VERSION ""

NS_ :

BS_:

BU_: VCU FCM

BO_ 1065 PKC_NM_0x429: 8 VCU
 SG_ PKC_SrcNodeID : 7|8@0+ (1,0) [0|127] ""  FCM
 SG_ PKC_CtrlBitVector_Bit0_RMR : 8|1@0+ (1,0) [0|1] ""  FCM
 SG_ PKC_CtrlBitVector_Bit1_Res : 9|1@0+ (1,0) [0|1] ""  FCM
 SG_ PKC_CtrlBitVector_Bit2_Res : 10|1@0+ (1,0) [0|1] ""  FCM
 SG_ PKC_CtrlBitVector_Bit3_NMCoord : 11|1@0+ (1,0) [0|1] ""  FCM
 SG_ PKC_CtrlBitVector_Bit4_ActWake : 12|1@0+ (1,0) [0|1] ""  FCM
 SG_ PKC_CtrlBitVector_Bit5_Res : 13|1@0+ (1,0) [0|1] ""  FCM
 SG_ PKC_CtrlBitVector_Bit6_PNI : 14|1@0+ (1,0) [0|1] ""  FCM
 SG_ PKC_CtrlBitVector_Bit7_Res : 15|1@0+ (1,0) [0|1] ""  FCM
 SG_ PKC_UsrData0 : 23|8@0+ (1,0) [0|255] ""  FCM
 SG_ PKC_UsrData1_Bit0_IGN_WAKEUP : 24|1@0+ (1,0) [0|1] ""  FCM
 SG_ PKC_UsrData1_Bit1_RESET_WAKEUP : 25|1@0+ (1,0) [0|1] ""  FCM
 SG_ PKC_UsrData1_Bit2_NETWORK_WAKEUP : 26|1@0+ (1,0) [0|1] ""  FCM
 SG_ PKC_UsrData1_Bit3_ECUSPEC_WAKEUP : 27|1@0+ (1,0) [0|1] ""  FCM
 SG_ PKC_UsrData1_Bit4_NETWORK_AWAKE : 28|1@0+ (1,0) [0|1] ""  FCM
 SG_ PKC_UsrData1_Bit5_IGNITION_AWAKE : 29|1@0+ (1,0) [0|1] ""  FCM
 SG_ PKC_UsrData1_Bit6_DIAGN_AWAKE : 30|1@0+ (1,0) [0|1] ""  FCM
 SG_ PKC_UsrData1_Bit7_ECUSPEC_AWAKE : 31|1@0+ (1,0) [0|1] ""  FCM
 SG_ PKC_UsrData2 : 39|8@0+ (1,0) [0|255] ""  FCM
 SG_ PKC_UsrData3 : 47|8@0+ (1,0) [0|255] ""  FCM
 SG_ PKC_UsrData4_PN_Info1 : 55|8@0+ (1,0) [0|255] ""  FCM
 SG_ PKC_UsrData5_PN_Info2 : 63|8@0+ (1,0) [0|255] ""  FCM

BO_ 1069 ADAS_NM_0x42D: 8 VCU
 SG_ ADAS_SrcNodeID : 7|8@0+ (1,0) [0|127] ""  FCM
 SG_ ADAS_CtrlBitVector_Bit0_RMR : 8|1@0+ (1,0) [0|1] ""  FCM
 SG_ ADAS_CtrlBitVector_Bit1_Res : 9|1@0+ (1,0) [0|1] ""  FCM
 SG_ ADAS_CtrlBitVector_Bit2_Res : 10|1@0+ (1,0) [0|1] ""  FCM
 SG_ ADAS_CtrlBitVector_Bit3_NMCoord : 11|1@0+ (1,0) [0|1] ""  FCM
 SG_ ADAS_CtrlBitVector_Bit4_ActWake : 12|1@0+ (1,0) [0|1] ""  FCM
 SG_ ADAS_CtrlBitVector_Bit5_Res : 13|1@0+ (1,0) [0|1] ""  FCM
 SG_ ADAS_CtrlBitVector_Bit6_PNI : 14|1@0+ (1,0) [0|1] ""  FCM
 SG_ ADAS_CtrlBitVector_Bit7_Res : 15|1@0+ (1,0) [0|1] ""  FCM
 SG_ ADAS_UsrData0 : 23|8@0+ (1,0) [0|255] ""  FCM
 SG_ ADAS_UsrData1_Bit0_IGN_WAKEUP : 24|1@0+ (1,0) [0|1] ""  FCM
 SG_ ADAS_UsrData1_Bit1_RESET_WAKEUP : 25|1@0+ (1,0) [0|1] ""  FCM
 SG_ ADAS_UsrData1_Bit2_NET_WKUP : 26|1@0+ (1,0) [0|1] ""  FCM
 SG_ ADAS_UsrData1_Bit3_ECUSPEC_WKUP : 27|1@0+ (1,0) [0|1] ""  FCM
 SG_ ADAS_UsrData1_Bit4_NETWORK_AWAKE : 28|1@0+ (1,0) [0|1] ""  FCM
 SG_ ADAS_UsrData1_Bit5_IGN_AWAKE : 29|1@0+ (1,0) [0|1] ""  FCM
 SG_ ADAS_UsrData1_Bit6_DIAGN_AWAKE : 30|1@0+ (1,0) [0|1] ""  FCM
 SG_ ADAS_UsrData1_Bit7_ECUSPEC_AWAKE : 31|1@0+ (1,0) [0|1] ""  FCM
 SG_ ADAS_UsrData2 : 39|8@0+ (1,0) [0|255] ""  FCM
 SG_ ADAS_UsrData3 : 47|8@0+ (1,0) [0|255] ""  FCM
 SG_ ADAS_UsrData4_PN_Info1 : 55|8@0+ (1,0) [0|255] ""  FCM
 SG_ ADAS_UsrData5_PN_Info2 : 63|8@0+ (1,0) [0|255] ""  FCM

BO_ 1070 FCM_NM_0x42E: 8 FCM
 SG_ FCM_SrcNodeID : 7|8@0+ (1,0) [0|127] ""  VCU
 SG_ FCM_CtrlBitVector_Bit0_RMR : 8|1@0+ (1,0) [0|1] ""  VCU
 SG_ FCM_CtrlBitVector_Bit1_Res : 9|1@0+ (1,0) [0|1] ""  VCU
 SG_ FCM_CtrlBitVector_Bit2_Res : 10|1@0+ (1,0) [0|1] ""  VCU
 SG_ FCM_CtrlBitVector_Bit3_NMCoord : 11|1@0+ (1,0) [0|1] ""  VCU
 SG_ FCM_CtrlBitVector_Bit4_ActWake : 12|1@0+ (1,0) [0|1] ""  VCU
 SG_ FCM_CtrlBitVector_Bit5_Res : 13|1@0+ (1,0) [0|1] ""  VCU
 SG_ FCM_CtrlBitVector_Bit6_PNI : 14|1@0+ (1,0) [0|1] ""  VCU
 SG_ FCM_CtrlBitVector_Bit7_Res : 15|1@0+ (1,0) [0|1] ""  VCU
 SG_ FCM_UsrData0 : 23|8@0+ (1,0) [0|255] ""  VCU
 SG_ FCM_UsrData1_Bit0_IGN_WAKEUP : 24|1@0+ (1,0) [0|1] ""  VCU
 SG_ FCM_UsrData1_Bit1_RESET_WAKEUP : 25|1@0+ (1,0) [0|1] ""  VCU
 SG_ FCM_UsrData1_Bit2_NETWORK_WAKEUP : 26|1@0+ (1,0) [0|1] ""  VCU
 SG_ FCM_UsrData1_Bit3_ECUSPEC_WAKEUP : 27|1@0+ (1,0) [0|1] ""  VCU
 SG_ FCM_UsrData1_Bit4_NETWORK_AWAKE : 28|1@0+ (1,0) [0|1] ""  VCU
 SG_ FCM_UsrData1_Bit5_IGNITION_AWAKE : 29|1@0+ (1,0) [0|1] ""  VCU
 SG_ FCM_UsrData1_Bit6_DIAGN_AWAKE : 30|1@0+ (1,0) [0|1] ""  VCU
 SG_ FCM_UsrData1_Bit7_ECUSPEC_AWAKE : 31|1@0+ (1,0) [0|1] ""  VCU
 SG_ FCM_UsrData2 : 39|8@0+ (1,0) [0|255] ""  VCU
 SG_ FCM_UsrData3 : 47|8@0+ (1,0) [0|255] ""  VCU
 SG_ FCM_UsrData4_PN_Info1 : 55|8@0+ (1,0) [0|255] ""  VCU
 SG_ FCM_UsrData5_PN_Info2 : 63|8@0+ (1,0) [0|255] ""  VCU

BO_ 1086 GW_NM_0x43E: 8 VCU
 SG_ GW_SrcNodeID : 7|8@0+ (1,0) [0|127] ""  FCM
 SG_ GW_CtrlBitVector_Bit0_RMR : 8|1@0+ (1,0) [0|1] ""  FCM
 SG_ GW_CtrlBitVector_Bit1_Res : 9|1@0+ (1,0) [0|1] ""  FCM
 SG_ GW_CtrlBitVector_Bit2_Res : 10|1@0+ (1,0) [0|1] ""  FCM
 SG_ GW_CtrlBitVector_Bit3_NMCoord : 11|1@0+ (1,0) [0|1] ""  FCM
 SG_ GW_CtrlBitVector_Bit4_ActWake : 12|1@0+ (1,0) [0|1] ""  FCM
 SG_ GW_CtrlBitVector_Bit5_Res : 13|1@0+ (1,0) [0|1] ""  FCM
 SG_ GW_CtrlBitVector_Bit6_PNI : 14|1@0+ (1,0) [0|1] ""  FCM
 SG_ GW_CtrlBitVector_Bit7_Res : 15|1@0+ (1,0) [0|1] ""  FCM
 SG_ GW_UsrData0 : 23|8@0+ (1,0) [0|255] ""  FCM
 SG_ GW_UsrData1_Bit0_IGN_WAKEUP : 24|1@0+ (1,0) [0|1] ""  FCM
 SG_ GW_UsrData1_Bit1_RESET_WAKEUP : 25|1@0+ (1,0) [0|1] ""  FCM
 SG_ GW_UsrData1_Bit2_NETWORK_WAKEUP : 26|1@0+ (1,0) [0|1] ""  FCM
 SG_ GW_UsrData1_Bit3_ECUSPEC_WAKEUP : 27|1@0+ (1,0) [0|1] ""  FCM
 SG_ GW_UsrData1_Bit4_NETWORK_AWAKE : 28|1@0+ (1,0) [0|1] ""  FCM
 SG_ GW_UsrData1_Bit5_IGNITION_AWAKE : 29|1@0+ (1,0) [0|1] ""  FCM
 SG_ GW_UsrData1_Bit6_DIAGN_AWAKE : 30|1@0+ (1,0) [0|1] ""  FCM
 SG_ GW_UsrData1_Bit7_ECUSPEC_AWAKE : 31|1@0+ (1,0) [0|1] ""  FCM
 SG_ GW_UsrData2 : 39|8@0+ (1,0) [0|255] ""  FCM
 SG_ GW_UsrData3 : 47|8@0+ (1,0) [0|255] ""  FCM
 SG_ GW_UsrData4_PN_Info1 : 55|8@0+ (1,0) [0|255] ""  FCM
 SG_ GW_UsrData5_PN_Info2 : 63|8@0+ (1,0) [0|255] ""  FCM

BO_ 1159 FCM_0x487: 8 FCM
 SG_ FCM_ComLostFlt_ESP : 0|1@0+ (1,0) [0|1] ""  VCU
 SG_ FCM_ComLostFlt_iBooster : 1|1@0+ (1,0) [0|1] ""  VCU
 SG_ FCM_ComLostFlt_EPS : 2|1@0+ (1,0) [0|1] ""  VCU
 SG_ FCM_ComLostFlt_YRS : 3|1@0+ (1,0) [0|1] ""  VCU
 SG_ FCM_ComLostFlt_BCM : 4|1@0+ (1,0) [0|1] ""  VCU
 SG_ FCM_ComLostFlt_ECC : 5|1@0+ (1,0) [0|1] ""  VCU
 SG_ FCM_ComLostFlt_TBOX : 6|1@0+ (1,0) [0|1] ""  VCU
 SG_ FCM_ComLostFlt_CIM : 7|1@0+ (1,0) [0|1] ""  VCU
 SG_ FCM_ComLostFlt_ICC : 8|1@0+ (1,0) [0|1] ""  VCU
 SG_ FCM_ComLostFlt_MRR : 9|1@0+ (1,0) [0|1] ""  VCU
 SG_ FCM_ComLostFlt_PEPS : 10|1@0+ (1,0) [0|1] ""  VCU
 SG_ FCM_ComLostFlt_ADAS : 11|1@0+ (1,0) [0|1] ""  VCU
 SG_ FCM_ComE2EFlt : 12|1@0+ (1,0) [0|1] ""  VCU
 SG_ FCM_ChkInvldSig_ESP : 13|1@0+ (1,0) [0|1] ""  VCU
 SG_ FCM_ChkInvldSig_iBooster : 14|1@0+ (1,0) [0|1] ""  VCU
 SG_ FCM_ChkInvldSig_EPS : 15|1@0+ (1,0) [0|1] ""  VCU
 SG_ FCM_ChkInvldSig_YRS : 16|1@0+ (1,0) [0|1] ""  VCU
 SG_ FCM_ChkInvldSig_CIM : 17|1@0+ (1,0) [0|1] ""  VCU
 SG_ FCM_ChkInvldSig_ECC : 18|1@0+ (1,0) [0|1] ""  VCU
 SG_ FCM_ChkInvldSig_PEPS : 19|1@0+ (1,0) [0|1] ""  VCU
 SG_ FCM_ChkInvldSig_ICC : 20|1@0+ (1,0) [0|1] ""  VCU
 SG_ FCM_ChkPrivateCANBusOff : 21|1@0+ (1,0) [0|1] ""  VCU
 SG_ FCM_ChkPublicCANBusOff : 22|1@0+ (1,0) [0|1] ""  VCU
 SG_ FCM_BattVoltBelowThd : 23|1@0+ (1,0) [0|1] ""  VCU
 SG_ FCM_BattVoltOverThd : 24|1@0+ (1,0) [0|1] ""  VCU
 SG_ FCM_CamBli : 25|1@0+ (1,0) [0|1] ""  VCU
 SG_ FCM_ECUTmpHiTProtn : 26|1@0+ (1,0) [0|1] ""  VCU
 SG_ FCM_IntCircOutpVoltBelowThd : 27|1@0+ (1,0) [0|1] ""  VCU
 SG_ FCM_IntCircOutpVoltOverThd : 28|1@0+ (1,0) [0|1] ""  VCU
 SG_ FCM_IntCircPrmntFlt : 29|1@0+ (1,0) [0|1] ""  VCU
 SG_ FCM_MatchParaErr : 30|1@0+ (1,0) [0|1] ""  VCU
 SG_ FCM_VehCfgInfoErr : 31|1@0+ (1,0) [0|1] ""  VCU
 SG_ FCM_IntCircFlt : 32|1@0+ (1,0) [0|1] ""  VCU
 SG_ FCM_DLCFlt_ESP : 33|1@0+ (1,0) [0|1] ""  VCU
 SG_ FCM_DLCFlt_iBooster : 34|1@0+ (1,0) [0|1] ""  VCU
 SG_ FCM_DLCFlt_EPS : 35|1@0+ (1,0) [0|1] ""  VCU
 SG_ FCM_DLCFlt_YRS : 36|1@0+ (1,0) [0|1] ""  VCU
 SG_ FCM_DLCFlt_BCM : 37|1@0+ (1,0) [0|1] ""  VCU
 SG_ FCM_DLCFlt_ECC : 38|1@0+ (1,0) [0|1] ""  VCU
 SG_ FCM_DLCFlt_TBOX : 39|1@0+ (1,0) [0|1] ""  VCU
 SG_ FCM_DLCFlt_CIM : 40|1@0+ (1,0) [0|1] ""  VCU
 SG_ FCM_DLCFlt_ICC : 41|1@0+ (1,0) [0|1] ""  VCU
 SG_ FCM_DLCFlt_MRR : 42|1@0+ (1,0) [0|1] ""  VCU
 SG_ FCM_DLCFlt_PEPS : 43|1@0+ (1,0) [0|1] ""  VCU
 SG_ FCM_DLCFlt_ADAS : 44|1@0+ (1,0) [0|1] ""  VCU
 SG_ FCM_OnlineCalOutOfRng : 45|1@0+ (1,0) [0|1] ""  VCU
 SG_ FCM_IniCalOutOfRng : 46|1@0+ (1,0) [0|1] ""  VCU
 SG_ FCM_IniCalTimeout : 47|1@0+ (1,0) [0|1] ""  VCU
 SG_ FCM_NotCal : 48|1@0+ (1,0) [0|1] ""  VCU
 SG_ FCM_OTARdy_Fb : 55|2@0+ (1,0) [0|3] ""  VCU

BO_ 1268 TBOX_0x4F4: 16 VCU
 SG_ TBOX_4F4_4F8_CheckSum : 7|8@0+ (1,0) [0|255] "" Vector__XXX
 SG_ TBOX_4F4_4F8_AliveCounter : 11|4@0+ (1,0) [0|14] "" Vector__XXX
 SG_ TBOX_Sw_upd : 13|2@0+ (1,0) [0|3] "" Vector__XXX
 SG_ TBOX_Flsflg : 18|3@0+ (1,0) [0|7] ""  FCM
 SG_ TBOX_RemFlsh : 21|3@0+ (1,0) [0|7] ""  FCM
 SG_ TBOX_FobdGWPartBUSUDSCom : 23|2@0+ (1,0) [0|3] "" Vector__XXX
 SG_ TBOX_RemChrgInsulFctReq : 25|2@0+ (1,0) [0|3] "" Vector__XXX
 SG_ TBOX_EHUSetTrvlMod : 27|2@0+ (1,0) [0|3] "" Vector__XXX
 SG_ TBOX_ResvACChrgOpenSts : 29|2@0+ (1,0) [0|3] "" Vector__XXX
 SG_ TBOX_RemKL15PwrOnReq : 31|2@0+ (1,0) [0|3] "" Vector__XXX
 SG_ TBOX_SetChrgEndSOC : 38|7@0+ (1,0) [0|100] "%" Vector__XXX
 SG_ TBOX_PreCondTriggerReq : 42|3@0+ (1,0) [0|7] "" Vector__XXX
 SG_ TBOX_BlowLvlReq : 45|3@0+ (1,0) [0|7] "" Vector__XXX
 SG_ TBOX_ICC_UpdStrt : 47|2@0+ (1,0) [0|3] "" Vector__XXX
 SG_ TBOX_VehiMod : 51|4@0+ (1,0) [0|15] "" Vector__XXX
 SG_ TBOX_Crash_cfm : 53|2@0+ (1,0) [0|3] "" Vector__XXX
 SG_ TBOX_SchedChrgnReq : 57|2@0+ (1,0) [0|3] "" Vector__XXX
 SG_ TBOX_4F4_SSecOC_Fresh_Byte0 : 71|8@0+ (1,0) [0|255] "" Vector__XXX
 SG_ TBOX_4F4_SSecOC_MAC_Byte0 : 79|8@0+ (1,0) [0|255] "" Vector__XXX
 SG_ TBOX_4F4_SSecOC_MAC_Byte1 : 87|8@0+ (1,0) [0|255] "" Vector__XXX
 SG_ TBOX_4F4_SSecOC_MAC_Byte2 : 95|8@0+ (1,0) [0|255] "" Vector__XXX

BO_ 1287 VCU_0x507: 8 VCU
 SG_ VCU_OTAVehInhb_QM_Fb : 5|2@0+ (1,0) [0|3] ""  FCM
 SG_ VCU_OTAVehCdnChk_QM_sts : 7|2@0+ (1,0) [0|3] ""  FCM
 SG_ VCU_DrvAvl : 8|1@0+ (1,0) [0|1] "" Vector__XXX
 SG_ VCU_CllsnSigSts : 9|1@0+ (1,0) [0|1] "" Vector__XXX
 SG_ VCU_VehSts_GB : 13|2@0+ (1,0) [0|3] "" Vector__XXX
 SG_ VCU_MCUOverTFlt_GB : 14|1@0+ (1,0) [0|1] "" Vector__XXX
 SG_ VCU_DrvrMotOverTFlt_GB : 15|1@0+ (1,0) [0|1] "" Vector__XXX
 SG_ VCU_SOCTooLoAlrm : 16|1@0+ (1,0) [0|1] "" Vector__XXX
 SG_ VCU_SOCJumpAlrm : 17|1@0+ (1,0) [0|1] "" Vector__XXX
 SG_ VCU_PwrBattPackMismatAlrm : 18|1@0+ (1,0) [0|1] "" Vector__XXX
 SG_ VCU_SOCTooHiAlrm : 19|1@0+ (1,0) [0|1] "" Vector__XXX
 SG_ VCU_DCDCEnaCmd : 20|1@0+ (1,0) [0|1] "" Vector__XXX
 SG_ VCU_PwrBattECCEnaCmd : 22|1@0+ (1,0) [0|1] "" Vector__XXX
 SG_ VCU_MstRlyCtrlCmd : 23|1@0+ (1,0) [0|1] "" Vector__XXX
 SG_ VCU_DCDCOutpVoltCmd : 31|8@0+ (0.1,0) [0|25.5] "V" Vector__XXX
 SG_ VCU_CCCnctnVolt : 39|8@0+ (0.1,0) [0|25.5] "V" Vector__XXX
 SG_ VCU_GearSig_GB : 43|4@0+ (1,0) [0|15] "" Vector__XXX
 SG_ VCU_DrvrMotNr_GB : 47|4@0+ (1,0) [0|15] "" Vector__XXX
 SG_ VCU_BattVolt : 55|16@0+ (0.001,0) [0|65.535] "V"  FCM

BO_ 1297 VCU_0x511: 8 VCU
 SG_ VCU_BMSLVWakeUpSts : 0|1@0+ (1,0) [0|1] "" Vector__XXX
 SG_ VCU_ONWakeUpSig : 1|1@0+ (1,0) [0|1] "" Vector__XXX
 SG_ VCU_FCWakeUpSig : 2|1@0+ (1,0) [0|1] "" Vector__XXX
 SG_ VCU_SCWakeUpSig : 3|1@0+ (1,0) [0|1] "" Vector__XXX
 SG_ VCU_RemWakeUpSig : 4|1@0+ (1,0) [0|1] "" Vector__XXX
 SG_ VCU_NetWakeUpSig : 5|1@0+ (1,0) [0|1] "" Vector__XXX
 SG_ VCU_LVWakeUpSts_PDU : 6|1@0+ (1,0) [0|1] "" Vector__XXX
 SG_ VCU_VehEOLFctFlg : 7|1@0+ (1,0) [0|1] "" Vector__XXX
 SG_ VCU_LVWakeUpSts_MCU : 8|1@0+ (1,0) [0|1] "" Vector__XXX
 SG_ VCU_PwrAntithefAllwtRdyFlg : 9|1@0+ (1,0) [0|1] "" Vector__XXX
 SG_ VCU_LVWakeUpSts_CCU : 10|1@0+ (1,0) [0|1] "" Vector__XXX
 SG_ VCU_RemECCEndCmd : 11|1@0+ (1,0) [0|1] "" Vector__XXX
 SG_ VCU_EvChrgElectcLockCtrlCmd : 13|2@0+ (1,0) [0|3] "" Vector__XXX
 SG_ VCU_RemPwrBattHeatgEndCmd : 14|1@0+ (1,0) [0|1] "" Vector__XXX
 SG_ VCU_RemChrgEndCmd : 15|1@0+ (1,0) [0|1] "" Vector__XXX
 SG_ VCU_V2L_TrAvl : 16|1@0+ (1,0) [0|1] "" Vector__XXX
 SG_ VCU_RemBattHeatgFailReason : 19|3@0+ (1,0) [0|7] "" Vector__XXX
 SG_ VCU_RemECCEndReason : 22|3@0+ (1,0) [0|7] "" Vector__XXX
 SG_ VCU_V2L_ChrgPortAvl : 23|1@0+ (1,0) [0|1] "" Vector__XXX
 SG_ VCU_RemChrgEndReason : 26|3@0+ (1,0) [0|7] "" Vector__XXX
 SG_ VCU_SchedChrgnStsFb : 28|2@0+ (1,0) [0|3] "" Vector__XXX
 SG_ VCU_V2V_Avl : 29|1@0+ (1,0) [0|1] "" Vector__XXX
 SG_ VCU_V2H_Avl : 30|1@0+ (1,0) [0|1] "" Vector__XXX
 SG_ VCU_V2G_Avl : 31|1@0+ (1,0) [0|1] "" Vector__XXX
 SG_ VCU_VehMod : 39|4@0+ (1,0) [0|15] ""  FCM
 SG_ VCU_VehCrtChrgEndSOC : 46|7@0+ (1,0) [0|100] "%" Vector__XXX
 SG_ VCU_CalSwVers : 52|5@0+ (1,0) [0|31] "" Vector__XXX
 SG_ VCU_RemPwrBattPreheatgEndFlg : 53|1@0+ (1,0) [0|1] "" Vector__XXX
 SG_ VCU_VehOperMod : 60|5@0+ (1,0) [0|31] "" Vector__XXX
 SG_ VCU_VehRemRefrshModReq : 62|2@0+ (1,0) [0|3] "" Vector__XXX
 SG_ VCU_RemDTCPwrOnReq : 63|1@0+ (1,0) [0|1] "" Vector__XXX

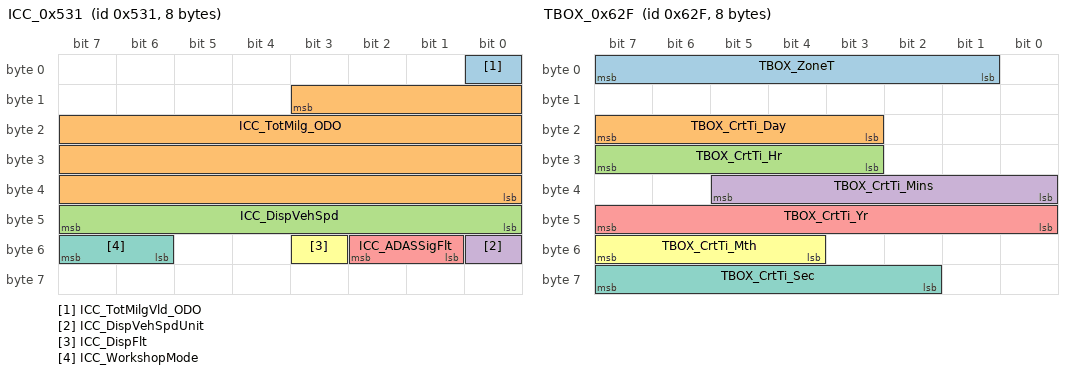
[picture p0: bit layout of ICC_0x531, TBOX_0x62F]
BO_ 1329 ICC_0x531: 8 VCU
 SG_ ICC_TotMilgVld_ODO : 0|1@0+ (1,0) [0|1] ""  FCM
 SG_ ICC_TotMilg_ODO : 11|28@0+ (0.01,0) [0|2000000] "km"  FCM
 SG_ ICC_DispVehSpd : 47|8@0+ (1,0) [0|255] ""  FCM
 SG_ ICC_DispVehSpdUnit : 48|1@0+ (1,0) [0|1] ""  FCM
 SG_ ICC_ADASSigFlt : 50|2@0+ (1,0) [0|3] ""  FCM
 SG_ ICC_DispFlt : 51|1@0+ (1,0) [0|1] ""  FCM
 SG_ ICC_WorkshopMode : 55|2@0+ (1,0) [0|3] "" Vector__XXX

BO_ 1476 TBOX_0x5C4: 16 VCU
 SG_ TBOX_OTA_ownCondchk : 1|2@0+ (1,0) [0|3] ""  FCM
 SG_ TBOX_TerminalRemWakeupSig : 2|1@0+ (1,0) [0|1] "" Vector__XXX
 SG_ TBOX_RemSCModReq : 4|2@0+ (1,0) [0|3] "" Vector__XXX
 SG_ TBOX_RemPwrBattOpenHeatgReq : 6|2@0+ (1,0) [0|3] "" Vector__XXX
 SG_ TBOX_RemPwrBattResvHeatgReq : 7|1@0+ (1,0) [0|1] "" Vector__XXX
 SG_ TBOX_RemInsdInfoDispEna : 12|1@0+ (1,0) [0|1] "" Vector__XXX
 SG_ TBOX_RemECCDefrstModReq : 14|2@0+ (1,0) [0|3] "" Vector__XXX
 SG_ TBOX_RemECCResvDefrstReq : 15|1@0+ (1,0) [0|1] "" Vector__XXX
 SG_ TBOX_RemECCSetT : 31|8@0+ (0.5,0) [0|127.5] "Degree Celsius" Vector__XXX
 SG_ TBOX_RemResvECCSetT : 39|8@0+ (0.5,0) [0|127.5] "Degree Celsius" Vector__XXX
 SG_ TBOX_RemSOCMax : 47|8@0+ (1,0) [0|100] "" Vector__XXX
 SG_ TBOX_4GSigIND : 49|2@0+ (1,0) [0|3] "" Vector__XXX
 SG_ TBOX_Conn_Typ : 52|3@0+ (1,0) [0|7] "" Vector__XXX
 SG_ TBOX_TSPNotConn : 53|1@0+ (1,0) [0|1] "" Vector__XXX
 SG_ TBOX_EHUNotCONN : 54|1@0+ (1,0) [0|1] "" Vector__XXX
 SG_ TBOX_WIFIError : 55|1@0+ (1,0) [0|1] "" Vector__XXX
 SG_ TBOX_InnerBattError : 56|1@0+ (1,0) [0|1] "" Vector__XXX
 SG_ TBOX_VoltLow : 57|1@0+ (1,0) [0|1] "" Vector__XXX
 SG_ TBOX_VoltHigh : 58|1@0+ (1,0) [0|1] "" Vector__XXX
 SG_ TBOX_4GLoss : 59|1@0+ (1,0) [0|1] "" Vector__XXX
 SG_ TBOX_RemSWH_Req : 61|2@0+ (1,0) [0|3] "" Vector__XXX
 SG_ TBOX_OTAInhbReq : 63|2@0+ (1,0) [0|3] "" Vector__XXX
 SG_ TBOX_5C4_SSecOC_Fresh_Byte0 : 71|8@0+ (1,0) [0|255] "" Vector__XXX
 SG_ TBOX_5C4_SSecOC_MAC_Byte0 : 79|8@0+ (1,0) [0|255] "" Vector__XXX
 SG_ TBOX_5C4_SSecOC_MAC_Byte1 : 87|8@0+ (1,0) [0|255] "" Vector__XXX
 SG_ TBOX_5C4_SSecOC_MAC_Byte2 : 95|8@0+ (1,0) [0|255] "" Vector__XXX

BO_ 1583 TBOX_0x62F: 8 VCU
 SG_ TBOX_ZoneT : 7|7@0+ (15,-720) [-720|1185] "min" Vector__XXX
 SG_ TBOX_CrtTi_Day : 23|5@0+ (1,1) [1|31] "day"  FCM
 SG_ TBOX_CrtTi_Hr : 31|5@0+ (1,0) [0|23] "hour"  FCM
 SG_ TBOX_CrtTi_Mins : 37|6@0+ (1,0) [0|59] "mintue"  FCM
 SG_ TBOX_CrtTi_Yr : 47|8@0+ (1,2015) [2015|2270] "year"  FCM
 SG_ TBOX_CrtTi_Mth : 55|4@0+ (1,1) [1|12] "month"  FCM
 SG_ TBOX_CrtTi_Sec : 63|6@0+ (1,0) [0|59] "second"  FCM

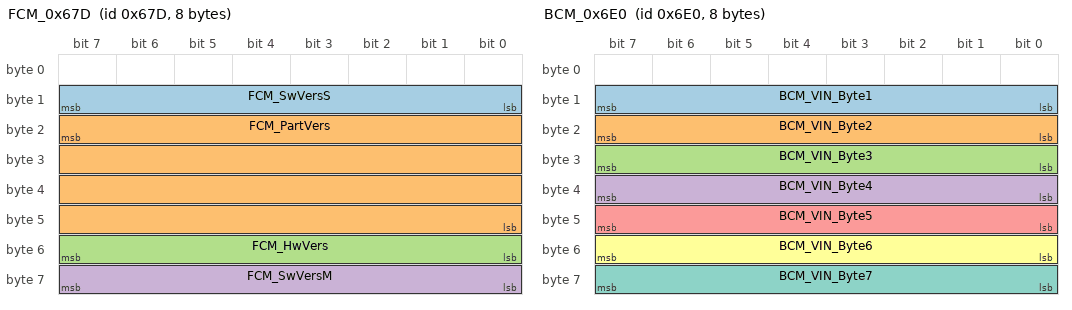
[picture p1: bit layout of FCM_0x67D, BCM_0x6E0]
BO_ 1661 FCM_0x67D: 8 FCM
 SG_ FCM_SwVersS : 15|8@0+ (1,0) [0|255] ""  VCU
 SG_ FCM_PartVers : 23|32@0+ (1,0) [0|4294967295] ""  VCU
 SG_ FCM_HwVers : 55|8@0+ (1,0) [0|255] ""  VCU
 SG_ FCM_SwVersM : 63|8@0+ (1,0) [0|255] ""  VCU

BO_ 1760 BCM_0x6E0: 8 VCU
 SG_ BCM_VIN_Byte1 : 15|8@0+ (1,0) [0|255] ""  FCM
 SG_ BCM_VIN_Byte2 : 23|8@0+ (1,0) [0|255] ""  FCM
 SG_ BCM_VIN_Byte3 : 31|8@0+ (1,0) [0|255] ""  FCM
 SG_ BCM_VIN_Byte4 : 39|8@0+ (1,0) [0|255] ""  FCM
 SG_ BCM_VIN_Byte5 : 47|8@0+ (1,0) [0|255] ""  FCM
 SG_ BCM_VIN_Byte6 : 55|8@0+ (1,0) [0|255] ""  FCM
 SG_ BCM_VIN_Byte7 : 63|8@0+ (1,0) [0|255] ""  FCM

BO_ 1765 VCU_0x6E5: 8 VCU
 SG_ VCU_VINCod1 : 7|64@0+ (1,0) [0|16777215] ""  FCM

BO_ 1766 VCU_0x6E6: 8 VCU
 SG_ VCU_VINCod2 : 7|64@0+ (1,0) [0|16777215] ""  FCM

BO_ 1767 VCU_0x6E7: 8 VCU
 SG_ VCU_VINCod3 : 7|64@0+ (1,0) [0|16777215] ""  FCM

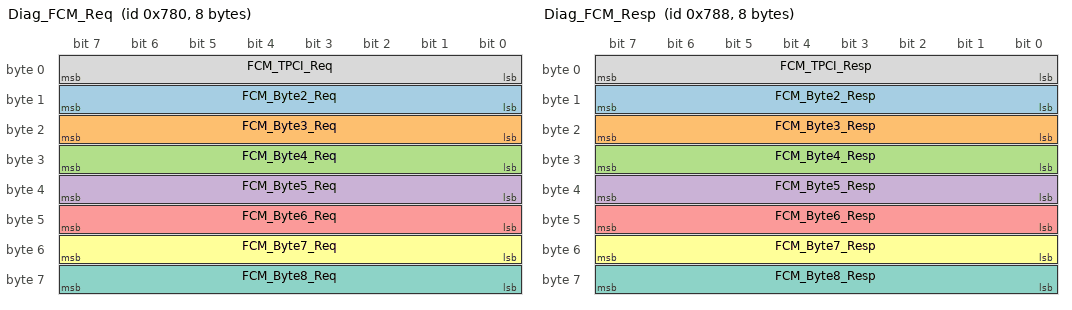
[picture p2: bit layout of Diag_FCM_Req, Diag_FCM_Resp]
BO_ 1920 Diag_FCM_Req: 8 VCU
 SG_ FCM_Byte2_Req : 15|8@0+ (1,0) [0|255] ""  FCM
 SG_ FCM_Byte3_Req : 23|8@0+ (1,0) [0|255] ""  FCM
 SG_ FCM_Byte4_Req : 31|8@0+ (1,0) [0|255] ""  FCM
 SG_ FCM_Byte5_Req : 39|8@0+ (1,0) [0|255] ""  FCM
 SG_ FCM_Byte6_Req : 47|8@0+ (1,0) [0|255] ""  FCM
 SG_ FCM_Byte7_Req : 55|8@0+ (1,0) [0|255] ""  FCM
 SG_ FCM_Byte8_Req : 63|8@0+ (1,0) [0|255] ""  FCM
 SG_ FCM_TPCI_Req : 7|8@0+ (1,0) [0|255] ""  FCM

BO_ 1928 Diag_FCM_Resp: 8 FCM
 SG_ FCM_Byte2_Resp : 15|8@0+ (1,0) [0|255] ""  VCU
 SG_ FCM_Byte3_Resp : 23|8@0+ (1,0) [0|255] ""  VCU
 SG_ FCM_Byte4_Resp : 31|8@0+ (1,0) [0|255] ""  VCU
 SG_ FCM_Byte5_Resp : 39|8@0+ (1,0) [0|255] ""  VCU
 SG_ FCM_Byte6_Resp : 47|8@0+ (1,0) [0|255] ""  VCU
 SG_ FCM_Byte7_Resp : 55|8@0+ (1,0) [0|255] ""  VCU
 SG_ FCM_Byte8_Resp : 63|8@0+ (1,0) [0|255] ""  VCU
 SG_ FCM_TPCI_Resp : 7|8@0+ (1,0) [0|255] ""  VCU

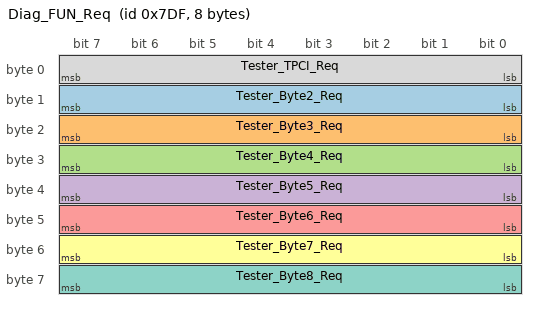
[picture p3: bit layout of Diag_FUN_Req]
BO_ 2015 Diag_FUN_Req: 8 VCU
 SG_ Tester_Byte2_Req : 15|8@0+ (1,0) [0|255] ""  FCM
 SG_ Tester_Byte3_Req : 23|8@0+ (1,0) [0|255] ""  FCM
 SG_ Tester_Byte4_Req : 31|8@0+ (1,0) [0|255] ""  FCM
 SG_ Tester_Byte5_Req : 39|8@0+ (1,0) [0|255] ""  FCM
 SG_ Tester_Byte6_Req : 47|8@0+ (1,0) [0|255] ""  FCM
 SG_ Tester_Byte7_Req : 55|8@0+ (1,0) [0|255] ""  FCM
 SG_ Tester_Byte8_Req : 63|8@0+ (1,0) [0|255] ""  FCM
 SG_ Tester_TPCI_Req : 7|8@0+ (1,0) [0|255] ""  FCM

CM_ SG_ 1065 PKC_SrcNodeID "Network Management Signal";
CM_ SG_ 1065 PKC_CtrlBitVector_Bit0_RMR "Network Management Signal: Repeat Message Request";
CM_ SG_ 1065 PKC_CtrlBitVector_Bit1_Res "Network Management Signal: Reserved (Legacy NM Coordinator ID) LowByte";
CM_ SG_ 1065 PKC_CtrlBitVector_Bit2_Res "Network Management Signal: Reserved (Legacy NM Coordinator ID) HighByte";
CM_ SG_ 1065 PKC_CtrlBitVector_Bit3_NMCoord "Network Management Signal: NM Coordinator Sleep Bit";
CM_ SG_ 1065 PKC_CtrlBitVector_Bit4_ActWake "Network Management Signal: Active Wakeup Bit";
CM_ SG_ 1065 PKC_CtrlBitVector_Bit5_Res "Network Management Signal: Reserved";
CM_ SG_ 1065 PKC_CtrlBitVector_Bit6_PNI "Network Management Signal: Partial Network Information Bit (PNI)";
CM_ SG_ 1065 PKC_CtrlBitVector_Bit7_Res "Network Management Signal: Reserved";
CM_ SG_ 1065 PKC_UsrData0 "The first user data byte determines the functionality of user data.This value is used as a constant that determines how the remaining three user data bytes are interpret the content of the remaining three user data bytes.";
CM_ SG_ 1065 PKC_UsrData1_Bit0_IGN_WAKEUP "Network Management Signal: ECU was power off or Bus sleep mode and started by Ignition turn on";
CM_ SG_ 1065 PKC_UsrData1_Bit1_RESET_WAKEUP "Network Management Signal: If ECU was already awake, in Prepare Bus Sleep or Ready Sleep mode and re-started by an internal or an external reset.";
CM_ SG_ 1065 PKC_UsrData1_Bit2_NETWORK_WAKEUP "Network Management Signal: ECU was in Power off, Bus Sleep, Prepare Bus Sleep or Ready Sleep Mode and then re-started by a network communication.";
CM_ SG_ 1065 PKC_UsrData1_Bit3_ECUSPEC_WAKEUP "Network Management Signal: ECU was in power off, Bus Sleep, Prepare Bus Sleep or Ready Sleep mode or awake and re- started by ECU-specific reason (e.g. pressed Button, timer, etc.)";
CM_ SG_ 1065 PKC_UsrData1_Bit4_NETWORK_AWAKE "Network Management Signal: ECU need network communication and keeps the network awake";
CM_ SG_ 1065 PKC_UsrData1_Bit5_IGNITION_AWAKE "Network Management Signal: ECU can?t release communication because Ignition is turn on";
CM_ SG_ 1065 PKC_UsrData1_Bit6_DIAGN_AWAKE "Network Management Signal: ECU need communication for diagnostic purpose and keeps network awake.";
CM_ SG_ 1065 PKC_UsrData1_Bit7_ECUSPEC_AWAKE "Network Management Signal: ECU keeps the network awake for ECU-define reasons for which communication is needed";
CM_ SG_ 1065 PKC_UsrData2 "Network Management Signal";
CM_ SG_ 1065 PKC_UsrData3 "Network Management Signal";
CM_ SG_ 1065 PKC_UsrData4_PN_Info1 "Network Management Signal";
CM_ SG_ 1065 PKC_UsrData5_PN_Info2 "Network Management Signal";
CM_ SG_ 1069 ADAS_SrcNodeID "Network Management Signal";
CM_ SG_ 1069 ADAS_CtrlBitVector_Bit0_RMR "Network Management Signal: Repeat Message Request";
CM_ SG_ 1069 ADAS_CtrlBitVector_Bit1_Res "Network Management Signal: Reserved (Legacy NM Coordinator ID) LowByte";
CM_ SG_ 1069 ADAS_CtrlBitVector_Bit2_Res "Network Management Signal: Reserved (Legacy NM Coordinator ID) HighByte";
CM_ SG_ 1069 ADAS_CtrlBitVector_Bit3_NMCoord "Network Management Signal: NM Coordinator Sleep Bit";
CM_ SG_ 1069 ADAS_CtrlBitVector_Bit4_ActWake "Network Management Signal: Active Wakeup Bit";
CM_ SG_ 1069 ADAS_CtrlBitVector_Bit5_Res "Network Management Signal: Reserved";
CM_ SG_ 1069 ADAS_CtrlBitVector_Bit6_PNI "Network Management Signal: Partial Network Information Bit (PNI)";
CM_ SG_ 1069 ADAS_CtrlBitVector_Bit7_Res "Network Management Signal: Reserved";
CM_ SG_ 1069 ADAS_UsrData0 "The first user data byte determines the functionality of user data.This value is used as a constant that determines how the remaining three user data bytes are interpret the content of the remaining three user data bytes.";
CM_ SG_ 1069 ADAS_UsrData1_Bit0_IGN_WAKEUP "Network Management Signal: ECU was power off or Bus sleep mode and started by Ignition turn on";
CM_ SG_ 1069 ADAS_UsrData1_Bit1_RESET_WAKEUP "Network Management Signal: If ECU was already awake, in Prepare Bus Sleep or Ready Sleep mode and re-started by an internal or an external reset.";
CM_ SG_ 1069 ADAS_UsrData1_Bit2_NET_WKUP "Network Management Signal: ECU was in Power off, Bus Sleep, Prepare Bus Sleep or Ready Sleep Mode and then re-started by a network communication.";
CM_ SG_ 1069 ADAS_UsrData1_Bit3_ECUSPEC_WKUP "Network Management Signal: ECU was in power off, Bus Sleep, Prepare Bus Sleep or Ready Sleep mode or awake and re- started by ECU-specific reason (e.g. pressed Button, timer, etc.)";
CM_ SG_ 1069 ADAS_UsrData1_Bit4_NETWORK_AWAKE "Network Management Signal: ECU need network communication and keeps the network awake";
CM_ SG_ 1069 ADAS_UsrData1_Bit5_IGN_AWAKE "Network Management Signal: ECU can?t release communication because Ignition is turn on";
CM_ SG_ 1069 ADAS_UsrData1_Bit6_DIAGN_AWAKE "Network Management Signal: ECU need communication for diagnostic purpose and keeps network awake.";
CM_ SG_ 1069 ADAS_UsrData1_Bit7_ECUSPEC_AWAKE "Network Management Signal: ECU keeps the network awake for ECU-define reasons for which communication is needed";
CM_ SG_ 1069 ADAS_UsrData2 "Network Management Signal";
CM_ SG_ 1069 ADAS_UsrData3 "Network Management Signal";
CM_ SG_ 1069 ADAS_UsrData4_PN_Info1 "Network Management Signal";
CM_ SG_ 1069 ADAS_UsrData5_PN_Info2 "Network Management Signal";
CM_ BO_ 1070 "Tx Rate is 64 ms.";
CM_ SG_ 1070 FCM_SrcNodeID "Network Management Signal";
CM_ SG_ 1070 FCM_CtrlBitVector_Bit0_RMR "Network Management Signal: Repeat Message Request";
CM_ SG_ 1070 FCM_CtrlBitVector_Bit1_Res "Network Management Signal: Reserved (Legacy NM Coordinator ID) LowByte";
CM_ SG_ 1070 FCM_CtrlBitVector_Bit2_Res "Network Management Signal: Reserved (Legacy NM Coordinator ID) HighByte";
CM_ SG_ 1070 FCM_CtrlBitVector_Bit3_NMCoord "Network Management Signal: NM Coordinator Sleep Bit";
CM_ SG_ 1070 FCM_CtrlBitVector_Bit4_ActWake "Network Management Signal: Active Wakeup Bit";
CM_ SG_ 1070 FCM_CtrlBitVector_Bit5_Res "Network Management Signal: Reserved";
CM_ SG_ 1070 FCM_CtrlBitVector_Bit6_PNI "Network Management Signal: Partial Network Information Bit (PNI)";
CM_ SG_ 1070 FCM_CtrlBitVector_Bit7_Res "Network Management Signal: Reserved";
CM_ SG_ 1070 FCM_UsrData0 "The first user data byte determines the functionality of user data.This value is used as a constant that determines how the remaining three user data bytes are interpret the content of the remaining three user data bytes.";
CM_ SG_ 1070 FCM_UsrData1_Bit0_IGN_WAKEUP "Network Management Signal: ECU was power off or Bus sleep mode and started by Ignition turn on";
CM_ SG_ 1070 FCM_UsrData1_Bit1_RESET_WAKEUP "Network Management Signal: If ECU was already awake, in Prepare Bus Sleep or Ready Sleep mode and re-started by an internal or an external reset.";
CM_ SG_ 1070 FCM_UsrData1_Bit2_NETWORK_WAKEUP "Network Management Signal: ECU was in Power off, Bus Sleep, Prepare Bus Sleep or Ready Sleep Mode and then re-started by a network communication.";
CM_ SG_ 1070 FCM_UsrData1_Bit3_ECUSPEC_WAKEUP "Network Management Signal: ECU was in power off, Bus Sleep, Prepare Bus Sleep or Ready Sleep mode or awake and re- started by ECU-specific reason (e.g. pressed Button, timer, etc.)";
CM_ SG_ 1070 FCM_UsrData1_Bit4_NETWORK_AWAKE "Network Management Signal: ECU need network communication and keeps the network awake";
CM_ SG_ 1070 FCM_UsrData1_Bit5_IGNITION_AWAKE "Network Management Signal: ECU can?t release communication because Ignition is turn on";
CM_ SG_ 1070 FCM_UsrData1_Bit6_DIAGN_AWAKE "Network Management Signal: ECU need communication for diagnostic purpose and keeps network awake.";
CM_ SG_ 1070 FCM_UsrData1_Bit7_ECUSPEC_AWAKE "Network Management Signal: ECU keeps the network awake for ECU-define reasons for which communication is needed";
CM_ SG_ 1070 FCM_UsrData2 "Network Management Signal";
CM_ SG_ 1070 FCM_UsrData3 "Network Management Signal";
CM_ SG_ 1070 FCM_UsrData4_PN_Info1 "Network Management Signal";
CM_ SG_ 1070 FCM_UsrData5_PN_Info2 "Network Management Signal";
CM_ BO_ 1086 "Tx Rate is 64 ms.";
CM_ SG_ 1086 GW_SrcNodeID "Network Management Signal";
CM_ SG_ 1086 GW_CtrlBitVector_Bit0_RMR "Network Management Signal: Repeat Message Request";
CM_ SG_ 1086 GW_CtrlBitVector_Bit1_Res "Network Management Signal: Reserved (Legacy NM Coordinator ID) LowByte";
CM_ SG_ 1086 GW_CtrlBitVector_Bit2_Res "Network Management Signal: Reserved (Legacy NM Coordinator ID) HighByte";
CM_ SG_ 1086 GW_CtrlBitVector_Bit3_NMCoord "Network Management Signal: NM Coordinator Sleep Bit";
CM_ SG_ 1086 GW_CtrlBitVector_Bit4_ActWake "Network Management Signal: Active Wakeup Bit";
CM_ SG_ 1086 GW_CtrlBitVector_Bit5_Res "Network Management Signal: Reserved";
CM_ SG_ 1086 GW_CtrlBitVector_Bit6_PNI "Network Management Signal: Partial Network Information Bit (PNI)";
CM_ SG_ 1086 GW_CtrlBitVector_Bit7_Res "Network Management Signal: Reserved";
CM_ SG_ 1086 GW_UsrData0 "The first user data byte determines the functionality of user data.This value is used as a constant that determines how the remaining three user data bytes are interpret the content of the remaining three user data bytes.";
CM_ SG_ 1086 GW_UsrData1_Bit0_IGN_WAKEUP "Network Management Signal: ECU was power off or Bus sleep mode and started by Ignition turn on";
CM_ SG_ 1086 GW_UsrData1_Bit1_RESET_WAKEUP "Network Management Signal: If ECU was already awake, in Prepare Bus Sleep or Ready Sleep mode and re-started by an internal or an external reset.";
CM_ SG_ 1086 GW_UsrData1_Bit2_NETWORK_WAKEUP "Network Management Signal: ECU was in Power off, Bus Sleep, Prepare Bus Sleep or Ready Sleep Mode and then re-started by a network communication.";
CM_ SG_ 1086 GW_UsrData1_Bit3_ECUSPEC_WAKEUP "Network Management Signal: ECU was in power off, Bus Sleep, Prepare Bus Sleep or Ready Sleep mode or awake and re- started by ECU-specific reason (e.g. pressed Button, timer, etc.)";
CM_ SG_ 1086 GW_UsrData1_Bit4_NETWORK_AWAKE "Network Management Signal: ECU need network communication and keeps the network awake";
CM_ SG_ 1086 GW_UsrData1_Bit5_IGNITION_AWAKE "Network Management Signal: ECU can’t release communication because Ignition is turn on";
CM_ SG_ 1086 GW_UsrData1_Bit6_DIAGN_AWAKE "Network Management Signal: ECU need communication for diagnostic purpose and keeps network awake.";
CM_ SG_ 1086 GW_UsrData1_Bit7_ECUSPEC_AWAKE "Network Management Signal: ECU keeps the network awake for ECU-define reasons for which communication is needed";
CM_ SG_ 1086 GW_UsrData2 "Network Management Signal";
CM_ SG_ 1086 GW_UsrData3 "Network Management Signal";
CM_ SG_ 1086 GW_UsrData4_PN_Info1 "Network Management Signal";
CM_ SG_ 1086 GW_UsrData5_PN_Info2 "Network Management Signal";
CM_ SG_ 1159 FCM_ComLostFlt_ESP "Malle_U30CF87_E00";
CM_ SG_ 1159 FCM_ComLostFlt_iBooster "Missed communication between FCM and iBooster_U30E287_E00";
CM_ SG_ 1159 FCM_ComLostFlt_EPS "FCM and EPS communication loss faila_U30CC87_E00";
CM_ SG_ 1159 FCM_ComLostFlt_YRS "Malfunction of loss of FCM and YRS communication_U30E387_E00";
CM_ SG_ 1159 FCM_ComLostFlt_BCM "Fail lost communication between FCM and BCM_U30C487_E00";
CM_ SG_ 1159 FCM_ComLostFlt_ECC "Lost communication between FCM and ECC_U30E487_E00";
CM_ SG_ 1159 FCM_ComLostFlt_TBOX "Fail loss of FCM and TBOX communication_U30D887_E00";
CM_ SG_ 1159 FCM_ComLostFlt_CIM "Fail loss of FCM and CIM communication_U30E587_E00";
CM_ SG_ 1159 FCM_ComLostFlt_ICC "Malfunction of lost communication between FCM and ICC_U30E687_E00";
CM_ SG_ 1159 FCM_ComLostFlt_MRR "Fail loss of FCM and MRR communication_U30EA87_E00";
CM_ SG_ 1159 FCM_ComLostFlt_PEPS "Missing communication failure between FCM and PEPS_U30E787_E00";
CM_ SG_ 1159 FCM_ComLostFlt_ADAS "Fail loss of communication between FCM and ADAS_U30EB87_E00";
CM_ SG_ 1159 FCM_ComE2EFlt "FCM communication check fault_C10E08_E00";
CM_ SG_ 1159 FCM_ChkInvldSig_ESP "The ESP signal of FCM is invalid_C10E586_E00";
CM_ SG_ 1159 FCM_ChkInvldSig_iBooster "The FCM iBooster signal invalid_C10E686_E00";
CM_ SG_ 1159 FCM_ChkInvldSig_EPS "The FCM check EPS signal invalid_C10E786_E00";
CM_ SG_ 1159 FCM_ChkInvldSig_YRS "The FCM check YRS signal invalid_C10E886_E00";
CM_ SG_ 1159 FCM_ChkInvldSig_CIM "Fail CIM signal detected by FCM_C10EA86_E00";
CM_ SG_ 1159 FCM_ChkInvldSig_ECC "The EC86_E00 EC86_C10";
CM_ SG_ 1159 FCM_ChkInvldSig_PEPS "The PEPS check signal of FCM is invalid_C10ED86_E00";
CM_ SG_ 1159 FCM_ChkInvldSig_ICC "The ICC signal detected by FCM is invalid_C10EB86_E00";
CM_ SG_ 1159 FCM_ChkPrivateCANBusOff "FCM check the private CAN bus shutdown_U30E888_E00";
CM_ SG_ 1159 FCM_ChkPublicCANBusOff "FCM check the public CAN bus shutdown_U30E988_E00";
CM_ SG_ 1159 FCM_BattVoltBelowThd "Low voltage of FCM inspection battery_C10E016_E00";
CM_ SG_ 1159 FCM_BattVoltOverThd "Overvoltage of FCM inspection battery_C10E017_E00";
CM_ SG_ 1159 FCM_CamBli "FCM camera occlusion_C10EF97_E00";
CM_ SG_ 1159 FCM_ECUTmpHiTProtn "FCM inspection ECU temporary high temperature protection_C10F098_E00";
CM_ SG_ 1159 FCM_IntCircOutpVoltBelowThd "FCM internal circuit output voltage low_C10F116_E00";
CM_ SG_ 1159 FCM_IntCircOutpVoltOverThd "FCM internal circuit output voltage H_C10F117_E00";
CM_ SG_ 1159 FCM_IntCircPrmntFlt "Permanent failure of FCM internal circuit_C10F149_E00";
CM_ SG_ 1159 FCM_MatchParaErr "FCM matching parameter incorrect_C10F262_E00";
CM_ SG_ 1159 FCM_VehCfgInfoErr "FCM Verify vehicle configuration information Error_C10F355_E00";
CM_ SG_ 1159 FCM_IntCircFlt "Fail internal FCM circuit_C10F449_E00";
CM_ SG_ 1159 FCM_DLCFlt_ESP "FCM Check ESP Data Length Code Fault_C10E581_E00";
CM_ SG_ 1159 FCM_DLCFlt_iBooster "FCM check iBooster data length code fault_C10E681_E00";
CM_ SG_ 1159 FCM_DLCFlt_EPS "FCM check EPS data length code fault_C10E781_E00";
CM_ SG_ 1159 FCM_DLCFlt_YRS "FCM Check YRS Data Length Coding Fault_C10E881_E00";
CM_ SG_ 1159 FCM_DLCFlt_BCM "FCM Check BCM Data Length Code Fault_C10E981_E00";
CM_ SG_ 1159 FCM_DLCFlt_ECC "FCM Verify ECC Data Length Coding Fault_C10EC81_E00";
CM_ SG_ 1159 FCM_DLCFlt_TBOX "FCM Check TBOX Data Length Code Fault_C10F581_E00";
CM_ SG_ 1159 FCM_DLCFlt_CIM "FCM Check CIM Data Length Code Fault_C10EA81_E00";
CM_ SG_ 1159 FCM_DLCFlt_ICC "FCM Check ICC Data Length Coding Fault_C10EB81_E00";
CM_ SG_ 1159 FCM_DLCFlt_MRR "FCM Check MRR Data Length Code Fault_C10F681_E00";
CM_ SG_ 1159 FCM_DLCFlt_PEPS "FCM Check PEPS Data Length Coding Fault_C10ED81_E00";
CM_ SG_ 1159 FCM_DLCFlt_ADAS "FCM Check ADAS Data Length Code Fault_C10F781_E00";
CM_ SG_ 1159 FCM_OnlineCalOutOfRng "FCM online calibration out of range_C10E384_E00";
CM_ SG_ 1159 FCM_IniCalOutOfRng "FCM initial calibration out of range_C10E385_E00";
CM_ SG_ 1159 FCM_IniCalTimeout "FCM initial calibration timeout_C10E363_E00";
CM_ SG_ 1159 FCM_NotCal "FCM uncalibration_C10E354_E00";
CM_ SG_ 1159 FCM_OTARdy_Fb "FCM OTA ready status feedback";
CM_ SG_ 1268 TBOX_4F4_4F8_CheckSum "TBOX_4F8_message checksum ( E2E data ID:0xC2 )";
CM_ SG_ 1268 TBOX_4F4_4F8_AliveCounter "TBOX_4F8_message counter";
CM_ SG_ 1268 TBOX_Flsflg "TBOX Flash flag";
CM_ SG_ 1268 TBOX_FobdGWPartBUSUDSCom "Forbidden UDS communication of some network segments of GW";
CM_ SG_ 1268 TBOX_RemChrgInsulFctReq "Remote charging insulation function request";
CM_ SG_ 1268 TBOX_EHUSetTrvlMod "TBOX Setup Travel Mode";
CM_ SG_ 1268 TBOX_ResvACChrgOpenSts "TBOX reservation AC charging on state";
CM_ SG_ 1268 TBOX_RemKL15PwrOnReq "TBOX remote KL15 power-on request";
CM_ SG_ 1268 TBOX_SetChrgEndSOC "TBOX Set charge cut-off SOC value";
CM_ SG_ 1268 TBOX_PreCondTriggerReq "TBOX sends a trigger [PreCondTrigger] to start pre-conditioning to VCU";
CM_ SG_ 1268 TBOX_BlowLvlReq "TBOX send blowlevel to ECC";
CM_ SG_ 1268 TBOX_VehiMod "Vehicle Mode(TBD)";
CM_ SG_ 1268 TBOX_Crash_cfm "Crash comfirm signal from TBOX to ESP.";
CM_ SG_ 1268 TBOX_SchedChrgnReq "TBOX send the Scheduled Charging Request to VCU";
CM_ SG_ 1268 TBOX_4F4_SSecOC_Fresh_Byte0 "Short SecOC Fresh signal byte 0 on CAN";
CM_ SG_ 1268 TBOX_4F4_SSecOC_MAC_Byte0 "Short SecOC MAC signal byte 0 on CAN";
CM_ SG_ 1268 TBOX_4F4_SSecOC_MAC_Byte1 "Short SecOC MAC signal byte 1 on CAN";
CM_ SG_ 1268 TBOX_4F4_SSecOC_MAC_Byte2 "Short SecOC MAC signal byte 2 on CAN";
CM_ SG_ 1287 VCU_OTAVehInhb_QM_Fb "QM group OTA vehicle Inhibit feedback";
CM_ SG_ 1287 VCU_OTAVehCdnChk_QM_sts "QM group OTA vehicle condition check status";
CM_ SG_ 1287 VCU_DrvAvl "Driving effective";
CM_ SG_ 1287 VCU_CllsnSigSts "Impact signal state_P103C00_E03";
CM_ SG_ 1287 VCU_VehSts_GB "Vehicle state (national standard)";
CM_ SG_ 1287 VCU_MCUOverTFlt_GB "MCU over-temperature fault (national standard)";
CM_ SG_ 1287 VCU_DrvrMotOverTFlt_GB "Over temperature fault of driving motor (national standard)";
CM_ SG_ 1287 VCU_SOCTooLoAlrm "Alarm if SOC is too low_P101221_E00";
CM_ SG_ 1287 VCU_SOCJumpAlrm "SOC jump alarming_P101327_E00";
CM_ SG_ 1287 VCU_PwrBattPackMismatAlrm "Power pack mismatch alarming_P101101_E00";
CM_ SG_ 1287 VCU_SOCTooHiAlrm "Overhigh SOC alarm_P101222_E00";
CM_ SG_ 1287 VCU_DCDCEnaCmd "DCDC Enable Command";
CM_ SG_ 1287 VCU_PwrBattECCEnaCmd "Power battery air conditioning system enable command";
CM_ SG_ 1287 VCU_MstRlyCtrlCmd "VCU main relay control command";
CM_ SG_ 1287 VCU_DCDCOutpVoltCmd "DCDC output voltage command";
CM_ SG_ 1287 VCU_CCCnctnVolt "CC connection voltage value";
CM_ SG_ 1287 VCU_GearSig_GB "Gear signal (national standard)";
CM_ SG_ 1287 VCU_DrvrMotNr_GB "Number of driving motors (national standard)";
CM_ SG_ 1287 VCU_BattVolt "Battery voltage";
CM_ SG_ 1297 VCU_BMSLVWakeUpSts "BMS low-voltage wake-up state";
CM_ SG_ 1297 VCU_ONWakeUpSig "ON gear wake-up signal";
CM_ SG_ 1297 VCU_FCWakeUpSig "Fast charging wake-up signal";
CM_ SG_ 1297 VCU_SCWakeUpSig "Slow charging wake-up signal";
CM_ SG_ 1297 VCU_RemWakeUpSig "Remote wake-up signal";
CM_ SG_ 1297 VCU_NetWakeUpSig "Network wake-up signal";
CM_ SG_ 1297 VCU_LVWakeUpSts_PDU "Low-voltage wake-up state of PDU";
CM_ SG_ 1297 VCU_VehEOLFctFlg "Vehicle EOL function flag position";
CM_ SG_ 1297 VCU_LVWakeUpSts_MCU "MCU low-voltage wake-up state";
CM_ SG_ 1297 VCU_PwrAntithefAllwtRdyFlg "Power anti-theft allowable READY flag position";
CM_ SG_ 1297 VCU_LVWakeUpSts_CCU "CCU low-voltage wake-up state";
CM_ SG_ 1297 VCU_RemECCEndCmd "Remote A/C end instruction";
CM_ SG_ 1297 VCU_EvChrgElectcLockCtrlCmd "EV charge inlet electronic lock command";
CM_ SG_ 1297 VCU_RemPwrBattHeatgEndCmd "Remote traction battery heating end command";
CM_ SG_ 1297 VCU_RemChrgEndCmd "Remote charging end command";
CM_ SG_ 1297 VCU_V2L_TrAvl "V2L Trunk Available from VCU";
CM_ SG_ 1297 VCU_RemBattHeatgFailReason "Failure reason of remote battery heating";
CM_ SG_ 1297 VCU_RemECCEndReason "End reason of remote A/C";
CM_ SG_ 1297 VCU_V2L_ChrgPortAvl "V2L Charge Port Available";
CM_ SG_ 1297 VCU_RemChrgEndReason "End reason of remote charging";
CM_ SG_ 1297 VCU_SchedChrgnStsFb "VCU Feedback the scheduled Charging progress/status to TBOX";
CM_ SG_ 1297 VCU_V2V_Avl "VCU_V2VAvailable";
CM_ SG_ 1297 VCU_V2H_Avl "VCU_V2HAvailable";
CM_ SG_ 1297 VCU_V2G_Avl "VCU_V2GAvailable";
CM_ SG_ 1297 VCU_VehMod "Vehicle mode";
CM_ SG_ 1297 VCU_VehCrtChrgEndSOC "Vehicle current charging cutoff SOC value";
CM_ SG_ 1297 VCU_CalSwVers "VCU calibration software version number";
CM_ SG_ 1297 VCU_RemPwrBattPreheatgEndFlg "The remote traction battery preheating end flag";
CM_ SG_ 1297 VCU_VehOperMod "Vehicle operation condition";
CM_ SG_ 1297 VCU_VehRemRefrshModReq "Vehicle remote flashing mode requirements";
CM_ SG_ 1297 VCU_RemDTCPwrOnReq "Remote diagnosis of power-on demand";
CM_ SG_ 1329 ICC_TotMilgVld_ODO "Effective bit of ODO total mileage";
CM_ SG_ 1329 ICC_TotMilg_ODO "ODO total mileage";
CM_ SG_ 1329 ICC_DispVehSpd "Display speed";
CM_ SG_ 1329 ICC_DispVehSpdUnit "Display vehicle speed unit";
CM_ SG_ 1329 ICC_ADASSigFlt "Instrument ADAS signal fault";
CM_ SG_ 1329 ICC_DispFlt "Instrument display failure";
CM_ SG_ 1329 ICC_WorkshopMode "Setting by customer over display before he wants to tow the vehicle (=Rescue (Workshop Mode)";
CM_ SG_ 1476 TBOX_OTA_ownCondchk "TBOX request ECUs to check own conditions for OTA";
CM_ SG_ 1476 TBOX_TerminalRemWakeupSig "Terminal remote wake-up signal";
CM_ SG_ 1476 TBOX_RemSCModReq "Remote charging mode request

";
CM_ SG_ 1476 TBOX_RemPwrBattOpenHeatgReq "Remote traction battery ON heating request";
CM_ SG_ 1476 TBOX_RemPwrBattResvHeatgReq "Remote traction battery heating reservation request";
CM_ SG_ 1476 TBOX_RemInsdInfoDispEna "Remote interior information display enabling";
CM_ SG_ 1476 TBOX_RemECCDefrstModReq "A/C defrosting mode request";
CM_ SG_ 1476 TBOX_RemECCResvDefrstReq "Remote A/C Reservation Defrosting Request";
CM_ SG_ 1476 TBOX_RemECCSetT "Remote A/C set temperature value";
CM_ SG_ 1476 TBOX_RemResvECCSetT "Reserved A/C set temperature value remotely";
CM_ SG_ 1476 TBOX_RemSOCMax "User setting of remote power battery heating cutoff SOC value";
CM_ SG_ 1476 TBOX_4GSigIND "4 G signal strength indication";
CM_ SG_ 1476 TBOX_TSPNotConn "Cannot connect to TSP";
CM_ SG_ 1476 TBOX_EHUNotCONN "Fault of USB communication with audio and entertainment system";
CM_ SG_ 1476 TBOX_WIFIError "WIFI fault";
CM_ SG_ 1476 TBOX_InnerBattError "Built-in battery fault";
CM_ SG_ 1476 TBOX_VoltLow "Low voltage fault";
CM_ SG_ 1476 TBOX_VoltHigh "Overvoltage fault";
CM_ SG_ 1476 TBOX_4GLoss "4 G signal loss fault";
CM_ SG_ 1476 TBOX_RemSWH_Req "Remote Function Steering Wheel Heating Request";
CM_ SG_ 1476 TBOX_OTAInhbReq "TBOX request inhibit function to VCU";
CM_ SG_ 1476 TBOX_5C4_SSecOC_Fresh_Byte0 "Short SecOC Fresh signal byte 0 on CAN";
CM_ SG_ 1476 TBOX_5C4_SSecOC_MAC_Byte0 "Short SecOC MAC signal byte 0 on CAN";
CM_ SG_ 1476 TBOX_5C4_SSecOC_MAC_Byte1 "Short SecOC MAC signal byte 1 on CAN";
CM_ SG_ 1476 TBOX_5C4_SSecOC_MAC_Byte2 "Short SecOC MAC signal byte 2 on CAN";
CM_ SG_ 1583 TBOX_CrtTi_Day "Current time_day";
CM_ SG_ 1583 TBOX_CrtTi_Hr "Current time_hour";
CM_ SG_ 1583 TBOX_CrtTi_Mins "Current time_min";
CM_ SG_ 1583 TBOX_CrtTi_Yr "Current time_year";
CM_ SG_ 1583 TBOX_CrtTi_Mth "Current time_month";
CM_ SG_ 1583 TBOX_CrtTi_Sec "Current time_seconds";
CM_ SG_ 1661 FCM_SwVersS "FCM software version number second two";
CM_ SG_ 1661 FCM_PartVers "FCM part number";
CM_ SG_ 1661 FCM_HwVers "FCM hardware version number last two digits";
CM_ SG_ 1661 FCM_SwVersM "Last two digits of FCM main software version number";
CM_ SG_ 1760 BCM_VIN_Byte1 "This Signal contains the seventh-last position of the vehicle identification number (positions are coded in ASCII).";
CM_ SG_ 1760 BCM_VIN_Byte2 "This Signal contains the sixth-last position of the vehicle identification number (positions are coded in ASCII).";
CM_ SG_ 1760 BCM_VIN_Byte3 "This Signal contains the fifth-last position of the vehicle identification number (positions are coded in ASCII).";
CM_ SG_ 1760 BCM_VIN_Byte4 "This Signal contains the fourth-last position of the vehicle identification number (positions are coded in ASCII).";
CM_ SG_ 1760 BCM_VIN_Byte5 "This Signal contains the third-last position of the vehicle identification number (positions are coded in ASCII).";
CM_ SG_ 1760 BCM_VIN_Byte6 "This Signal contains the second-last position of the vehicle identification number (positions are coded in ASCII).";
CM_ SG_ 1760 BCM_VIN_Byte7 "This Signal contains the last position of the vehicle identification number (positions are coded in ASCII).";
CM_ SG_ 1765 VCU_VINCod1 "VIN number 1 (indicating 1 to 8 ASC values in the number)VCUVINCode_1(Bit1~8ofASCII)";
CM_ SG_ 1766 VCU_VINCod2 "VIN number 2 (indicating 9 to 16 ASC values in the number)VCUVINCode_2(Bit9~16ofASCII)";
CM_ SG_ 1767 VCU_VINCod3 "VIN number 3 (indicating 17 to 24 ASC values in number)VCUVINCode_3(Bit17~24ofASCII)";
CM_ SG_ 1920 FCM_Byte2_Req "Diagnostic signal";
CM_ SG_ 1920 FCM_Byte3_Req "Diagnostic signal";
CM_ SG_ 1920 FCM_Byte4_Req "Diagnostic signal";
CM_ SG_ 1920 FCM_Byte5_Req "Diagnostic signal";
CM_ SG_ 1920 FCM_Byte6_Req "Diagnostic signal";
CM_ SG_ 1920 FCM_Byte7_Req "Diagnostic signal";
CM_ SG_ 1920 FCM_Byte8_Req "Diagnostic signal";
CM_ SG_ 1920 FCM_TPCI_Req "Diagnostic signal";
CM_ BO_ 1928 "The DLC of the diagnosis message in the matrix is only used to generate the DBC file, and the DLC length used in the actual development of the ECU shall meet the technical requirements of the UDS.";
CM_ SG_ 1928 FCM_Byte2_Resp "Diagnostic signal";
CM_ SG_ 1928 FCM_Byte3_Resp "Diagnostic signal";
CM_ SG_ 1928 FCM_Byte4_Resp "Diagnostic signal";
CM_ SG_ 1928 FCM_Byte5_Resp "Diagnostic signal";
CM_ SG_ 1928 FCM_Byte6_Resp "Diagnostic signal";
CM_ SG_ 1928 FCM_Byte7_Resp "Diagnostic signal";
CM_ SG_ 1928 FCM_Byte8_Resp "Diagnostic signal";
CM_ SG_ 1928 FCM_TPCI_Resp "Diagnostic signal";
CM_ SG_ 2015 Tester_Byte2_Req "Diagnostic signal";
CM_ SG_ 2015 Tester_Byte3_Req "Diagnostic signal";
CM_ SG_ 2015 Tester_Byte4_Req "Diagnostic signal";
CM_ SG_ 2015 Tester_Byte5_Req "Diagnostic signal";
CM_ SG_ 2015 Tester_Byte6_Req "Diagnostic signal";
CM_ SG_ 2015 Tester_Byte7_Req "Diagnostic signal";
CM_ SG_ 2015 Tester_Byte8_Req "Diagnostic signal";
CM_ SG_ 2015 Tester_TPCI_Req "Diagnostic signal";
BA_DEF_ BO_  "FBlock" STRING ;
BA_DEF_ BO_  "FunctionClass" ENUM  "Property","Method";
BA_DEF_ BO_  "NmAsrMessage" ENUM  "No","Yes";
BA_DEF_ SG_  "GenSigCycleTime" INT 0 0;
BA_DEF_ BO_  "NmMessage" ENUM  "No","Yes";
BA_DEF_ BO_  "SC_Message" ENUM  "No","Yes","Yes, split message";
BA_DEF_ BO_  "DiagState" ENUM  "No","Yes";
BA_DEF_ BO_  "SC_LinkPos" INT 0 65535;
BA_DEF_ BO_  "DiagRequest" ENUM  "No","Yes";
BA_DEF_ BO_  "DiagFdOnly" ENUM  "No","Yes";
BA_DEF_ BO_  "DiagResponse" ENUM  "No","Yes";
BA_DEF_ BO_  "SCP_AuthInfoTxLength" INT 0 512;
BA_DEF_ BO_  "GenMsgSendType" ENUM  "Cyclic","NotUsed","NotUsed","NotUsed","NotUsed","NotUsed","NotUsed","IfActive","NoMsgSendType";
BA_DEF_ BO_  "SCP_DataId" INT 0 65535;
BA_DEF_ BO_  "GenMsgCycleTime" INT 0 0;
BA_DEF_ BO_  "SCP_FreshnessValueId" INT 0 65535;
BA_DEF_ BO_  "SCP_FreshnessValueLength" INT 0 512;
BA_DEF_ SG_  "GenSigStartValue" INT 0 0;
BA_DEF_ BO_  "SCL_CryptographicMessageID" INT 0 65535;
BA_DEF_ SG_  "GenSigInactiveValue" INT 0 0;
BA_DEF_ SG_  "GenSigSendType" ENUM  "Cyclic","OnWrite","OnWriteWithRepetition","OnChange","OnChangeWithRepetition","IfActive","IfActiveWithRepetition","NoSigSendType";
BA_DEF_ BO_  "SCP_FreshnessValueTxLength" INT 0 512;
BA_DEF_ BO_  "GenMsgCycleTimeFast" INT 0 0;
BA_DEF_ BO_  "GenMsgNrOfRepetition" INT 0 0;
BA_DEF_ BO_  "DiagConnection" INT 0 65535;
BA_DEF_ BO_  "GenMsgDelayTime" INT 0 0;
BA_DEF_ BO_  "CANFD_BRS" ENUM  "0","1";
BA_DEF_ BO_  "VFrameFormat" ENUM  "StandardCAN","ExtendedCAN","reserved","reserved","reserved","reserved","reserved","reserved","reserved","reserved","reserved","reserved","reserved","reserved","StandardCAN_FD","ExtendedCAN_FD";
BA_DEF_ BO_  "GenMsgILSupport" ENUM  "No","Yes";
BA_DEF_ BO_  "GenMsgStartDelayTime" INT 0 65535;
BA_DEF_ BO_  "E2EP01DataLength" INT 0 65535;
BA_DEF_ BO_  "E2EP01DataId" INT 0 65535;
BA_DEF_ SG_  "sigSecLevel" STRING ;
BA_DEF_ SG_  "sigConfig" STRING ;
BA_DEF_ SG_  "sigExplanation" STRING ;
BA_DEF_DEF_  "FBlock" "GeneralBlock";
BA_DEF_DEF_  "FunctionClass" "Property";
BA_DEF_DEF_  "NmAsrMessage" "No";
BA_DEF_DEF_  "GenSigCycleTime" 0;
BA_DEF_DEF_  "NmMessage" "No";
BA_DEF_DEF_  "SC_Message" "No";
BA_DEF_DEF_  "DiagState" "No";
BA_DEF_DEF_  "SC_LinkPos" 0;
BA_DEF_DEF_  "DiagRequest" "No";
BA_DEF_DEF_  "DiagFdOnly" "No";
BA_DEF_DEF_  "DiagResponse" "No";
BA_DEF_DEF_  "SCP_AuthInfoTxLength" 0;
BA_DEF_DEF_  "GenMsgSendType" "Cyclic";
BA_DEF_DEF_  "SCP_DataId" 0;
BA_DEF_DEF_  "GenMsgCycleTime" 0;
BA_DEF_DEF_  "SCP_FreshnessValueId" 0;
BA_DEF_DEF_  "SCP_FreshnessValueLength" 0;
BA_DEF_DEF_  "GenSigStartValue" 0;
BA_DEF_DEF_  "SCL_CryptographicMessageID" 0;
BA_DEF_DEF_  "GenSigInactiveValue" 0;
BA_DEF_DEF_  "GenSigSendType" "Cyclic";
BA_DEF_DEF_  "SCP_FreshnessValueTxLength" 0;
BA_DEF_DEF_  "GenMsgCycleTimeFast" 0;
BA_DEF_DEF_  "GenMsgNrOfRepetition" 0;
BA_DEF_DEF_  "DiagConnection" 0;
BA_DEF_DEF_  "GenMsgDelayTime" 0;
BA_DEF_DEF_  "CANFD_BRS" "1";
BA_DEF_DEF_  "VFrameFormat" "StandardCAN";
BA_DEF_DEF_  "GenMsgILSupport" "Yes";
BA_DEF_DEF_  "GenMsgStartDelayTime" 0;
BA_DEF_DEF_  "E2EP01DataLength" 0;
BA_DEF_DEF_  "E2EP01DataId" 0;
BA_DEF_DEF_  "sigSecLevel" "";
BA_DEF_DEF_  "sigConfig" "";
BA_DEF_DEF_  "sigExplanation" "";
BA_ "GenMsgCycleTimeFast" BO_ 1065 64;
BA_ "NmMessage" BO_ 1065 1;
BA_ "NmAsrMessage" BO_ 1065 1;
BA_ "GenMsgCycleTime" BO_ 1065 64;
BA_ "VFrameFormat" BO_ 1065 14;
BA_ "GenMsgCycleTimeFast" BO_ 1069 64;
BA_ "NmMessage" BO_ 1069 1;
BA_ "NmAsrMessage" BO_ 1069 1;
BA_ "GenMsgCycleTime" BO_ 1069 64;
BA_ "VFrameFormat" BO_ 1069 14;
BA_ "GenMsgCycleTimeFast" BO_ 1070 64;
BA_ "NmMessage" BO_ 1070 1;
BA_ "NmAsrMessage" BO_ 1070 1;
BA_ "GenMsgCycleTime" BO_ 1070 64;
BA_ "VFrameFormat" BO_ 1070 14;
BA_ "GenMsgCycleTimeFast" BO_ 1086 64;
BA_ "NmMessage" BO_ 1086 1;
BA_ "NmAsrMessage" BO_ 1086 1;
BA_ "GenMsgCycleTime" BO_ 1086 64;
BA_ "VFrameFormat" BO_ 1086 14;
BA_ "GenMsgCycleTime" BO_ 1159 100;
BA_ "VFrameFormat" BO_ 1159 14;
BA_ "SC_Message" BO_ 1268 1;
BA_ "SC_LinkPos" BO_ 1268 64;
BA_ "SCP_FreshnessValueTxLength" BO_ 1268 8;
BA_ "SCP_FreshnessValueLength" BO_ 1268 64;
BA_ "SCP_FreshnessValueId" BO_ 1268 1268;
BA_ "SCP_DataId" BO_ 1268 1268;
BA_ "SCP_AuthInfoTxLength" BO_ 1268 24;
BA_ "SCL_CryptographicMessageID" BO_ 1268 1268;
BA_ "GenMsgStartDelayTime" BO_ 1268 70;
BA_ "GenMsgNrOfRepetition" BO_ 1268 5;
BA_ "GenMsgDelayTime" BO_ 1268 10;
BA_ "GenMsgCycleTimeFast" BO_ 1268 10;
BA_ "GenMsgCycleTime" BO_ 1268 100;
BA_ "E2EP01DataLength" BO_ 1268 64;
BA_ "E2EP01DataId" BO_ 1268 194;
BA_ "VFrameFormat" BO_ 1268 14;
BA_ "GenMsgCycleTime" BO_ 1287 100;
BA_ "VFrameFormat" BO_ 1287 14;
BA_ "GenMsgCycleTime" BO_ 1297 100;
BA_ "VFrameFormat" BO_ 1297 14;
BA_ "GenMsgCycleTime" BO_ 1329 100;
BA_ "VFrameFormat" BO_ 1329 14;
BA_ "SC_Message" BO_ 1476 1;
BA_ "SC_LinkPos" BO_ 1476 64;
BA_ "SCP_FreshnessValueTxLength" BO_ 1476 8;
BA_ "SCP_FreshnessValueLength" BO_ 1476 64;
BA_ "SCP_FreshnessValueId" BO_ 1476 1476;
BA_ "SCP_DataId" BO_ 1476 1476;
BA_ "SCP_AuthInfoTxLength" BO_ 1476 24;
BA_ "SCL_CryptographicMessageID" BO_ 1476 1476;
BA_ "GenMsgStartDelayTime" BO_ 1476 90;
BA_ "GenMsgDelayTime" BO_ 1476 90;
BA_ "GenMsgCycleTime" BO_ 1476 100;
BA_ "VFrameFormat" BO_ 1476 14;
BA_ "GenMsgStartDelayTime" BO_ 1583 195;
BA_ "GenMsgCycleTime" BO_ 1583 1000;
BA_ "VFrameFormat" BO_ 1583 14;
BA_ "GenMsgCycleTime" BO_ 1661 1000;
BA_ "VFrameFormat" BO_ 1661 14;
BA_ "GenMsgCycleTime" BO_ 1760 5000;
BA_ "VFrameFormat" BO_ 1760 14;
BA_ "GenMsgCycleTime" BO_ 1765 5000;
BA_ "VFrameFormat" BO_ 1765 14;
BA_ "GenMsgCycleTime" BO_ 1766 5000;
BA_ "VFrameFormat" BO_ 1766 14;
BA_ "GenMsgCycleTime" BO_ 1767 5000;
BA_ "VFrameFormat" BO_ 1767 14;
BA_ "GenMsgSendType" BO_ 1920 8;
BA_ "GenMsgILSupport" BO_ 1920 0;
BA_ "DiagRequest" BO_ 1920 1;
BA_ "DiagFdOnly" BO_ 1920 1;
BA_ "DiagConnection" BO_ 1920 8494;
BA_ "VFrameFormat" BO_ 1920 14;
BA_ "GenMsgSendType" BO_ 1928 8;
BA_ "GenMsgILSupport" BO_ 1928 0;
BA_ "DiagResponse" BO_ 1928 1;
BA_ "DiagFdOnly" BO_ 1928 1;
BA_ "DiagConnection" BO_ 1928 8494;
BA_ "VFrameFormat" BO_ 1928 14;
BA_ "GenMsgSendType" BO_ 2015 8;
BA_ "GenMsgILSupport" BO_ 2015 0;
BA_ "DiagState" BO_ 2015 1;
BA_ "DiagFdOnly" BO_ 2015 1;
BA_ "DiagConnection" BO_ 2015 8573;
BA_ "VFrameFormat" BO_ 2015 14;
BA_ "sigSecLevel" SG_ 1065 PKC_SrcNodeID "QM";
BA_ "sigExplanation" SG_ 1065 PKC_SrcNodeID "null";
BA_ "sigConfig" SG_ 1065 PKC_SrcNodeID "null";
BA_ "sigSecLevel" SG_ 1065 PKC_CtrlBitVector_Bit0_RMR "QM";
BA_ "sigExplanation" SG_ 1065 PKC_CtrlBitVector_Bit0_RMR "null";
BA_ "sigConfig" SG_ 1065 PKC_CtrlBitVector_Bit0_RMR "null";
BA_ "sigSecLevel" SG_ 1065 PKC_CtrlBitVector_Bit1_Res "QM";
BA_ "sigExplanation" SG_ 1065 PKC_CtrlBitVector_Bit1_Res "null";
BA_ "sigConfig" SG_ 1065 PKC_CtrlBitVector_Bit1_Res "null";
BA_ "sigSecLevel" SG_ 1065 PKC_CtrlBitVector_Bit2_Res "QM";
BA_ "sigExplanation" SG_ 1065 PKC_CtrlBitVector_Bit2_Res "null";
BA_ "sigConfig" SG_ 1065 PKC_CtrlBitVector_Bit2_Res "null";
BA_ "sigSecLevel" SG_ 1065 PKC_CtrlBitVector_Bit3_NMCoord "QM";
BA_ "sigExplanation" SG_ 1065 PKC_CtrlBitVector_Bit3_NMCoord "null";
BA_ "sigConfig" SG_ 1065 PKC_CtrlBitVector_Bit3_NMCoord "null";
BA_ "sigSecLevel" SG_ 1065 PKC_CtrlBitVector_Bit4_ActWake "QM";
BA_ "sigExplanation" SG_ 1065 PKC_CtrlBitVector_Bit4_ActWake "null";
BA_ "sigConfig" SG_ 1065 PKC_CtrlBitVector_Bit4_ActWake "null";
BA_ "sigSecLevel" SG_ 1065 PKC_CtrlBitVector_Bit5_Res "QM";
BA_ "sigExplanation" SG_ 1065 PKC_CtrlBitVector_Bit5_Res "null";
BA_ "sigConfig" SG_ 1065 PKC_CtrlBitVector_Bit5_Res "null";
BA_ "sigSecLevel" SG_ 1065 PKC_CtrlBitVector_Bit6_PNI "QM";
BA_ "sigExplanation" SG_ 1065 PKC_CtrlBitVector_Bit6_PNI "null";
BA_ "sigConfig" SG_ 1065 PKC_CtrlBitVector_Bit6_PNI "null";
BA_ "sigSecLevel" SG_ 1065 PKC_CtrlBitVector_Bit7_Res "QM";
BA_ "sigExplanation" SG_ 1065 PKC_CtrlBitVector_Bit7_Res "null";
BA_ "sigConfig" SG_ 1065 PKC_CtrlBitVector_Bit7_Res "null";
BA_ "sigSecLevel" SG_ 1065 PKC_UsrData0 "QM";
BA_ "sigExplanation" SG_ 1065 PKC_UsrData0 "null";
BA_ "sigConfig" SG_ 1065 PKC_UsrData0 "null";
BA_ "GenSigStartValue" SG_ 1065 PKC_UsrData0 255;
BA_ "sigSecLevel" SG_ 1065 PKC_UsrData1_Bit0_IGN_WAKEUP "QM";
BA_ "sigExplanation" SG_ 1065 PKC_UsrData1_Bit0_IGN_WAKEUP "null";
BA_ "sigConfig" SG_ 1065 PKC_UsrData1_Bit0_IGN_WAKEUP "null";
BA_ "sigSecLevel" SG_ 1065 PKC_UsrData1_Bit1_RESET_WAKEUP "QM";
BA_ "sigExplanation" SG_ 1065 PKC_UsrData1_Bit1_RESET_WAKEUP "null";
BA_ "sigConfig" SG_ 1065 PKC_UsrData1_Bit1_RESET_WAKEUP "null";
BA_ "sigSecLevel" SG_ 1065 PKC_UsrData1_Bit2_NETWORK_WAKEUP "QM";
BA_ "sigExplanation" SG_ 1065 PKC_UsrData1_Bit2_NETWORK_WAKEUP "null";
BA_ "sigConfig" SG_ 1065 PKC_UsrData1_Bit2_NETWORK_WAKEUP "null";
BA_ "sigSecLevel" SG_ 1065 PKC_UsrData1_Bit3_ECUSPEC_WAKEUP "QM";
BA_ "sigExplanation" SG_ 1065 PKC_UsrData1_Bit3_ECUSPEC_WAKEUP "null";
BA_ "sigConfig" SG_ 1065 PKC_UsrData1_Bit3_ECUSPEC_WAKEUP "null";
BA_ "sigSecLevel" SG_ 1065 PKC_UsrData1_Bit4_NETWORK_AWAKE "QM";
BA_ "sigExplanation" SG_ 1065 PKC_UsrData1_Bit4_NETWORK_AWAKE "null";
BA_ "sigConfig" SG_ 1065 PKC_UsrData1_Bit4_NETWORK_AWAKE "null";
BA_ "sigSecLevel" SG_ 1065 PKC_UsrData1_Bit5_IGNITION_AWAKE "QM";
BA_ "sigExplanation" SG_ 1065 PKC_UsrData1_Bit5_IGNITION_AWAKE "null";
BA_ "sigConfig" SG_ 1065 PKC_UsrData1_Bit5_IGNITION_AWAKE "null";
BA_ "sigSecLevel" SG_ 1065 PKC_UsrData1_Bit6_DIAGN_AWAKE "QM";
BA_ "sigExplanation" SG_ 1065 PKC_UsrData1_Bit6_DIAGN_AWAKE "null";
BA_ "sigConfig" SG_ 1065 PKC_UsrData1_Bit6_DIAGN_AWAKE "null";
BA_ "sigSecLevel" SG_ 1065 PKC_UsrData1_Bit7_ECUSPEC_AWAKE "QM";
BA_ "sigExplanation" SG_ 1065 PKC_UsrData1_Bit7_ECUSPEC_AWAKE "null";
BA_ "sigConfig" SG_ 1065 PKC_UsrData1_Bit7_ECUSPEC_AWAKE "null";
BA_ "sigSecLevel" SG_ 1065 PKC_UsrData2 "QM";
BA_ "sigExplanation" SG_ 1065 PKC_UsrData2 "null";
BA_ "sigConfig" SG_ 1065 PKC_UsrData2 "null";
BA_ "GenSigStartValue" SG_ 1065 PKC_UsrData2 255;
BA_ "sigSecLevel" SG_ 1065 PKC_UsrData3 "QM";
BA_ "sigExplanation" SG_ 1065 PKC_UsrData3 "null";
BA_ "sigConfig" SG_ 1065 PKC_UsrData3 "null";
BA_ "GenSigStartValue" SG_ 1065 PKC_UsrData3 255;
BA_ "sigSecLevel" SG_ 1065 PKC_UsrData4_PN_Info1 "QM";
BA_ "sigExplanation" SG_ 1065 PKC_UsrData4_PN_Info1 "null";
BA_ "sigConfig" SG_ 1065 PKC_UsrData4_PN_Info1 "null";
BA_ "GenSigStartValue" SG_ 1065 PKC_UsrData4_PN_Info1 255;
BA_ "sigSecLevel" SG_ 1065 PKC_UsrData5_PN_Info2 "QM";
BA_ "sigExplanation" SG_ 1065 PKC_UsrData5_PN_Info2 "null";
BA_ "sigConfig" SG_ 1065 PKC_UsrData5_PN_Info2 "null";
BA_ "GenSigStartValue" SG_ 1065 PKC_UsrData5_PN_Info2 255;
BA_ "sigSecLevel" SG_ 1069 ADAS_SrcNodeID "QM";
BA_ "sigExplanation" SG_ 1069 ADAS_SrcNodeID "null";
BA_ "sigConfig" SG_ 1069 ADAS_SrcNodeID "null";
BA_ "sigSecLevel" SG_ 1069 ADAS_CtrlBitVector_Bit0_RMR "QM";
BA_ "sigExplanation" SG_ 1069 ADAS_CtrlBitVector_Bit0_RMR "null";
BA_ "sigConfig" SG_ 1069 ADAS_CtrlBitVector_Bit0_RMR "null";
BA_ "sigSecLevel" SG_ 1069 ADAS_CtrlBitVector_Bit1_Res "QM";
BA_ "sigExplanation" SG_ 1069 ADAS_CtrlBitVector_Bit1_Res "null";
BA_ "sigConfig" SG_ 1069 ADAS_CtrlBitVector_Bit1_Res "null";
BA_ "sigSecLevel" SG_ 1069 ADAS_CtrlBitVector_Bit2_Res "QM";
BA_ "sigExplanation" SG_ 1069 ADAS_CtrlBitVector_Bit2_Res "null";
BA_ "sigConfig" SG_ 1069 ADAS_CtrlBitVector_Bit2_Res "null";
BA_ "sigSecLevel" SG_ 1069 ADAS_CtrlBitVector_Bit3_NMCoord "QM";
BA_ "sigExplanation" SG_ 1069 ADAS_CtrlBitVector_Bit3_NMCoord "null";
BA_ "sigConfig" SG_ 1069 ADAS_CtrlBitVector_Bit3_NMCoord "null";
BA_ "sigSecLevel" SG_ 1069 ADAS_CtrlBitVector_Bit4_ActWake "QM";
BA_ "sigExplanation" SG_ 1069 ADAS_CtrlBitVector_Bit4_ActWake "null";
BA_ "sigConfig" SG_ 1069 ADAS_CtrlBitVector_Bit4_ActWake "null";
BA_ "sigSecLevel" SG_ 1069 ADAS_CtrlBitVector_Bit5_Res "QM";
BA_ "sigExplanation" SG_ 1069 ADAS_CtrlBitVector_Bit5_Res "null";
BA_ "sigConfig" SG_ 1069 ADAS_CtrlBitVector_Bit5_Res "null";
BA_ "sigSecLevel" SG_ 1069 ADAS_CtrlBitVector_Bit6_PNI "QM";
BA_ "sigExplanation" SG_ 1069 ADAS_CtrlBitVector_Bit6_PNI "null";
BA_ "sigConfig" SG_ 1069 ADAS_CtrlBitVector_Bit6_PNI "null";
BA_ "sigSecLevel" SG_ 1069 ADAS_CtrlBitVector_Bit7_Res "QM";
BA_ "sigExplanation" SG_ 1069 ADAS_CtrlBitVector_Bit7_Res "null";
BA_ "sigConfig" SG_ 1069 ADAS_CtrlBitVector_Bit7_Res "null";
BA_ "sigSecLevel" SG_ 1069 ADAS_UsrData0 "QM";
BA_ "sigExplanation" SG_ 1069 ADAS_UsrData0 "null";
BA_ "sigConfig" SG_ 1069 ADAS_UsrData0 "null";
BA_ "GenSigStartValue" SG_ 1069 ADAS_UsrData0 255;
BA_ "sigSecLevel" SG_ 1069 ADAS_UsrData1_Bit0_IGN_WAKEUP "QM";
BA_ "sigExplanation" SG_ 1069 ADAS_UsrData1_Bit0_IGN_WAKEUP "null";
BA_ "sigConfig" SG_ 1069 ADAS_UsrData1_Bit0_IGN_WAKEUP "null";
BA_ "sigSecLevel" SG_ 1069 ADAS_UsrData1_Bit1_RESET_WAKEUP "QM";
BA_ "sigExplanation" SG_ 1069 ADAS_UsrData1_Bit1_RESET_WAKEUP "null";
BA_ "sigConfig" SG_ 1069 ADAS_UsrData1_Bit1_RESET_WAKEUP "null";
BA_ "sigSecLevel" SG_ 1069 ADAS_UsrData1_Bit2_NET_WKUP "QM";
BA_ "sigExplanation" SG_ 1069 ADAS_UsrData1_Bit2_NET_WKUP "null";
BA_ "sigConfig" SG_ 1069 ADAS_UsrData1_Bit2_NET_WKUP "null";
BA_ "sigSecLevel" SG_ 1069 ADAS_UsrData1_Bit3_ECUSPEC_WKUP "QM";
BA_ "sigExplanation" SG_ 1069 ADAS_UsrData1_Bit3_ECUSPEC_WKUP "null";
BA_ "sigConfig" SG_ 1069 ADAS_UsrData1_Bit3_ECUSPEC_WKUP "null";
BA_ "sigSecLevel" SG_ 1069 ADAS_UsrData1_Bit4_NETWORK_AWAKE "QM";
BA_ "sigExplanation" SG_ 1069 ADAS_UsrData1_Bit4_NETWORK_AWAKE "null";
BA_ "sigConfig" SG_ 1069 ADAS_UsrData1_Bit4_NETWORK_AWAKE "null";
BA_ "sigSecLevel" SG_ 1069 ADAS_UsrData1_Bit5_IGN_AWAKE "QM";
BA_ "sigExplanation" SG_ 1069 ADAS_UsrData1_Bit5_IGN_AWAKE "null";
BA_ "sigConfig" SG_ 1069 ADAS_UsrData1_Bit5_IGN_AWAKE "null";
BA_ "sigSecLevel" SG_ 1069 ADAS_UsrData1_Bit6_DIAGN_AWAKE "QM";
BA_ "sigExplanation" SG_ 1069 ADAS_UsrData1_Bit6_DIAGN_AWAKE "null";
BA_ "sigConfig" SG_ 1069 ADAS_UsrData1_Bit6_DIAGN_AWAKE "null";
BA_ "sigSecLevel" SG_ 1069 ADAS_UsrData1_Bit7_ECUSPEC_AWAKE "QM";
BA_ "sigExplanation" SG_ 1069 ADAS_UsrData1_Bit7_ECUSPEC_AWAKE "null";
BA_ "sigConfig" SG_ 1069 ADAS_UsrData1_Bit7_ECUSPEC_AWAKE "null";
BA_ "sigSecLevel" SG_ 1069 ADAS_UsrData2 "QM";
BA_ "sigExplanation" SG_ 1069 ADAS_UsrData2 "null";
BA_ "sigConfig" SG_ 1069 ADAS_UsrData2 "null";
BA_ "GenSigStartValue" SG_ 1069 ADAS_UsrData2 255;
BA_ "sigSecLevel" SG_ 1069 ADAS_UsrData3 "QM";
BA_ "sigExplanation" SG_ 1069 ADAS_UsrData3 "null";
BA_ "sigConfig" SG_ 1069 ADAS_UsrData3 "null";
BA_ "GenSigStartValue" SG_ 1069 ADAS_UsrData3 255;
BA_ "sigSecLevel" SG_ 1069 ADAS_UsrData4_PN_Info1 "QM";
BA_ "sigExplanation" SG_ 1069 ADAS_UsrData4_PN_Info1 "null";
BA_ "sigConfig" SG_ 1069 ADAS_UsrData4_PN_Info1 "null";
BA_ "GenSigStartValue" SG_ 1069 ADAS_UsrData4_PN_Info1 255;
BA_ "sigSecLevel" SG_ 1069 ADAS_UsrData5_PN_Info2 "QM";
BA_ "sigExplanation" SG_ 1069 ADAS_UsrData5_PN_Info2 "null";
BA_ "sigConfig" SG_ 1069 ADAS_UsrData5_PN_Info2 "null";
BA_ "GenSigStartValue" SG_ 1069 ADAS_UsrData5_PN_Info2 255;
BA_ "sigSecLevel" SG_ 1070 FCM_SrcNodeID "QM";
BA_ "sigExplanation" SG_ 1070 FCM_SrcNodeID "null";
BA_ "sigConfig" SG_ 1070 FCM_SrcNodeID "null";
BA_ "sigSecLevel" SG_ 1070 FCM_CtrlBitVector_Bit0_RMR "QM";
BA_ "sigExplanation" SG_ 1070 FCM_CtrlBitVector_Bit0_RMR "null";
BA_ "sigConfig" SG_ 1070 FCM_CtrlBitVector_Bit0_RMR "null";
BA_ "sigSecLevel" SG_ 1070 FCM_CtrlBitVector_Bit1_Res "QM";
BA_ "sigExplanation" SG_ 1070 FCM_CtrlBitVector_Bit1_Res "null";
BA_ "sigConfig" SG_ 1070 FCM_CtrlBitVector_Bit1_Res "null";
BA_ "sigSecLevel" SG_ 1070 FCM_CtrlBitVector_Bit2_Res "QM";
BA_ "sigExplanation" SG_ 1070 FCM_CtrlBitVector_Bit2_Res "null";
BA_ "sigConfig" SG_ 1070 FCM_CtrlBitVector_Bit2_Res "null";
BA_ "sigSecLevel" SG_ 1070 FCM_CtrlBitVector_Bit3_NMCoord "QM";
BA_ "sigExplanation" SG_ 1070 FCM_CtrlBitVector_Bit3_NMCoord "null";
BA_ "sigConfig" SG_ 1070 FCM_CtrlBitVector_Bit3_NMCoord "null";
BA_ "sigSecLevel" SG_ 1070 FCM_CtrlBitVector_Bit4_ActWake "QM";
BA_ "sigExplanation" SG_ 1070 FCM_CtrlBitVector_Bit4_ActWake "null";
BA_ "sigConfig" SG_ 1070 FCM_CtrlBitVector_Bit4_ActWake "null";
BA_ "sigSecLevel" SG_ 1070 FCM_CtrlBitVector_Bit5_Res "QM";
BA_ "sigExplanation" SG_ 1070 FCM_CtrlBitVector_Bit5_Res "null";
BA_ "sigConfig" SG_ 1070 FCM_CtrlBitVector_Bit5_Res "null";
BA_ "sigSecLevel" SG_ 1070 FCM_CtrlBitVector_Bit6_PNI "QM";
BA_ "sigExplanation" SG_ 1070 FCM_CtrlBitVector_Bit6_PNI "null";
BA_ "sigConfig" SG_ 1070 FCM_CtrlBitVector_Bit6_PNI "null";
BA_ "sigSecLevel" SG_ 1070 FCM_CtrlBitVector_Bit7_Res "QM";
BA_ "sigExplanation" SG_ 1070 FCM_CtrlBitVector_Bit7_Res "null";
BA_ "sigConfig" SG_ 1070 FCM_CtrlBitVector_Bit7_Res "null";
BA_ "sigSecLevel" SG_ 1070 FCM_UsrData0 "QM";
BA_ "sigExplanation" SG_ 1070 FCM_UsrData0 "null";
BA_ "sigConfig" SG_ 1070 FCM_UsrData0 "null";
BA_ "GenSigStartValue" SG_ 1070 FCM_UsrData0 255;
BA_ "sigSecLevel" SG_ 1070 FCM_UsrData1_Bit0_IGN_WAKEUP "QM";
BA_ "sigExplanation" SG_ 1070 FCM_UsrData1_Bit0_IGN_WAKEUP "null";
BA_ "sigConfig" SG_ 1070 FCM_UsrData1_Bit0_IGN_WAKEUP "null";
BA_ "sigSecLevel" SG_ 1070 FCM_UsrData1_Bit1_RESET_WAKEUP "QM";
BA_ "sigExplanation" SG_ 1070 FCM_UsrData1_Bit1_RESET_WAKEUP "null";
BA_ "sigConfig" SG_ 1070 FCM_UsrData1_Bit1_RESET_WAKEUP "null";
BA_ "sigSecLevel" SG_ 1070 FCM_UsrData1_Bit2_NETWORK_WAKEUP "QM";
BA_ "sigExplanation" SG_ 1070 FCM_UsrData1_Bit2_NETWORK_WAKEUP "null";
BA_ "sigConfig" SG_ 1070 FCM_UsrData1_Bit2_NETWORK_WAKEUP "null";
BA_ "sigSecLevel" SG_ 1070 FCM_UsrData1_Bit3_ECUSPEC_WAKEUP "QM";
BA_ "sigExplanation" SG_ 1070 FCM_UsrData1_Bit3_ECUSPEC_WAKEUP "null";
BA_ "sigConfig" SG_ 1070 FCM_UsrData1_Bit3_ECUSPEC_WAKEUP "null";
BA_ "sigSecLevel" SG_ 1070 FCM_UsrData1_Bit4_NETWORK_AWAKE "QM";
BA_ "sigExplanation" SG_ 1070 FCM_UsrData1_Bit4_NETWORK_AWAKE "null";
BA_ "sigConfig" SG_ 1070 FCM_UsrData1_Bit4_NETWORK_AWAKE "null";
BA_ "sigSecLevel" SG_ 1070 FCM_UsrData1_Bit5_IGNITION_AWAKE "QM";
BA_ "sigExplanation" SG_ 1070 FCM_UsrData1_Bit5_IGNITION_AWAKE "null";
BA_ "sigConfig" SG_ 1070 FCM_UsrData1_Bit5_IGNITION_AWAKE "null";
BA_ "sigSecLevel" SG_ 1070 FCM_UsrData1_Bit6_DIAGN_AWAKE "QM";
BA_ "sigExplanation" SG_ 1070 FCM_UsrData1_Bit6_DIAGN_AWAKE "null";
BA_ "sigConfig" SG_ 1070 FCM_UsrData1_Bit6_DIAGN_AWAKE "null";
BA_ "sigSecLevel" SG_ 1070 FCM_UsrData1_Bit7_ECUSPEC_AWAKE "QM";
BA_ "sigExplanation" SG_ 1070 FCM_UsrData1_Bit7_ECUSPEC_AWAKE "null";
BA_ "sigConfig" SG_ 1070 FCM_UsrData1_Bit7_ECUSPEC_AWAKE "null";
BA_ "sigSecLevel" SG_ 1070 FCM_UsrData2 "QM";
BA_ "sigExplanation" SG_ 1070 FCM_UsrData2 "null";
BA_ "sigConfig" SG_ 1070 FCM_UsrData2 "null";
BA_ "GenSigStartValue" SG_ 1070 FCM_UsrData2 255;
BA_ "sigSecLevel" SG_ 1070 FCM_UsrData3 "QM";
BA_ "sigExplanation" SG_ 1070 FCM_UsrData3 "null";
BA_ "sigConfig" SG_ 1070 FCM_UsrData3 "null";
BA_ "GenSigStartValue" SG_ 1070 FCM_UsrData3 255;
BA_ "sigSecLevel" SG_ 1070 FCM_UsrData4_PN_Info1 "QM";
BA_ "sigExplanation" SG_ 1070 FCM_UsrData4_PN_Info1 "null";
BA_ "sigConfig" SG_ 1070 FCM_UsrData4_PN_Info1 "null";
BA_ "GenSigStartValue" SG_ 1070 FCM_UsrData4_PN_Info1 255;
BA_ "sigSecLevel" SG_ 1070 FCM_UsrData5_PN_Info2 "QM";
BA_ "sigExplanation" SG_ 1070 FCM_UsrData5_PN_Info2 "null";
BA_ "sigConfig" SG_ 1070 FCM_UsrData5_PN_Info2 "null";
BA_ "GenSigStartValue" SG_ 1070 FCM_UsrData5_PN_Info2 255;
BA_ "sigSecLevel" SG_ 1086 GW_SrcNodeID "null";
BA_ "sigExplanation" SG_ 1086 GW_SrcNodeID "null";
BA_ "sigConfig" SG_ 1086 GW_SrcNodeID "null";
BA_ "GenSigSendType" SG_ 1086 GW_SrcNodeID 1;
BA_ "sigSecLevel" SG_ 1086 GW_CtrlBitVector_Bit0_RMR "null";
BA_ "sigExplanation" SG_ 1086 GW_CtrlBitVector_Bit0_RMR "null";
BA_ "sigConfig" SG_ 1086 GW_CtrlBitVector_Bit0_RMR "null";
BA_ "GenSigSendType" SG_ 1086 GW_CtrlBitVector_Bit0_RMR 1;
BA_ "sigSecLevel" SG_ 1086 GW_CtrlBitVector_Bit1_Res "null";
BA_ "sigExplanation" SG_ 1086 GW_CtrlBitVector_Bit1_Res "null";
BA_ "sigConfig" SG_ 1086 GW_CtrlBitVector_Bit1_Res "null";
BA_ "GenSigSendType" SG_ 1086 GW_CtrlBitVector_Bit1_Res 1;
BA_ "sigSecLevel" SG_ 1086 GW_CtrlBitVector_Bit2_Res "null";
BA_ "sigExplanation" SG_ 1086 GW_CtrlBitVector_Bit2_Res "null";
BA_ "sigConfig" SG_ 1086 GW_CtrlBitVector_Bit2_Res "null";
BA_ "GenSigSendType" SG_ 1086 GW_CtrlBitVector_Bit2_Res 1;
BA_ "sigSecLevel" SG_ 1086 GW_CtrlBitVector_Bit3_NMCoord "null";
BA_ "sigExplanation" SG_ 1086 GW_CtrlBitVector_Bit3_NMCoord "null";
BA_ "sigConfig" SG_ 1086 GW_CtrlBitVector_Bit3_NMCoord "null";
BA_ "GenSigSendType" SG_ 1086 GW_CtrlBitVector_Bit3_NMCoord 1;
BA_ "sigSecLevel" SG_ 1086 GW_CtrlBitVector_Bit4_ActWake "null";
BA_ "sigExplanation" SG_ 1086 GW_CtrlBitVector_Bit4_ActWake "null";
BA_ "sigConfig" SG_ 1086 GW_CtrlBitVector_Bit4_ActWake "null";
BA_ "GenSigSendType" SG_ 1086 GW_CtrlBitVector_Bit4_ActWake 1;
BA_ "sigSecLevel" SG_ 1086 GW_CtrlBitVector_Bit5_Res "null";
BA_ "sigExplanation" SG_ 1086 GW_CtrlBitVector_Bit5_Res "null";
BA_ "sigConfig" SG_ 1086 GW_CtrlBitVector_Bit5_Res "null";
BA_ "GenSigSendType" SG_ 1086 GW_CtrlBitVector_Bit5_Res 1;
BA_ "sigSecLevel" SG_ 1086 GW_CtrlBitVector_Bit6_PNI "null";
BA_ "sigExplanation" SG_ 1086 GW_CtrlBitVector_Bit6_PNI "null";
BA_ "sigConfig" SG_ 1086 GW_CtrlBitVector_Bit6_PNI "null";
BA_ "GenSigSendType" SG_ 1086 GW_CtrlBitVector_Bit6_PNI 1;
BA_ "sigSecLevel" SG_ 1086 GW_CtrlBitVector_Bit7_Res "null";
BA_ "sigExplanation" SG_ 1086 GW_CtrlBitVector_Bit7_Res "null";
BA_ "sigConfig" SG_ 1086 GW_CtrlBitVector_Bit7_Res "null";
BA_ "GenSigSendType" SG_ 1086 GW_CtrlBitVector_Bit7_Res 1;
BA_ "sigSecLevel" SG_ 1086 GW_UsrData0 "null";
BA_ "sigExplanation" SG_ 1086 GW_UsrData0 "null";
BA_ "sigConfig" SG_ 1086 GW_UsrData0 "null";
BA_ "GenSigStartValue" SG_ 1086 GW_UsrData0 255;
BA_ "GenSigSendType" SG_ 1086 GW_UsrData0 1;
BA_ "sigSecLevel" SG_ 1086 GW_UsrData1_Bit0_IGN_WAKEUP "null";
BA_ "sigExplanation" SG_ 1086 GW_UsrData1_Bit0_IGN_WAKEUP "null";
BA_ "sigConfig" SG_ 1086 GW_UsrData1_Bit0_IGN_WAKEUP "null";
BA_ "GenSigSendType" SG_ 1086 GW_UsrData1_Bit0_IGN_WAKEUP 1;
BA_ "sigSecLevel" SG_ 1086 GW_UsrData1_Bit1_RESET_WAKEUP "null";
BA_ "sigExplanation" SG_ 1086 GW_UsrData1_Bit1_RESET_WAKEUP "null";
BA_ "sigConfig" SG_ 1086 GW_UsrData1_Bit1_RESET_WAKEUP "null";
BA_ "GenSigSendType" SG_ 1086 GW_UsrData1_Bit1_RESET_WAKEUP 1;
BA_ "sigSecLevel" SG_ 1086 GW_UsrData1_Bit2_NETWORK_WAKEUP "null";
BA_ "sigExplanation" SG_ 1086 GW_UsrData1_Bit2_NETWORK_WAKEUP "null";
BA_ "sigConfig" SG_ 1086 GW_UsrData1_Bit2_NETWORK_WAKEUP "null";
BA_ "GenSigSendType" SG_ 1086 GW_UsrData1_Bit2_NETWORK_WAKEUP 1;
BA_ "sigSecLevel" SG_ 1086 GW_UsrData1_Bit3_ECUSPEC_WAKEUP "null";
BA_ "sigExplanation" SG_ 1086 GW_UsrData1_Bit3_ECUSPEC_WAKEUP "null";
BA_ "sigConfig" SG_ 1086 GW_UsrData1_Bit3_ECUSPEC_WAKEUP "null";
BA_ "GenSigSendType" SG_ 1086 GW_UsrData1_Bit3_ECUSPEC_WAKEUP 1;
BA_ "sigSecLevel" SG_ 1086 GW_UsrData1_Bit4_NETWORK_AWAKE "null";
BA_ "sigExplanation" SG_ 1086 GW_UsrData1_Bit4_NETWORK_AWAKE "null";
BA_ "sigConfig" SG_ 1086 GW_UsrData1_Bit4_NETWORK_AWAKE "null";
BA_ "GenSigSendType" SG_ 1086 GW_UsrData1_Bit4_NETWORK_AWAKE 1;
BA_ "sigSecLevel" SG_ 1086 GW_UsrData1_Bit5_IGNITION_AWAKE "null";
BA_ "sigExplanation" SG_ 1086 GW_UsrData1_Bit5_IGNITION_AWAKE "null";
BA_ "sigConfig" SG_ 1086 GW_UsrData1_Bit5_IGNITION_AWAKE "null";
BA_ "GenSigSendType" SG_ 1086 GW_UsrData1_Bit5_IGNITION_AWAKE 1;
BA_ "sigSecLevel" SG_ 1086 GW_UsrData1_Bit6_DIAGN_AWAKE "null";
BA_ "sigExplanation" SG_ 1086 GW_UsrData1_Bit6_DIAGN_AWAKE "null";
BA_ "sigConfig" SG_ 1086 GW_UsrData1_Bit6_DIAGN_AWAKE "null";
BA_ "GenSigSendType" SG_ 1086 GW_UsrData1_Bit6_DIAGN_AWAKE 1;
BA_ "sigSecLevel" SG_ 1086 GW_UsrData1_Bit7_ECUSPEC_AWAKE "null";
BA_ "sigExplanation" SG_ 1086 GW_UsrData1_Bit7_ECUSPEC_AWAKE "null";
BA_ "sigConfig" SG_ 1086 GW_UsrData1_Bit7_ECUSPEC_AWAKE "null";
BA_ "GenSigSendType" SG_ 1086 GW_UsrData1_Bit7_ECUSPEC_AWAKE 1;
BA_ "sigSecLevel" SG_ 1086 GW_UsrData2 "null";
BA_ "sigExplanation" SG_ 1086 GW_UsrData2 "null";
BA_ "sigConfig" SG_ 1086 GW_UsrData2 "null";
BA_ "GenSigStartValue" SG_ 1086 GW_UsrData2 255;
BA_ "GenSigSendType" SG_ 1086 GW_UsrData2 1;
BA_ "sigSecLevel" SG_ 1086 GW_UsrData3 "null";
BA_ "sigExplanation" SG_ 1086 GW_UsrData3 "null";
BA_ "sigConfig" SG_ 1086 GW_UsrData3 "null";
BA_ "GenSigStartValue" SG_ 1086 GW_UsrData3 255;
BA_ "GenSigSendType" SG_ 1086 GW_UsrData3 1;
BA_ "sigSecLevel" SG_ 1086 GW_UsrData4_PN_Info1 "null";
BA_ "sigExplanation" SG_ 1086 GW_UsrData4_PN_Info1 "null";
BA_ "sigConfig" SG_ 1086 GW_UsrData4_PN_Info1 "null";
BA_ "GenSigStartValue" SG_ 1086 GW_UsrData4_PN_Info1 255;
BA_ "GenSigSendType" SG_ 1086 GW_UsrData4_PN_Info1 1;
BA_ "sigSecLevel" SG_ 1086 GW_UsrData5_PN_Info2 "null";
BA_ "sigExplanation" SG_ 1086 GW_UsrData5_PN_Info2 "null";
BA_ "sigConfig" SG_ 1086 GW_UsrData5_PN_Info2 "null";
BA_ "GenSigStartValue" SG_ 1086 GW_UsrData5_PN_Info2 255;
BA_ "GenSigSendType" SG_ 1086 GW_UsrData5_PN_Info2 1;
BA_ "sigSecLevel" SG_ 1159 FCM_ComLostFlt_ESP "null";
BA_ "sigExplanation" SG_ 1159 FCM_ComLostFlt_ESP "null";
BA_ "sigConfig" SG_ 1159 FCM_ComLostFlt_ESP "null";
BA_ "sigSecLevel" SG_ 1159 FCM_ComLostFlt_iBooster "null";
BA_ "sigExplanation" SG_ 1159 FCM_ComLostFlt_iBooster "null";
BA_ "sigConfig" SG_ 1159 FCM_ComLostFlt_iBooster "null";
BA_ "sigSecLevel" SG_ 1159 FCM_ComLostFlt_EPS "null";
BA_ "sigExplanation" SG_ 1159 FCM_ComLostFlt_EPS "null";
BA_ "sigConfig" SG_ 1159 FCM_ComLostFlt_EPS "null";
BA_ "sigSecLevel" SG_ 1159 FCM_ComLostFlt_YRS "null";
BA_ "sigExplanation" SG_ 1159 FCM_ComLostFlt_YRS "null";
BA_ "sigConfig" SG_ 1159 FCM_ComLostFlt_YRS "null";
BA_ "sigSecLevel" SG_ 1159 FCM_ComLostFlt_BCM "null";
BA_ "sigExplanation" SG_ 1159 FCM_ComLostFlt_BCM "null";
BA_ "sigConfig" SG_ 1159 FCM_ComLostFlt_BCM "null";
BA_ "sigSecLevel" SG_ 1159 FCM_ComLostFlt_ECC "null";
BA_ "sigExplanation" SG_ 1159 FCM_ComLostFlt_ECC "null";
BA_ "sigConfig" SG_ 1159 FCM_ComLostFlt_ECC "null";
BA_ "sigSecLevel" SG_ 1159 FCM_ComLostFlt_TBOX "null";
BA_ "sigExplanation" SG_ 1159 FCM_ComLostFlt_TBOX "null";
BA_ "sigConfig" SG_ 1159 FCM_ComLostFlt_TBOX "null";
BA_ "sigSecLevel" SG_ 1159 FCM_ComLostFlt_CIM "null";
BA_ "sigExplanation" SG_ 1159 FCM_ComLostFlt_CIM "null";
BA_ "sigConfig" SG_ 1159 FCM_ComLostFlt_CIM "null";
BA_ "sigSecLevel" SG_ 1159 FCM_ComLostFlt_ICC "null";
BA_ "sigExplanation" SG_ 1159 FCM_ComLostFlt_ICC "null";
BA_ "sigConfig" SG_ 1159 FCM_ComLostFlt_ICC "null";
BA_ "sigSecLevel" SG_ 1159 FCM_ComLostFlt_MRR "null";
BA_ "sigExplanation" SG_ 1159 FCM_ComLostFlt_MRR "null";
BA_ "sigConfig" SG_ 1159 FCM_ComLostFlt_MRR "null";
BA_ "sigSecLevel" SG_ 1159 FCM_ComLostFlt_PEPS "null";
BA_ "sigExplanation" SG_ 1159 FCM_ComLostFlt_PEPS "null";
BA_ "sigConfig" SG_ 1159 FCM_ComLostFlt_PEPS "null";
BA_ "sigSecLevel" SG_ 1159 FCM_ComLostFlt_ADAS "null";
BA_ "sigExplanation" SG_ 1159 FCM_ComLostFlt_ADAS "null";
BA_ "sigConfig" SG_ 1159 FCM_ComLostFlt_ADAS "null";
BA_ "sigSecLevel" SG_ 1159 FCM_ComE2EFlt "null";
BA_ "sigExplanation" SG_ 1159 FCM_ComE2EFlt "null";
BA_ "sigConfig" SG_ 1159 FCM_ComE2EFlt "null";
BA_ "sigSecLevel" SG_ 1159 FCM_ChkInvldSig_ESP "null";
BA_ "sigExplanation" SG_ 1159 FCM_ChkInvldSig_ESP "null";
BA_ "sigConfig" SG_ 1159 FCM_ChkInvldSig_ESP "null";
BA_ "sigSecLevel" SG_ 1159 FCM_ChkInvldSig_iBooster "null";
BA_ "sigExplanation" SG_ 1159 FCM_ChkInvldSig_iBooster "null";
BA_ "sigConfig" SG_ 1159 FCM_ChkInvldSig_iBooster "null";
BA_ "sigSecLevel" SG_ 1159 FCM_ChkInvldSig_EPS "null";
BA_ "sigExplanation" SG_ 1159 FCM_ChkInvldSig_EPS "null";
BA_ "sigConfig" SG_ 1159 FCM_ChkInvldSig_EPS "null";
BA_ "sigSecLevel" SG_ 1159 FCM_ChkInvldSig_YRS "null";
BA_ "sigExplanation" SG_ 1159 FCM_ChkInvldSig_YRS "null";
BA_ "sigConfig" SG_ 1159 FCM_ChkInvldSig_YRS "null";
BA_ "sigSecLevel" SG_ 1159 FCM_ChkInvldSig_CIM "null";
BA_ "sigExplanation" SG_ 1159 FCM_ChkInvldSig_CIM "null";
BA_ "sigConfig" SG_ 1159 FCM_ChkInvldSig_CIM "null";
BA_ "sigSecLevel" SG_ 1159 FCM_ChkInvldSig_ECC "null";
BA_ "sigExplanation" SG_ 1159 FCM_ChkInvldSig_ECC "null";
BA_ "sigConfig" SG_ 1159 FCM_ChkInvldSig_ECC "null";
BA_ "sigSecLevel" SG_ 1159 FCM_ChkInvldSig_PEPS "null";
BA_ "sigExplanation" SG_ 1159 FCM_ChkInvldSig_PEPS "null";
BA_ "sigConfig" SG_ 1159 FCM_ChkInvldSig_PEPS "null";
BA_ "sigSecLevel" SG_ 1159 FCM_ChkInvldSig_ICC "null";
BA_ "sigExplanation" SG_ 1159 FCM_ChkInvldSig_ICC "null";
BA_ "sigConfig" SG_ 1159 FCM_ChkInvldSig_ICC "null";
BA_ "sigSecLevel" SG_ 1159 FCM_ChkPrivateCANBusOff "null";
BA_ "sigExplanation" SG_ 1159 FCM_ChkPrivateCANBusOff "null";
BA_ "sigConfig" SG_ 1159 FCM_ChkPrivateCANBusOff "null";
BA_ "sigSecLevel" SG_ 1159 FCM_ChkPublicCANBusOff "null";
BA_ "sigExplanation" SG_ 1159 FCM_ChkPublicCANBusOff "null";
BA_ "sigConfig" SG_ 1159 FCM_ChkPublicCANBusOff "null";
BA_ "sigSecLevel" SG_ 1159 FCM_BattVoltBelowThd "null";
BA_ "sigExplanation" SG_ 1159 FCM_BattVoltBelowThd "null";
BA_ "sigConfig" SG_ 1159 FCM_BattVoltBelowThd "null";
BA_ "sigSecLevel" SG_ 1159 FCM_BattVoltOverThd "null";
BA_ "sigExplanation" SG_ 1159 FCM_BattVoltOverThd "null";
BA_ "sigConfig" SG_ 1159 FCM_BattVoltOverThd "null";
BA_ "sigSecLevel" SG_ 1159 FCM_CamBli "null";
BA_ "sigExplanation" SG_ 1159 FCM_CamBli "null";
BA_ "sigConfig" SG_ 1159 FCM_CamBli "null";
BA_ "sigSecLevel" SG_ 1159 FCM_ECUTmpHiTProtn "null";
BA_ "sigExplanation" SG_ 1159 FCM_ECUTmpHiTProtn "null";
BA_ "sigConfig" SG_ 1159 FCM_ECUTmpHiTProtn "null";
BA_ "sigSecLevel" SG_ 1159 FCM_IntCircOutpVoltBelowThd "null";
BA_ "sigExplanation" SG_ 1159 FCM_IntCircOutpVoltBelowThd "null";
BA_ "sigConfig" SG_ 1159 FCM_IntCircOutpVoltBelowThd "null";
BA_ "sigSecLevel" SG_ 1159 FCM_IntCircOutpVoltOverThd "null";
BA_ "sigExplanation" SG_ 1159 FCM_IntCircOutpVoltOverThd "null";
BA_ "sigConfig" SG_ 1159 FCM_IntCircOutpVoltOverThd "null";
BA_ "sigSecLevel" SG_ 1159 FCM_IntCircPrmntFlt "null";
BA_ "sigExplanation" SG_ 1159 FCM_IntCircPrmntFlt "null";
BA_ "sigConfig" SG_ 1159 FCM_IntCircPrmntFlt "null";
BA_ "sigSecLevel" SG_ 1159 FCM_MatchParaErr "null";
BA_ "sigExplanation" SG_ 1159 FCM_MatchParaErr "null";
BA_ "sigConfig" SG_ 1159 FCM_MatchParaErr "null";
BA_ "sigSecLevel" SG_ 1159 FCM_VehCfgInfoErr "null";
BA_ "sigExplanation" SG_ 1159 FCM_VehCfgInfoErr "null";
BA_ "sigConfig" SG_ 1159 FCM_VehCfgInfoErr "null";
BA_ "sigSecLevel" SG_ 1159 FCM_IntCircFlt "null";
BA_ "sigExplanation" SG_ 1159 FCM_IntCircFlt "null";
BA_ "sigConfig" SG_ 1159 FCM_IntCircFlt "null";
BA_ "sigSecLevel" SG_ 1159 FCM_DLCFlt_ESP "null";
BA_ "sigExplanation" SG_ 1159 FCM_DLCFlt_ESP "null";
BA_ "sigConfig" SG_ 1159 FCM_DLCFlt_ESP "null";
BA_ "sigSecLevel" SG_ 1159 FCM_DLCFlt_iBooster "null";
BA_ "sigExplanation" SG_ 1159 FCM_DLCFlt_iBooster "null";
BA_ "sigConfig" SG_ 1159 FCM_DLCFlt_iBooster "null";
BA_ "sigSecLevel" SG_ 1159 FCM_DLCFlt_EPS "null";
BA_ "sigExplanation" SG_ 1159 FCM_DLCFlt_EPS "null";
BA_ "sigConfig" SG_ 1159 FCM_DLCFlt_EPS "null";
BA_ "sigSecLevel" SG_ 1159 FCM_DLCFlt_YRS "null";
BA_ "sigExplanation" SG_ 1159 FCM_DLCFlt_YRS "null";
BA_ "sigConfig" SG_ 1159 FCM_DLCFlt_YRS "null";
BA_ "sigSecLevel" SG_ 1159 FCM_DLCFlt_BCM "null";
BA_ "sigExplanation" SG_ 1159 FCM_DLCFlt_BCM "null";
BA_ "sigConfig" SG_ 1159 FCM_DLCFlt_BCM "null";
BA_ "sigSecLevel" SG_ 1159 FCM_DLCFlt_ECC "null";
BA_ "sigExplanation" SG_ 1159 FCM_DLCFlt_ECC "null";
BA_ "sigConfig" SG_ 1159 FCM_DLCFlt_ECC "null";
BA_ "sigSecLevel" SG_ 1159 FCM_DLCFlt_TBOX "null";
BA_ "sigExplanation" SG_ 1159 FCM_DLCFlt_TBOX "null";
BA_ "sigConfig" SG_ 1159 FCM_DLCFlt_TBOX "null";
BA_ "sigSecLevel" SG_ 1159 FCM_DLCFlt_CIM "null";
BA_ "sigExplanation" SG_ 1159 FCM_DLCFlt_CIM "null";
BA_ "sigConfig" SG_ 1159 FCM_DLCFlt_CIM "null";
BA_ "sigSecLevel" SG_ 1159 FCM_DLCFlt_ICC "null";
BA_ "sigExplanation" SG_ 1159 FCM_DLCFlt_ICC "null";
BA_ "sigConfig" SG_ 1159 FCM_DLCFlt_ICC "null";
BA_ "sigSecLevel" SG_ 1159 FCM_DLCFlt_MRR "null";
BA_ "sigExplanation" SG_ 1159 FCM_DLCFlt_MRR "null";
BA_ "sigConfig" SG_ 1159 FCM_DLCFlt_MRR "null";
BA_ "sigSecLevel" SG_ 1159 FCM_DLCFlt_PEPS "null";
BA_ "sigExplanation" SG_ 1159 FCM_DLCFlt_PEPS "null";
BA_ "sigConfig" SG_ 1159 FCM_DLCFlt_PEPS "null";
BA_ "sigSecLevel" SG_ 1159 FCM_DLCFlt_ADAS "null";
BA_ "sigExplanation" SG_ 1159 FCM_DLCFlt_ADAS "null";
BA_ "sigConfig" SG_ 1159 FCM_DLCFlt_ADAS "null";
BA_ "sigSecLevel" SG_ 1159 FCM_OnlineCalOutOfRng "null";
BA_ "sigExplanation" SG_ 1159 FCM_OnlineCalOutOfRng "null";
BA_ "sigConfig" SG_ 1159 FCM_OnlineCalOutOfRng "null";
BA_ "sigSecLevel" SG_ 1159 FCM_IniCalOutOfRng "null";
BA_ "sigExplanation" SG_ 1159 FCM_IniCalOutOfRng "null";
BA_ "sigConfig" SG_ 1159 FCM_IniCalOutOfRng "null";
BA_ "sigSecLevel" SG_ 1159 FCM_IniCalTimeout "null";
BA_ "sigExplanation" SG_ 1159 FCM_IniCalTimeout "null";
BA_ "sigConfig" SG_ 1159 FCM_IniCalTimeout "null";
BA_ "sigSecLevel" SG_ 1159 FCM_NotCal "null";
BA_ "sigExplanation" SG_ 1159 FCM_NotCal "null";
BA_ "sigConfig" SG_ 1159 FCM_NotCal "null";
BA_ "sigSecLevel" SG_ 1268 TBOX_4F4_4F8_CheckSum "null";
BA_ "sigExplanation" SG_ 1268 TBOX_4F4_4F8_CheckSum "null";
BA_ "sigConfig" SG_ 1268 TBOX_4F4_4F8_CheckSum "null";
BA_ "sigSecLevel" SG_ 1268 TBOX_4F4_4F8_AliveCounter "null";
BA_ "sigExplanation" SG_ 1268 TBOX_4F4_4F8_AliveCounter "null";
BA_ "sigConfig" SG_ 1268 TBOX_4F4_4F8_AliveCounter "null";
BA_ "GenSigSendType" SG_ 1268 TBOX_Sw_upd 2;
BA_ "GenSigSendType" SG_ 1268 TBOX_RemFlsh 2;
BA_ "sigSecLevel" SG_ 1268 TBOX_FobdGWPartBUSUDSCom "null";
BA_ "sigExplanation" SG_ 1268 TBOX_FobdGWPartBUSUDSCom "null";
BA_ "sigConfig" SG_ 1268 TBOX_FobdGWPartBUSUDSCom "null";
BA_ "GenSigSendType" SG_ 1268 TBOX_FobdGWPartBUSUDSCom 2;
BA_ "sigSecLevel" SG_ 1268 TBOX_RemChrgInsulFctReq "null";
BA_ "sigExplanation" SG_ 1268 TBOX_RemChrgInsulFctReq "null";
BA_ "sigConfig" SG_ 1268 TBOX_RemChrgInsulFctReq "null";
BA_ "GenSigSendType" SG_ 1268 TBOX_RemChrgInsulFctReq 2;
BA_ "sigSecLevel" SG_ 1268 TBOX_EHUSetTrvlMod "null";
BA_ "sigExplanation" SG_ 1268 TBOX_EHUSetTrvlMod "null";
BA_ "sigConfig" SG_ 1268 TBOX_EHUSetTrvlMod "null";
BA_ "sigSecLevel" SG_ 1268 TBOX_ResvACChrgOpenSts "null";
BA_ "sigExplanation" SG_ 1268 TBOX_ResvACChrgOpenSts "null";
BA_ "sigConfig" SG_ 1268 TBOX_ResvACChrgOpenSts "null";
BA_ "sigSecLevel" SG_ 1268 TBOX_RemKL15PwrOnReq "null";
BA_ "sigExplanation" SG_ 1268 TBOX_RemKL15PwrOnReq "null";
BA_ "sigConfig" SG_ 1268 TBOX_RemKL15PwrOnReq "null";
BA_ "GenSigSendType" SG_ 1268 TBOX_RemKL15PwrOnReq 2;
BA_ "sigSecLevel" SG_ 1268 TBOX_SetChrgEndSOC "null";
BA_ "sigExplanation" SG_ 1268 TBOX_SetChrgEndSOC "null";
BA_ "sigConfig" SG_ 1268 TBOX_SetChrgEndSOC "null";
BA_ "sigSecLevel" SG_ 1268 TBOX_PreCondTriggerReq "null";
BA_ "sigExplanation" SG_ 1268 TBOX_PreCondTriggerReq "null";
BA_ "sigConfig" SG_ 1268 TBOX_PreCondTriggerReq "null";
BA_ "sigSecLevel" SG_ 1268 TBOX_BlowLvlReq "null";
BA_ "sigExplanation" SG_ 1268 TBOX_BlowLvlReq "null";
BA_ "sigConfig" SG_ 1268 TBOX_BlowLvlReq "null";
BA_ "GenSigSendType" SG_ 1268 TBOX_ICC_UpdStrt 2;
BA_ "sigSecLevel" SG_ 1268 TBOX_VehiMod "null";
BA_ "sigExplanation" SG_ 1268 TBOX_VehiMod "null";
BA_ "sigConfig" SG_ 1268 TBOX_VehiMod "null";
BA_ "GenSigSendType" SG_ 1268 TBOX_Crash_cfm 4;
BA_ "GenSigInactiveValue" SG_ 1268 TBOX_Crash_cfm 1;
BA_ "GenSigCycleTime" SG_ 1268 TBOX_Crash_cfm 100;
BA_ "sigSecLevel" SG_ 1268 TBOX_4F4_SSecOC_Fresh_Byte0 "null";
BA_ "sigExplanation" SG_ 1268 TBOX_4F4_SSecOC_Fresh_Byte0 "null";
BA_ "sigConfig" SG_ 1268 TBOX_4F4_SSecOC_Fresh_Byte0 "null";
BA_ "sigSecLevel" SG_ 1268 TBOX_4F4_SSecOC_MAC_Byte0 "null";
BA_ "sigExplanation" SG_ 1268 TBOX_4F4_SSecOC_MAC_Byte0 "null";
BA_ "sigConfig" SG_ 1268 TBOX_4F4_SSecOC_MAC_Byte0 "null";
BA_ "sigSecLevel" SG_ 1268 TBOX_4F4_SSecOC_MAC_Byte1 "null";
BA_ "sigExplanation" SG_ 1268 TBOX_4F4_SSecOC_MAC_Byte1 "null";
BA_ "sigConfig" SG_ 1268 TBOX_4F4_SSecOC_MAC_Byte1 "null";
BA_ "sigSecLevel" SG_ 1268 TBOX_4F4_SSecOC_MAC_Byte2 "null";
BA_ "sigExplanation" SG_ 1268 TBOX_4F4_SSecOC_MAC_Byte2 "null";
BA_ "sigConfig" SG_ 1268 TBOX_4F4_SSecOC_MAC_Byte2 "null";
BA_ "sigSecLevel" SG_ 1287 VCU_DrvAvl "null";
BA_ "sigExplanation" SG_ 1287 VCU_DrvAvl "null";
BA_ "sigConfig" SG_ 1287 VCU_DrvAvl "null";
BA_ "sigSecLevel" SG_ 1287 VCU_CllsnSigSts "null";
BA_ "sigExplanation" SG_ 1287 VCU_CllsnSigSts "null";
BA_ "sigConfig" SG_ 1287 VCU_CllsnSigSts "null";
BA_ "sigSecLevel" SG_ 1287 VCU_VehSts_GB "null";
BA_ "sigExplanation" SG_ 1287 VCU_VehSts_GB "null";
BA_ "sigConfig" SG_ 1287 VCU_VehSts_GB "null";
BA_ "sigSecLevel" SG_ 1287 VCU_MCUOverTFlt_GB "null";
BA_ "sigExplanation" SG_ 1287 VCU_MCUOverTFlt_GB "null";
BA_ "sigConfig" SG_ 1287 VCU_MCUOverTFlt_GB "null";
BA_ "sigSecLevel" SG_ 1287 VCU_DrvrMotOverTFlt_GB "null";
BA_ "sigExplanation" SG_ 1287 VCU_DrvrMotOverTFlt_GB "null";
BA_ "sigConfig" SG_ 1287 VCU_DrvrMotOverTFlt_GB "null";
BA_ "sigSecLevel" SG_ 1287 VCU_SOCTooLoAlrm "null";
BA_ "sigExplanation" SG_ 1287 VCU_SOCTooLoAlrm "null";
BA_ "sigConfig" SG_ 1287 VCU_SOCTooLoAlrm "null";
BA_ "sigSecLevel" SG_ 1287 VCU_SOCJumpAlrm "null";
BA_ "sigExplanation" SG_ 1287 VCU_SOCJumpAlrm "null";
BA_ "sigConfig" SG_ 1287 VCU_SOCJumpAlrm "null";
BA_ "sigSecLevel" SG_ 1287 VCU_PwrBattPackMismatAlrm "null";
BA_ "sigExplanation" SG_ 1287 VCU_PwrBattPackMismatAlrm "null";
BA_ "sigConfig" SG_ 1287 VCU_PwrBattPackMismatAlrm "null";
BA_ "sigSecLevel" SG_ 1287 VCU_SOCTooHiAlrm "null";
BA_ "sigExplanation" SG_ 1287 VCU_SOCTooHiAlrm "null";
BA_ "sigConfig" SG_ 1287 VCU_SOCTooHiAlrm "null";
BA_ "sigSecLevel" SG_ 1287 VCU_DCDCEnaCmd "null";
BA_ "sigExplanation" SG_ 1287 VCU_DCDCEnaCmd "null";
BA_ "sigConfig" SG_ 1287 VCU_DCDCEnaCmd "null";
BA_ "sigSecLevel" SG_ 1287 VCU_PwrBattECCEnaCmd "null";
BA_ "sigExplanation" SG_ 1287 VCU_PwrBattECCEnaCmd "null";
BA_ "sigConfig" SG_ 1287 VCU_PwrBattECCEnaCmd "null";
BA_ "sigSecLevel" SG_ 1287 VCU_MstRlyCtrlCmd "null";
BA_ "sigExplanation" SG_ 1287 VCU_MstRlyCtrlCmd "null";
BA_ "sigConfig" SG_ 1287 VCU_MstRlyCtrlCmd "null";
BA_ "sigSecLevel" SG_ 1287 VCU_DCDCOutpVoltCmd "null";
BA_ "sigExplanation" SG_ 1287 VCU_DCDCOutpVoltCmd "null";
BA_ "sigConfig" SG_ 1287 VCU_DCDCOutpVoltCmd "null";
BA_ "sigSecLevel" SG_ 1287 VCU_CCCnctnVolt "null";
BA_ "sigExplanation" SG_ 1287 VCU_CCCnctnVolt "null";
BA_ "sigConfig" SG_ 1287 VCU_CCCnctnVolt "null";
BA_ "sigSecLevel" SG_ 1287 VCU_GearSig_GB "null";
BA_ "sigExplanation" SG_ 1287 VCU_GearSig_GB "null";
BA_ "sigConfig" SG_ 1287 VCU_GearSig_GB "null";
BA_ "sigSecLevel" SG_ 1287 VCU_DrvrMotNr_GB "null";
BA_ "sigExplanation" SG_ 1287 VCU_DrvrMotNr_GB "null";
BA_ "sigConfig" SG_ 1287 VCU_DrvrMotNr_GB "null";
BA_ "sigSecLevel" SG_ 1287 VCU_BattVolt "null";
BA_ "sigExplanation" SG_ 1287 VCU_BattVolt "null";
BA_ "sigConfig" SG_ 1287 VCU_BattVolt "null";
BA_ "sigSecLevel" SG_ 1297 VCU_BMSLVWakeUpSts "null";
BA_ "sigExplanation" SG_ 1297 VCU_BMSLVWakeUpSts "null";
BA_ "sigConfig" SG_ 1297 VCU_BMSLVWakeUpSts "null";
BA_ "sigSecLevel" SG_ 1297 VCU_ONWakeUpSig "null";
BA_ "sigExplanation" SG_ 1297 VCU_ONWakeUpSig "null";
BA_ "sigConfig" SG_ 1297 VCU_ONWakeUpSig "null";
BA_ "sigSecLevel" SG_ 1297 VCU_FCWakeUpSig "null";
BA_ "sigExplanation" SG_ 1297 VCU_FCWakeUpSig "null";
BA_ "sigConfig" SG_ 1297 VCU_FCWakeUpSig "null";
BA_ "sigSecLevel" SG_ 1297 VCU_SCWakeUpSig "null";
BA_ "sigExplanation" SG_ 1297 VCU_SCWakeUpSig "null";
BA_ "sigConfig" SG_ 1297 VCU_SCWakeUpSig "null";
BA_ "sigSecLevel" SG_ 1297 VCU_RemWakeUpSig "null";
BA_ "sigExplanation" SG_ 1297 VCU_RemWakeUpSig "null";
BA_ "sigConfig" SG_ 1297 VCU_RemWakeUpSig "null";
BA_ "sigSecLevel" SG_ 1297 VCU_NetWakeUpSig "null";
BA_ "sigExplanation" SG_ 1297 VCU_NetWakeUpSig "null";
BA_ "sigConfig" SG_ 1297 VCU_NetWakeUpSig "null";
BA_ "sigSecLevel" SG_ 1297 VCU_LVWakeUpSts_PDU "null";
BA_ "sigExplanation" SG_ 1297 VCU_LVWakeUpSts_PDU "null";
BA_ "sigConfig" SG_ 1297 VCU_LVWakeUpSts_PDU "null";
BA_ "sigSecLevel" SG_ 1297 VCU_VehEOLFctFlg "null";
BA_ "sigExplanation" SG_ 1297 VCU_VehEOLFctFlg "null";
BA_ "sigConfig" SG_ 1297 VCU_VehEOLFctFlg "null";
BA_ "sigSecLevel" SG_ 1297 VCU_LVWakeUpSts_MCU "null";
BA_ "sigExplanation" SG_ 1297 VCU_LVWakeUpSts_MCU "null";
BA_ "sigConfig" SG_ 1297 VCU_LVWakeUpSts_MCU "null";
BA_ "sigSecLevel" SG_ 1297 VCU_PwrAntithefAllwtRdyFlg "null";
BA_ "sigExplanation" SG_ 1297 VCU_PwrAntithefAllwtRdyFlg "null";
BA_ "sigConfig" SG_ 1297 VCU_PwrAntithefAllwtRdyFlg "null";
BA_ "sigSecLevel" SG_ 1297 VCU_LVWakeUpSts_CCU "null";
BA_ "sigExplanation" SG_ 1297 VCU_LVWakeUpSts_CCU "null";
BA_ "sigConfig" SG_ 1297 VCU_LVWakeUpSts_CCU "null";
BA_ "sigSecLevel" SG_ 1297 VCU_RemECCEndCmd "null";
BA_ "sigExplanation" SG_ 1297 VCU_RemECCEndCmd "null";
BA_ "sigConfig" SG_ 1297 VCU_RemECCEndCmd "null";
BA_ "sigSecLevel" SG_ 1297 VCU_EvChrgElectcLockCtrlCmd "null";
BA_ "sigExplanation" SG_ 1297 VCU_EvChrgElectcLockCtrlCmd "null";
BA_ "sigConfig" SG_ 1297 VCU_EvChrgElectcLockCtrlCmd "null";
BA_ "sigSecLevel" SG_ 1297 VCU_RemPwrBattHeatgEndCmd "null";
BA_ "sigExplanation" SG_ 1297 VCU_RemPwrBattHeatgEndCmd "null";
BA_ "sigConfig" SG_ 1297 VCU_RemPwrBattHeatgEndCmd "null";
BA_ "sigSecLevel" SG_ 1297 VCU_RemChrgEndCmd "null";
BA_ "sigExplanation" SG_ 1297 VCU_RemChrgEndCmd "null";
BA_ "sigConfig" SG_ 1297 VCU_RemChrgEndCmd "null";
BA_ "sigSecLevel" SG_ 1297 VCU_RemBattHeatgFailReason "null";
BA_ "sigExplanation" SG_ 1297 VCU_RemBattHeatgFailReason "null";
BA_ "sigConfig" SG_ 1297 VCU_RemBattHeatgFailReason "null";
BA_ "sigSecLevel" SG_ 1297 VCU_RemECCEndReason "null";
BA_ "sigExplanation" SG_ 1297 VCU_RemECCEndReason "null";
BA_ "sigConfig" SG_ 1297 VCU_RemECCEndReason "null";
BA_ "sigSecLevel" SG_ 1297 VCU_RemChrgEndReason "null";
BA_ "sigExplanation" SG_ 1297 VCU_RemChrgEndReason "null";
BA_ "sigConfig" SG_ 1297 VCU_RemChrgEndReason "null";
BA_ "sigSecLevel" SG_ 1297 VCU_VehMod "null";
BA_ "sigExplanation" SG_ 1297 VCU_VehMod "null";
BA_ "sigConfig" SG_ 1297 VCU_VehMod "null";
BA_ "GenSigStartValue" SG_ 1297 VCU_VehMod 14;
BA_ "sigSecLevel" SG_ 1297 VCU_VehCrtChrgEndSOC "null";
BA_ "sigExplanation" SG_ 1297 VCU_VehCrtChrgEndSOC "null";
BA_ "sigConfig" SG_ 1297 VCU_VehCrtChrgEndSOC "null";
BA_ "sigSecLevel" SG_ 1297 VCU_CalSwVers "null";
BA_ "sigExplanation" SG_ 1297 VCU_CalSwVers "null";
BA_ "sigConfig" SG_ 1297 VCU_CalSwVers "null";
BA_ "sigSecLevel" SG_ 1297 VCU_RemPwrBattPreheatgEndFlg "null";
BA_ "sigExplanation" SG_ 1297 VCU_RemPwrBattPreheatgEndFlg "null";
BA_ "sigConfig" SG_ 1297 VCU_RemPwrBattPreheatgEndFlg "null";
BA_ "sigSecLevel" SG_ 1297 VCU_VehOperMod "null";
BA_ "sigExplanation" SG_ 1297 VCU_VehOperMod "null";
BA_ "sigConfig" SG_ 1297 VCU_VehOperMod "null";
BA_ "sigSecLevel" SG_ 1297 VCU_VehRemRefrshModReq "null";
BA_ "sigExplanation" SG_ 1297 VCU_VehRemRefrshModReq "null";
BA_ "sigConfig" SG_ 1297 VCU_VehRemRefrshModReq "null";
BA_ "sigSecLevel" SG_ 1297 VCU_RemDTCPwrOnReq "null";
BA_ "sigExplanation" SG_ 1297 VCU_RemDTCPwrOnReq "null";
BA_ "sigConfig" SG_ 1297 VCU_RemDTCPwrOnReq "null";
BA_ "sigSecLevel" SG_ 1329 ICC_TotMilgVld_ODO "null";
BA_ "sigExplanation" SG_ 1329 ICC_TotMilgVld_ODO "null";
BA_ "sigConfig" SG_ 1329 ICC_TotMilgVld_ODO "null";
BA_ "sigSecLevel" SG_ 1329 ICC_TotMilg_ODO "null";
BA_ "sigExplanation" SG_ 1329 ICC_TotMilg_ODO "null";
BA_ "sigConfig" SG_ 1329 ICC_TotMilg_ODO "null";
BA_ "sigSecLevel" SG_ 1329 ICC_DispVehSpd "null";
BA_ "sigExplanation" SG_ 1329 ICC_DispVehSpd "null";
BA_ "sigConfig" SG_ 1329 ICC_DispVehSpd "null";
BA_ "sigSecLevel" SG_ 1329 ICC_DispVehSpdUnit "null";
BA_ "sigExplanation" SG_ 1329 ICC_DispVehSpdUnit "null";
BA_ "sigConfig" SG_ 1329 ICC_DispVehSpdUnit "null";
BA_ "sigSecLevel" SG_ 1329 ICC_ADASSigFlt "null";
BA_ "sigExplanation" SG_ 1329 ICC_ADASSigFlt "null";
BA_ "sigConfig" SG_ 1329 ICC_ADASSigFlt "null";
BA_ "sigSecLevel" SG_ 1329 ICC_DispFlt "null";
BA_ "sigExplanation" SG_ 1329 ICC_DispFlt "null";
BA_ "sigConfig" SG_ 1329 ICC_DispFlt "null";
BA_ "sigSecLevel" SG_ 1476 TBOX_TerminalRemWakeupSig "null";
BA_ "sigExplanation" SG_ 1476 TBOX_TerminalRemWakeupSig "null";
BA_ "sigConfig" SG_ 1476 TBOX_TerminalRemWakeupSig "null";
BA_ "sigSecLevel" SG_ 1476 TBOX_RemSCModReq "null";
BA_ "sigExplanation" SG_ 1476 TBOX_RemSCModReq "null";
BA_ "sigConfig" SG_ 1476 TBOX_RemSCModReq "null";
BA_ "sigSecLevel" SG_ 1476 TBOX_RemPwrBattOpenHeatgReq "null";
BA_ "sigExplanation" SG_ 1476 TBOX_RemPwrBattOpenHeatgReq "null";
BA_ "sigConfig" SG_ 1476 TBOX_RemPwrBattOpenHeatgReq "null";
BA_ "sigSecLevel" SG_ 1476 TBOX_RemPwrBattResvHeatgReq "null";
BA_ "sigExplanation" SG_ 1476 TBOX_RemPwrBattResvHeatgReq "null";
BA_ "sigConfig" SG_ 1476 TBOX_RemPwrBattResvHeatgReq "null";
BA_ "sigSecLevel" SG_ 1476 TBOX_RemInsdInfoDispEna "null";
BA_ "sigExplanation" SG_ 1476 TBOX_RemInsdInfoDispEna "null";
BA_ "sigConfig" SG_ 1476 TBOX_RemInsdInfoDispEna "null";
BA_ "sigSecLevel" SG_ 1476 TBOX_RemECCDefrstModReq "null";
BA_ "sigExplanation" SG_ 1476 TBOX_RemECCDefrstModReq "null";
BA_ "sigConfig" SG_ 1476 TBOX_RemECCDefrstModReq "null";
BA_ "sigSecLevel" SG_ 1476 TBOX_RemECCResvDefrstReq "null";
BA_ "sigExplanation" SG_ 1476 TBOX_RemECCResvDefrstReq "null";
BA_ "sigConfig" SG_ 1476 TBOX_RemECCResvDefrstReq "null";
BA_ "sigSecLevel" SG_ 1476 TBOX_RemECCSetT "null";
BA_ "sigExplanation" SG_ 1476 TBOX_RemECCSetT "null";
BA_ "sigConfig" SG_ 1476 TBOX_RemECCSetT "null";
BA_ "sigSecLevel" SG_ 1476 TBOX_RemResvECCSetT "null";
BA_ "sigExplanation" SG_ 1476 TBOX_RemResvECCSetT "null";
BA_ "sigConfig" SG_ 1476 TBOX_RemResvECCSetT "null";
BA_ "sigSecLevel" SG_ 1476 TBOX_RemSOCMax "null";
BA_ "sigExplanation" SG_ 1476 TBOX_RemSOCMax "null";
BA_ "sigConfig" SG_ 1476 TBOX_RemSOCMax "null";
BA_ "sigSecLevel" SG_ 1476 TBOX_4GSigIND "null";
BA_ "sigExplanation" SG_ 1476 TBOX_4GSigIND "null";
BA_ "sigConfig" SG_ 1476 TBOX_4GSigIND "null";
BA_ "sigSecLevel" SG_ 1476 TBOX_TSPNotConn "null";
BA_ "sigExplanation" SG_ 1476 TBOX_TSPNotConn "null";
BA_ "sigConfig" SG_ 1476 TBOX_TSPNotConn "null";
BA_ "sigSecLevel" SG_ 1476 TBOX_EHUNotCONN "null";
BA_ "sigExplanation" SG_ 1476 TBOX_EHUNotCONN "null";
BA_ "sigConfig" SG_ 1476 TBOX_EHUNotCONN "null";
BA_ "sigSecLevel" SG_ 1476 TBOX_WIFIError "null";
BA_ "sigExplanation" SG_ 1476 TBOX_WIFIError "null";
BA_ "sigConfig" SG_ 1476 TBOX_WIFIError "null";
BA_ "sigSecLevel" SG_ 1476 TBOX_InnerBattError "null";
BA_ "sigExplanation" SG_ 1476 TBOX_InnerBattError "null";
BA_ "sigConfig" SG_ 1476 TBOX_InnerBattError "null";
BA_ "sigSecLevel" SG_ 1476 TBOX_VoltLow "null";
BA_ "sigExplanation" SG_ 1476 TBOX_VoltLow "null";
BA_ "sigConfig" SG_ 1476 TBOX_VoltLow "null";
BA_ "sigSecLevel" SG_ 1476 TBOX_VoltHigh "null";
BA_ "sigExplanation" SG_ 1476 TBOX_VoltHigh "null";
BA_ "sigConfig" SG_ 1476 TBOX_VoltHigh "null";
BA_ "sigSecLevel" SG_ 1476 TBOX_4GLoss "null";
BA_ "sigExplanation" SG_ 1476 TBOX_4GLoss "null";
BA_ "sigConfig" SG_ 1476 TBOX_4GLoss "null";
BA_ "sigSecLevel" SG_ 1476 TBOX_RemSWH_Req "null";
BA_ "sigExplanation" SG_ 1476 TBOX_RemSWH_Req "null";
BA_ "sigConfig" SG_ 1476 TBOX_RemSWH_Req "null";
BA_ "sigSecLevel" SG_ 1476 TBOX_5C4_SSecOC_Fresh_Byte0 "null";
BA_ "sigExplanation" SG_ 1476 TBOX_5C4_SSecOC_Fresh_Byte0 "null";
BA_ "sigConfig" SG_ 1476 TBOX_5C4_SSecOC_Fresh_Byte0 "null";
BA_ "sigSecLevel" SG_ 1476 TBOX_5C4_SSecOC_MAC_Byte0 "null";
BA_ "sigExplanation" SG_ 1476 TBOX_5C4_SSecOC_MAC_Byte0 "null";
BA_ "sigConfig" SG_ 1476 TBOX_5C4_SSecOC_MAC_Byte0 "null";
BA_ "sigSecLevel" SG_ 1476 TBOX_5C4_SSecOC_MAC_Byte1 "null";
BA_ "sigExplanation" SG_ 1476 TBOX_5C4_SSecOC_MAC_Byte1 "null";
BA_ "sigConfig" SG_ 1476 TBOX_5C4_SSecOC_MAC_Byte1 "null";
BA_ "sigSecLevel" SG_ 1476 TBOX_5C4_SSecOC_MAC_Byte2 "null";
BA_ "sigExplanation" SG_ 1476 TBOX_5C4_SSecOC_MAC_Byte2 "null";
BA_ "sigConfig" SG_ 1476 TBOX_5C4_SSecOC_MAC_Byte2 "null";
BA_ "GenSigStartValue" SG_ 1583 TBOX_ZoneT 48;
BA_ "sigSecLevel" SG_ 1583 TBOX_CrtTi_Day "null";
BA_ "sigExplanation" SG_ 1583 TBOX_CrtTi_Day "null";
BA_ "sigConfig" SG_ 1583 TBOX_CrtTi_Day "null";
BA_ "sigSecLevel" SG_ 1583 TBOX_CrtTi_Hr "null";
BA_ "sigExplanation" SG_ 1583 TBOX_CrtTi_Hr "null";
BA_ "sigConfig" SG_ 1583 TBOX_CrtTi_Hr "null";
BA_ "sigSecLevel" SG_ 1583 TBOX_CrtTi_Mins "null";
BA_ "sigExplanation" SG_ 1583 TBOX_CrtTi_Mins "null";
BA_ "sigConfig" SG_ 1583 TBOX_CrtTi_Mins "null";
BA_ "sigSecLevel" SG_ 1583 TBOX_CrtTi_Yr "null";
BA_ "sigExplanation" SG_ 1583 TBOX_CrtTi_Yr "null";
BA_ "sigConfig" SG_ 1583 TBOX_CrtTi_Yr "null";
BA_ "sigSecLevel" SG_ 1583 TBOX_CrtTi_Mth "null";
BA_ "sigExplanation" SG_ 1583 TBOX_CrtTi_Mth "null";
BA_ "sigConfig" SG_ 1583 TBOX_CrtTi_Mth "null";
BA_ "sigSecLevel" SG_ 1583 TBOX_CrtTi_Sec "null";
BA_ "sigExplanation" SG_ 1583 TBOX_CrtTi_Sec "null";
BA_ "sigConfig" SG_ 1583 TBOX_CrtTi_Sec "null";
BA_ "sigSecLevel" SG_ 1661 FCM_SwVersS "null";
BA_ "sigExplanation" SG_ 1661 FCM_SwVersS "null";
BA_ "sigConfig" SG_ 1661 FCM_SwVersS "null";
BA_ "sigSecLevel" SG_ 1661 FCM_PartVers "null";
BA_ "sigExplanation" SG_ 1661 FCM_PartVers "null";
BA_ "sigConfig" SG_ 1661 FCM_PartVers "null";
BA_ "sigSecLevel" SG_ 1661 FCM_HwVers "null";
BA_ "sigExplanation" SG_ 1661 FCM_HwVers "null";
BA_ "sigConfig" SG_ 1661 FCM_HwVers "null";
BA_ "sigSecLevel" SG_ 1661 FCM_SwVersM "null";
BA_ "sigExplanation" SG_ 1661 FCM_SwVersM "null";
BA_ "sigConfig" SG_ 1661 FCM_SwVersM "null";
BA_ "sigSecLevel" SG_ 1765 VCU_VINCod1 "null";
BA_ "sigExplanation" SG_ 1765 VCU_VINCod1 "null";
BA_ "sigConfig" SG_ 1765 VCU_VINCod1 "null";
BA_ "sigSecLevel" SG_ 1766 VCU_VINCod2 "null";
BA_ "sigExplanation" SG_ 1766 VCU_VINCod2 "null";
BA_ "sigConfig" SG_ 1766 VCU_VINCod2 "null";
BA_ "sigSecLevel" SG_ 1767 VCU_VINCod3 "null";
BA_ "sigExplanation" SG_ 1767 VCU_VINCod3 "null";
BA_ "sigConfig" SG_ 1767 VCU_VINCod3 "null";
BA_ "GenSigSendType" SG_ 1920 FCM_Byte2_Req 1;
BA_ "GenSigSendType" SG_ 1920 FCM_Byte3_Req 1;
BA_ "GenSigSendType" SG_ 1920 FCM_Byte4_Req 1;
BA_ "GenSigSendType" SG_ 1920 FCM_Byte5_Req 1;
BA_ "GenSigSendType" SG_ 1920 FCM_Byte6_Req 1;
BA_ "GenSigSendType" SG_ 1920 FCM_Byte7_Req 1;
BA_ "GenSigSendType" SG_ 1920 FCM_Byte8_Req 1;
BA_ "GenSigSendType" SG_ 1920 FCM_TPCI_Req 1;
BA_ "GenSigSendType" SG_ 1928 FCM_Byte2_Resp 1;
BA_ "GenSigSendType" SG_ 1928 FCM_Byte3_Resp 1;
BA_ "GenSigSendType" SG_ 1928 FCM_Byte4_Resp 1;
BA_ "GenSigSendType" SG_ 1928 FCM_Byte5_Resp 1;
BA_ "GenSigSendType" SG_ 1928 FCM_Byte6_Resp 1;
BA_ "GenSigSendType" SG_ 1928 FCM_Byte7_Resp 1;
BA_ "GenSigSendType" SG_ 1928 FCM_Byte8_Resp 1;
BA_ "GenSigSendType" SG_ 1928 FCM_TPCI_Resp 1;
BA_ "GenSigSendType" SG_ 2015 Tester_Byte2_Req 1;
BA_ "GenSigSendType" SG_ 2015 Tester_Byte3_Req 1;
BA_ "GenSigSendType" SG_ 2015 Tester_Byte4_Req 1;
BA_ "GenSigSendType" SG_ 2015 Tester_Byte5_Req 1;
BA_ "GenSigSendType" SG_ 2015 Tester_Byte6_Req 1;
BA_ "GenSigSendType" SG_ 2015 Tester_Byte7_Req 1;
BA_ "GenSigSendType" SG_ 2015 Tester_Byte8_Req 1;
BA_ "GenSigSendType" SG_ 2015 Tester_TPCI_Req 1;
VAL_ 1065 PKC_CtrlBitVector_Bit0_RMR 0 "Repeat_Message_State_not_requested" 1 "Repeat_Message_State_requested" ;
VAL_ 1065 PKC_CtrlBitVector_Bit3_NMCoord 0 "Start_of_synchronized_shutdown_is_not_requested_by_main_coordinator" 1 "Start_of_synchronized_shutdown_is_requested_by_main_coordinator" ;
VAL_ 1065 PKC_CtrlBitVector_Bit4_ActWake 0 "Node_has_not_woken_up_the_network_(passive_wakeup)" 1 "Node_has_woken_up_the_network_(active_Wakeup)" ;
VAL_ 1065 PKC_CtrlBitVector_Bit6_PNI 0 "NM_PDU_contains_no_Partial_Network_request_information" 1 "NM_PDU_contains_Partial_Network_request_information" ;
VAL_ 1065 PKC_UsrData0 0 "User_data_for_current_vehicle_without_partial_networking" 1 "User_data_for_current_vehicle_with_partial_networking" 255 "User_data_not_used" ;
VAL_ 1065 PKC_UsrData1_Bit0_IGN_WAKEUP 0 "inactive" 1 "active" ;
VAL_ 1065 PKC_UsrData1_Bit1_RESET_WAKEUP 0 "inactive" 1 "active" ;
VAL_ 1065 PKC_UsrData1_Bit2_NETWORK_WAKEUP 0 "inactive" 1 "active" ;
VAL_ 1065 PKC_UsrData1_Bit3_ECUSPEC_WAKEUP 0 "inactive" 1 "active" ;
VAL_ 1065 PKC_UsrData1_Bit4_NETWORK_AWAKE 0 "inactive" 1 "active" ;
VAL_ 1065 PKC_UsrData1_Bit5_IGNITION_AWAKE 0 "inactive" 1 "active" ;
VAL_ 1065 PKC_UsrData1_Bit6_DIAGN_AWAKE 0 "inactive" 1 "active" ;
VAL_ 1065 PKC_UsrData1_Bit7_ECUSPEC_AWAKE 0 "inactive" 1 "active" ;
VAL_ 1069 ADAS_CtrlBitVector_Bit0_RMR 0 "Repeat_Message_State_not_requested" 1 "Repeat_Message_State_requested" ;
VAL_ 1069 ADAS_CtrlBitVector_Bit3_NMCoord 0 "Start_of_synchronized_shutdown_is_not_requested_by_main_coordinator" 1 "Start_of_synchronized_shutdown_is_requested_by_main_coordinator" ;
VAL_ 1069 ADAS_CtrlBitVector_Bit4_ActWake 0 "Node_has_not_woken_up_the_network(passive_wakeup)" 1 "Node_has_woken_up_the_network(active_Wakeup)" ;
VAL_ 1069 ADAS_CtrlBitVector_Bit6_PNI 0 "NM_PDU_contains_no_Partial_Network_request_information" 1 "NM_PDU_contains_Partial_Network_request_information" ;
VAL_ 1069 ADAS_UsrData0 0 "User_data_for_current_vehicle_without_partial_networking" 1 "User_data_for_current_vehicle_with_partial_networking" 2 "User_data_not_used" 3 "User_data_not_used" 4 "User_data_not_used" 5 "User_data_not_used" 6 "User_data_not_used" 7 "User_data_not_used" 8 "User_data_not_used" 9 "User_data_not_used" 10 "User_data_not_used" 11 "User_data_not_used" 12 "User_data_not_used" 13 "User_data_not_used" 14 "User_data_not_used" 15 "User_data_not_used" 16 "User_data_not_used" 17 "User_data_not_used" 18 "User_data_not_used" 19 "User_data_not_used" 20 "User_data_not_used" 21 "User_data_not_used" 22 "User_data_not_used" 23 "User_data_not_used" 24 "User_data_not_used" 25 "User_data_not_used" 26 "User_data_not_used" 27 "User_data_not_used" 28 "User_data_not_used" 29 "User_data_not_used" 30 "User_data_not_used" 31 "User_data_not_used" 32 "User_data_not_used" 33 "User_data_not_used" 34 "User_data_not_used" 35 "User_data_not_used" 36 "User_data_not_used" 37 "User_data_not_used" 38 "User_data_not_used" 39 "User_data_not_used" 40 "User_data_not_used" 41 "User_data_not_used" 42 "User_data_not_used" 43 "User_data_not_used" 44 "User_data_not_used" 45 "User_data_not_used" 46 "User_data_not_used" 47 "User_data_not_used" 48 "User_data_not_used" 49 "User_data_not_used" 50 "User_data_not_used" 51 "User_data_not_used" 52 "User_data_not_used" 53 "User_data_not_used" 54 "User_data_not_used" 55 "User_data_not_used" 56 "User_data_not_used" 57 "User_data_not_used" 58 "User_data_not_used" 59 "User_data_not_used" 60 "User_data_not_used" 61 "User_data_not_used" 62 "User_data_not_used" 63 "User_data_not_used" 64 "User_data_not_used" 65 "User_data_not_used" 66 "User_data_not_used" 67 "User_data_not_used" 68 "User_data_not_used" 69 "User_data_not_used" 70 "User_data_not_used" 71 "User_data_not_used" 72 "User_data_not_used" 73 "User_data_not_used" 74 "User_data_not_used" 75 "User_data_not_used" 76 "User_data_not_used" 77 "User_data_not_used" 78 "User_data_not_used" 79 "User_data_not_used" 80 "User_data_not_used" 81 "User_data_not_used" 82 "User_data_not_used" 83 "User_data_not_used" 84 "User_data_not_used" 85 "User_data_not_used" 86 "User_data_not_used" 87 "User_data_not_used" 88 "User_data_not_used" 89 "User_data_not_used" 90 "User_data_not_used" 91 "User_data_not_used" 92 "User_data_not_used" 93 "User_data_not_used" 94 "User_data_not_used" 95 "User_data_not_used" 96 "User_data_not_used" 97 "User_data_not_used" 98 "User_data_not_used" 99 "User_data_not_used" 100 "User_data_not_used" 101 "User_data_not_used" 102 "User_data_not_used" 103 "User_data_not_used" 104 "User_data_not_used" 105 "User_data_not_used" 106 "User_data_not_used" 107 "User_data_not_used" 108 "User_data_not_used" 109 "User_data_not_used" 110 "User_data_not_used" 111 "User_data_not_used" 112 "User_data_not_used" 113 "User_data_not_used" 114 "User_data_not_used" 115 "User_data_not_used" 116 "User_data_not_used" 117 "User_data_not_used" 118 "User_data_not_used" 119 "User_data_not_used" 120 "User_data_not_used" 121 "User_data_not_used" 122 "User_data_not_used" 123 "User_data_not_used" 124 "User_data_not_used" 125 "User_data_not_used" 126 "User_data_not_used" 127 "User_data_not_used" 128 "User_data_not_used" 129 "User_data_not_used" 130 "User_data_not_used" 131 "User_data_not_used" 132 "User_data_not_used" 133 "User_data_not_used" 134 "User_data_not_used" 135 "User_data_not_used" 136 "User_data_not_used" 137 "User_data_not_used" 138 "User_data_not_used" 139 "User_data_not_used" 140 "User_data_not_used" 141 "User_data_not_used" 142 "User_data_not_used" 143 "User_data_not_used" 144 "User_data_not_used" 145 "User_data_not_used" 146 "User_data_not_used" 147 "User_data_not_used" 148 "User_data_not_used" 149 "User_data_not_used" 150 "User_data_not_used" 151 "User_data_not_used" 152 "User_data_not_used" 153 "User_data_not_used" 154 "User_data_not_used" 155 "User_data_not_used" 156 "User_data_not_used" 157 "User_data_not_used" 158 "User_data_not_used" 159 "User_data_not_used" 160 "User_data_not_used" 161 "User_data_not_used" 162 "User_data_not_used" 163 "User_data_not_used" 164 "User_data_not_used" 165 "User_data_not_used" 166 "User_data_not_used" 167 "User_data_not_used" 168 "User_data_not_used" 169 "User_data_not_used" 170 "User_data_not_used" 171 "User_data_not_used" 172 "User_data_not_used" 173 "User_data_not_used" 174 "User_data_not_used" 175 "User_data_not_used" 176 "User_data_not_used" 177 "User_data_not_used" 178 "User_data_not_used" 179 "User_data_not_used" 180 "User_data_not_used" 181 "User_data_not_used" 182 "User_data_not_used" 183 "User_data_not_used" 184 "User_data_not_used" 185 "User_data_not_used" 186 "User_data_not_used" 187 "User_data_not_used" 188 "User_data_not_used" 189 "User_data_not_used" 190 "User_data_not_used" 191 "User_data_not_used" 192 "User_data_not_used" 193 "User_data_not_used" 194 "User_data_not_used" 195 "User_data_not_used" 196 "User_data_not_used" 197 "User_data_not_used" 198 "User_data_not_used" 199 "User_data_not_used" 200 "User_data_not_used" 201 "User_data_not_used" 202 "User_data_not_used" 203 "User_data_not_used" 204 "User_data_not_used" 205 "User_data_not_used" 206 "User_data_not_used" 207 "User_data_not_used" 208 "User_data_not_used" 209 "User_data_not_used" 210 "User_data_not_used" 211 "User_data_not_used" 212 "User_data_not_used" 213 "User_data_not_used" 214 "User_data_not_used" 215 "User_data_not_used" 216 "User_data_not_used" 217 "User_data_not_used" 218 "User_data_not_used" 219 "User_data_not_used" 220 "User_data_not_used" 221 "User_data_not_used" 222 "User_data_not_used" 223 "User_data_not_used" 224 "User_data_not_used" 225 "User_data_not_used" 226 "User_data_not_used" 227 "User_data_not_used" 228 "User_data_not_used" 229 "User_data_not_used" 230 "User_data_not_used" 231 "User_data_not_used" 232 "User_data_not_used" 233 "User_data_not_used" 234 "User_data_not_used" 235 "User_data_not_used" 236 "User_data_not_used" 237 "User_data_not_used" 238 "User_data_not_used" 239 "User_data_not_used" 240 "User_data_not_used" 241 "User_data_not_used" 242 "User_data_not_used" 243 "User_data_not_used" 244 "User_data_not_used" 245 "User_data_not_used" 246 "User_data_not_used" 247 "User_data_not_used" 248 "User_data_not_used" 249 "User_data_not_used" 250 "User_data_not_used" 251 "User_data_not_used" 252 "User_data_not_used" 253 "User_data_not_used" 254 "User_data_not_used" 255 "User_data_not_used" ;
VAL_ 1069 ADAS_UsrData1_Bit0_IGN_WAKEUP 0 "inactive" 1 "active" ;
VAL_ 1069 ADAS_UsrData1_Bit1_RESET_WAKEUP 0 "inactive" 1 "active" ;
VAL_ 1069 ADAS_UsrData1_Bit2_NET_WKUP 0 "inactive" 1 "active" ;
VAL_ 1069 ADAS_UsrData1_Bit3_ECUSPEC_WKUP 0 "inactive" 1 "active" ;
VAL_ 1069 ADAS_UsrData1_Bit4_NETWORK_AWAKE 0 "inactive" 1 "active" ;
VAL_ 1069 ADAS_UsrData1_Bit5_IGN_AWAKE 0 "inactive" 1 "active" ;
VAL_ 1069 ADAS_UsrData1_Bit6_DIAGN_AWAKE 0 "inactive" 1 "active" ;
VAL_ 1069 ADAS_UsrData1_Bit7_ECUSPEC_AWAKE 0 "inactive" 1 "active" ;
VAL_ 1070 FCM_CtrlBitVector_Bit0_RMR 0 "Repeat_Message_State_not_requested" 1 "Repeat_Message_State_requested" ;
VAL_ 1070 FCM_CtrlBitVector_Bit3_NMCoord 0 "Start_of_synchronized_shutdown_is_not_requested_by_main_coordinator" 1 "Start_of_synchronized_shutdown_is_requested_by_main_coordinator" ;
VAL_ 1070 FCM_CtrlBitVector_Bit4_ActWake 0 "Node_has_not_woken_up_the_network_(passive_wakeup)" 1 "Node_has_woken_up_the_network_(active_Wakeup)" ;
VAL_ 1070 FCM_CtrlBitVector_Bit6_PNI 0 "NM_PDU_contains_no_Partial_Network_request_information" 1 "NM_PDU_contains_Partial_Network_request_information" ;
VAL_ 1070 FCM_UsrData0 0 "User_data_for_current_vehicle_without_partial_networking" 1 "User_data_for_current_vehicle_with_partial_networking" 2 "User_data_not_used" 3 "User_data_not_used" 4 "User_data_not_used" 5 "User_data_not_used" 6 "User_data_not_used" 7 "User_data_not_used" 8 "User_data_not_used" 9 "User_data_not_used" 10 "User_data_not_used" 11 "User_data_not_used" 12 "User_data_not_used" 13 "User_data_not_used" 14 "User_data_not_used" 15 "User_data_not_used" 16 "User_data_not_used" 17 "User_data_not_used" 18 "User_data_not_used" 19 "User_data_not_used" 20 "User_data_not_used" 21 "User_data_not_used" 22 "User_data_not_used" 23 "User_data_not_used" 24 "User_data_not_used" 25 "User_data_not_used" 26 "User_data_not_used" 27 "User_data_not_used" 28 "User_data_not_used" 29 "User_data_not_used" 30 "User_data_not_used" 31 "User_data_not_used" 32 "User_data_not_used" 33 "User_data_not_used" 34 "User_data_not_used" 35 "User_data_not_used" 36 "User_data_not_used" 37 "User_data_not_used" 38 "User_data_not_used" 39 "User_data_not_used" 40 "User_data_not_used" 41 "User_data_not_used" 42 "User_data_not_used" 43 "User_data_not_used" 44 "User_data_not_used" 45 "User_data_not_used" 46 "User_data_not_used" 47 "User_data_not_used" 48 "User_data_not_used" 49 "User_data_not_used" 50 "User_data_not_used" 51 "User_data_not_used" 52 "User_data_not_used" 53 "User_data_not_used" 54 "User_data_not_used" 55 "User_data_not_used" 56 "User_data_not_used" 57 "User_data_not_used" 58 "User_data_not_used" 59 "User_data_not_used" 60 "User_data_not_used" 61 "User_data_not_used" 62 "User_data_not_used" 63 "User_data_not_used" 64 "User_data_not_used" 65 "User_data_not_used" 66 "User_data_not_used" 67 "User_data_not_used" 68 "User_data_not_used" 69 "User_data_not_used" 70 "User_data_not_used" 71 "User_data_not_used" 72 "User_data_not_used" 73 "User_data_not_used" 74 "User_data_not_used" 75 "User_data_not_used" 76 "User_data_not_used" 77 "User_data_not_used" 78 "User_data_not_used" 79 "User_data_not_used" 80 "User_data_not_used" 81 "User_data_not_used" 82 "User_data_not_used" 83 "User_data_not_used" 84 "User_data_not_used" 85 "User_data_not_used" 86 "User_data_not_used" 87 "User_data_not_used" 88 "User_data_not_used" 89 "User_data_not_used" 90 "User_data_not_used" 91 "User_data_not_used" 92 "User_data_not_used" 93 "User_data_not_used" 94 "User_data_not_used" 95 "User_data_not_used" 96 "User_data_not_used" 97 "User_data_not_used" 98 "User_data_not_used" 99 "User_data_not_used" 100 "User_data_not_used" 101 "User_data_not_used" 102 "User_data_not_used" 103 "User_data_not_used" 104 "User_data_not_used" 105 "User_data_not_used" 106 "User_data_not_used" 107 "User_data_not_used" 108 "User_data_not_used" 109 "User_data_not_used" 110 "User_data_not_used" 111 "User_data_not_used" 112 "User_data_not_used" 113 "User_data_not_used" 114 "User_data_not_used" 115 "User_data_not_used" 116 "User_data_not_used" 117 "User_data_not_used" 118 "User_data_not_used" 119 "User_data_not_used" 120 "User_data_not_used" 121 "User_data_not_used" 122 "User_data_not_used" 123 "User_data_not_used" 124 "User_data_not_used" 125 "User_data_not_used" 126 "User_data_not_used" 127 "User_data_not_used" 128 "User_data_not_used" 129 "User_data_not_used" 130 "User_data_not_used" 131 "User_data_not_used" 132 "User_data_not_used" 133 "User_data_not_used" 134 "User_data_not_used" 135 "User_data_not_used" 136 "User_data_not_used" 137 "User_data_not_used" 138 "User_data_not_used" 139 "User_data_not_used" 140 "User_data_not_used" 141 "User_data_not_used" 142 "User_data_not_used" 143 "User_data_not_used" 144 "User_data_not_used" 145 "User_data_not_used" 146 "User_data_not_used" 147 "User_data_not_used" 148 "User_data_not_used" 149 "User_data_not_used" 150 "User_data_not_used" 151 "User_data_not_used" 152 "User_data_not_used" 153 "User_data_not_used" 154 "User_data_not_used" 155 "User_data_not_used" 156 "User_data_not_used" 157 "User_data_not_used" 158 "User_data_not_used" 159 "User_data_not_used" 160 "User_data_not_used" 161 "User_data_not_used" 162 "User_data_not_used" 163 "User_data_not_used" 164 "User_data_not_used" 165 "User_data_not_used" 166 "User_data_not_used" 167 "User_data_not_used" 168 "User_data_not_used" 169 "User_data_not_used" 170 "User_data_not_used" 171 "User_data_not_used" 172 "User_data_not_used" 173 "User_data_not_used" 174 "User_data_not_used" 175 "User_data_not_used" 176 "User_data_not_used" 177 "User_data_not_used" 178 "User_data_not_used" 179 "User_data_not_used" 180 "User_data_not_used" 181 "User_data_not_used" 182 "User_data_not_used" 183 "User_data_not_used" 184 "User_data_not_used" 185 "User_data_not_used" 186 "User_data_not_used" 187 "User_data_not_used" 188 "User_data_not_used" 189 "User_data_not_used" 190 "User_data_not_used" 191 "User_data_not_used" 192 "User_data_not_used" 193 "User_data_not_used" 194 "User_data_not_used" 195 "User_data_not_used" 196 "User_data_not_used" 197 "User_data_not_used" 198 "User_data_not_used" 199 "User_data_not_used" 200 "User_data_not_used" 201 "User_data_not_used" 202 "User_data_not_used" 203 "User_data_not_used" 204 "User_data_not_used" 205 "User_data_not_used" 206 "User_data_not_used" 207 "User_data_not_used" 208 "User_data_not_used" 209 "User_data_not_used" 210 "User_data_not_used" 211 "User_data_not_used" 212 "User_data_not_used" 213 "User_data_not_used" 214 "User_data_not_used" 215 "User_data_not_used" 216 "User_data_not_used" 217 "User_data_not_used" 218 "User_data_not_used" 219 "User_data_not_used" 220 "User_data_not_used" 221 "User_data_not_used" 222 "User_data_not_used" 223 "User_data_not_used" 224 "User_data_not_used" 225 "User_data_not_used" 226 "User_data_not_used" 227 "User_data_not_used" 228 "User_data_not_used" 229 "User_data_not_used" 230 "User_data_not_used" 231 "User_data_not_used" 232 "User_data_not_used" 233 "User_data_not_used" 234 "User_data_not_used" 235 "User_data_not_used" 236 "User_data_not_used" 237 "User_data_not_used" 238 "User_data_not_used" 239 "User_data_not_used" 240 "User_data_not_used" 241 "User_data_not_used" 242 "User_data_not_used" 243 "User_data_not_used" 244 "User_data_not_used" 245 "User_data_not_used" 246 "User_data_not_used" 247 "User_data_not_used" 248 "User_data_not_used" 249 "User_data_not_used" 250 "User_data_not_used" 251 "User_data_not_used" 252 "User_data_not_used" 253 "User_data_not_used" 254 "User_data_not_used" 255 "User_data_not_used" ;
VAL_ 1070 FCM_UsrData1_Bit0_IGN_WAKEUP 0 "inactive" 1 "active" ;
VAL_ 1070 FCM_UsrData1_Bit1_RESET_WAKEUP 0 "inactive" 1 "active" ;
VAL_ 1070 FCM_UsrData1_Bit2_NETWORK_WAKEUP 0 "inactive" 1 "active" ;
VAL_ 1070 FCM_UsrData1_Bit3_ECUSPEC_WAKEUP 0 "inactive" 1 "active" ;
VAL_ 1070 FCM_UsrData1_Bit4_NETWORK_AWAKE 0 "inactive" 1 "active" ;
VAL_ 1070 FCM_UsrData1_Bit5_IGNITION_AWAKE 0 "inactive" 1 "active" ;
VAL_ 1070 FCM_UsrData1_Bit6_DIAGN_AWAKE 0 "inactive" 1 "active" ;
VAL_ 1070 FCM_UsrData1_Bit7_ECUSPEC_AWAKE 0 "inactive" 1 "active" ;
VAL_ 1086 GW_CtrlBitVector_Bit0_RMR 0 "Repeat_Message_State_not_requested" 1 "Repeat_Message_State_requested" ;
VAL_ 1086 GW_CtrlBitVector_Bit3_NMCoord 0 "Start_of_synchronized_shutdown_is_not_requested_by_main_coordinator" 1 "Start_of_synchronized_shutdown_is_requested_by_main_coordinator" ;
VAL_ 1086 GW_CtrlBitVector_Bit4_ActWake 0 "Node_has_not_woken_up_the_network_(passive_wakeup)" 1 "Node_has_woken_up_the_network_(active_Wakeup)" ;
VAL_ 1086 GW_CtrlBitVector_Bit6_PNI 0 "NM_PDU_contains_no_Partial_Network_request_information" 1 "NM_PDU_contains_Partial_Network_request_information" ;
VAL_ 1086 GW_UsrData0 0 "User_data_for_current_vehicle_without_partial_networking" 1 "User_data_for_current_vehicle_with_partial_networking" 2 "User_data_not_used" 3 "User_data_not_used" 4 "User_data_not_used" 5 "User_data_not_used" 6 "User_data_not_used" 7 "User_data_not_used" 8 "User_data_not_used" 9 "User_data_not_used" 10 "User_data_not_used" 11 "User_data_not_used" 12 "User_data_not_used" 13 "User_data_not_used" 14 "User_data_not_used" 15 "User_data_not_used" 16 "User_data_not_used" 17 "User_data_not_used" 18 "User_data_not_used" 19 "User_data_not_used" 20 "User_data_not_used" 21 "User_data_not_used" 22 "User_data_not_used" 23 "User_data_not_used" 24 "User_data_not_used" 25 "User_data_not_used" 26 "User_data_not_used" 27 "User_data_not_used" 28 "User_data_not_used" 29 "User_data_not_used" 30 "User_data_not_used" 31 "User_data_not_used" 32 "User_data_not_used" 33 "User_data_not_used" 34 "User_data_not_used" 35 "User_data_not_used" 36 "User_data_not_used" 37 "User_data_not_used" 38 "User_data_not_used" 39 "User_data_not_used" 40 "User_data_not_used" 41 "User_data_not_used" 42 "User_data_not_used" 43 "User_data_not_used" 44 "User_data_not_used" 45 "User_data_not_used" 46 "User_data_not_used" 47 "User_data_not_used" 48 "User_data_not_used" 49 "User_data_not_used" 50 "User_data_not_used" 51 "User_data_not_used" 52 "User_data_not_used" 53 "User_data_not_used" 54 "User_data_not_used" 55 "User_data_not_used" 56 "User_data_not_used" 57 "User_data_not_used" 58 "User_data_not_used" 59 "User_data_not_used" 60 "User_data_not_used" 61 "User_data_not_used" 62 "User_data_not_used" 63 "User_data_not_used" 64 "User_data_not_used" 65 "User_data_not_used" 66 "User_data_not_used" 67 "User_data_not_used" 68 "User_data_not_used" 69 "User_data_not_used" 70 "User_data_not_used" 71 "User_data_not_used" 72 "User_data_not_used" 73 "User_data_not_used" 74 "User_data_not_used" 75 "User_data_not_used" 76 "User_data_not_used" 77 "User_data_not_used" 78 "User_data_not_used" 79 "User_data_not_used" 80 "User_data_not_used" 81 "User_data_not_used" 82 "User_data_not_used" 83 "User_data_not_used" 84 "User_data_not_used" 85 "User_data_not_used" 86 "User_data_not_used" 87 "User_data_not_used" 88 "User_data_not_used" 89 "User_data_not_used" 90 "User_data_not_used" 91 "User_data_not_used" 92 "User_data_not_used" 93 "User_data_not_used" 94 "User_data_not_used" 95 "User_data_not_used" 96 "User_data_not_used" 97 "User_data_not_used" 98 "User_data_not_used" 99 "User_data_not_used" 100 "User_data_not_used" 101 "User_data_not_used" 102 "User_data_not_used" 103 "User_data_not_used" 104 "User_data_not_used" 105 "User_data_not_used" 106 "User_data_not_used" 107 "User_data_not_used" 108 "User_data_not_used" 109 "User_data_not_used" 110 "User_data_not_used" 111 "User_data_not_used" 112 "User_data_not_used" 113 "User_data_not_used" 114 "User_data_not_used" 115 "User_data_not_used" 116 "User_data_not_used" 117 "User_data_not_used" 118 "User_data_not_used" 119 "User_data_not_used" 120 "User_data_not_used" 121 "User_data_not_used" 122 "User_data_not_used" 123 "User_data_not_used" 124 "User_data_not_used" 125 "User_data_not_used" 126 "User_data_not_used" 127 "User_data_not_used" 128 "User_data_not_used" 129 "User_data_not_used" 130 "User_data_not_used" 131 "User_data_not_used" 132 "User_data_not_used" 133 "User_data_not_used" 134 "User_data_not_used" 135 "User_data_not_used" 136 "User_data_not_used" 137 "User_data_not_used" 138 "User_data_not_used" 139 "User_data_not_used" 140 "User_data_not_used" 141 "User_data_not_used" 142 "User_data_not_used" 143 "User_data_not_used" 144 "User_data_not_used" 145 "User_data_not_used" 146 "User_data_not_used" 147 "User_data_not_used" 148 "User_data_not_used" 149 "User_data_not_used" 150 "User_data_not_used" 151 "User_data_not_used" 152 "User_data_not_used" 153 "User_data_not_used" 154 "User_data_not_used" 155 "User_data_not_used" 156 "User_data_not_used" 157 "User_data_not_used" 158 "User_data_not_used" 159 "User_data_not_used" 160 "User_data_not_used" 161 "User_data_not_used" 162 "User_data_not_used" 163 "User_data_not_used" 164 "User_data_not_used" 165 "User_data_not_used" 166 "User_data_not_used" 167 "User_data_not_used" 168 "User_data_not_used" 169 "User_data_not_used" 170 "User_data_not_used" 171 "User_data_not_used" 172 "User_data_not_used" 173 "User_data_not_used" 174 "User_data_not_used" 175 "User_data_not_used" 176 "User_data_not_used" 177 "User_data_not_used" 178 "User_data_not_used" 179 "User_data_not_used" 180 "User_data_not_used" 181 "User_data_not_used" 182 "User_data_not_used" 183 "User_data_not_used" 184 "User_data_not_used" 185 "User_data_not_used" 186 "User_data_not_used" 187 "User_data_not_used" 188 "User_data_not_used" 189 "User_data_not_used" 190 "User_data_not_used" 191 "User_data_not_used" 192 "User_data_not_used" 193 "User_data_not_used" 194 "User_data_not_used" 195 "User_data_not_used" 196 "User_data_not_used" 197 "User_data_not_used" 198 "User_data_not_used" 199 "User_data_not_used" 200 "User_data_not_used" 201 "User_data_not_used" 202 "User_data_not_used" 203 "User_data_not_used" 204 "User_data_not_used" 205 "User_data_not_used" 206 "User_data_not_used" 207 "User_data_not_used" 208 "User_data_not_used" 209 "User_data_not_used" 210 "User_data_not_used" 211 "User_data_not_used" 212 "User_data_not_used" 213 "User_data_not_used" 214 "User_data_not_used" 215 "User_data_not_used" 216 "User_data_not_used" 217 "User_data_not_used" 218 "User_data_not_used" 219 "User_data_not_used" 220 "User_data_not_used" 221 "User_data_not_used" 222 "User_data_not_used" 223 "User_data_not_used" 224 "User_data_not_used" 225 "User_data_not_used" 226 "User_data_not_used" 227 "User_data_not_used" 228 "User_data_not_used" 229 "User_data_not_used" 230 "User_data_not_used" 231 "User_data_not_used" 232 "User_data_not_used" 233 "User_data_not_used" 234 "User_data_not_used" 235 "User_data_not_used" 236 "User_data_not_used" 237 "User_data_not_used" 238 "User_data_not_used" 239 "User_data_not_used" 240 "User_data_not_used" 241 "User_data_not_used" 242 "User_data_not_used" 243 "User_data_not_used" 244 "User_data_not_used" 245 "User_data_not_used" 246 "User_data_not_used" 247 "User_data_not_used" 248 "User_data_not_used" 249 "User_data_not_used" 250 "User_data_not_used" 251 "User_data_not_used" 252 "User_data_not_used" 253 "User_data_not_used" 254 "User_data_not_used" 255 "User_data_not_used" ;
VAL_ 1086 GW_UsrData1_Bit0_IGN_WAKEUP 0 "inactive" 1 "active" ;
VAL_ 1086 GW_UsrData1_Bit1_RESET_WAKEUP 0 "inactive" 1 "active" ;
VAL_ 1086 GW_UsrData1_Bit2_NETWORK_WAKEUP 0 "inactive" 1 "active" ;
VAL_ 1086 GW_UsrData1_Bit3_ECUSPEC_WAKEUP 0 "inactive" 1 "active" ;
VAL_ 1086 GW_UsrData1_Bit4_NETWORK_AWAKE 0 "inactive" 1 "active" ;
VAL_ 1086 GW_UsrData1_Bit5_IGNITION_AWAKE 0 "inactive" 1 "active" ;
VAL_ 1086 GW_UsrData1_Bit6_DIAGN_AWAKE 0 "inactive" 1 "active" ;
VAL_ 1086 GW_UsrData1_Bit7_ECUSPEC_AWAKE 0 "inactive" 1 "active" ;
VAL_ 1159 FCM_ComLostFlt_ESP 0 "Normal" 1 "Abnormal" ;
VAL_ 1159 FCM_ComLostFlt_iBooster 0 "Normal" 1 "Abnormal" ;
VAL_ 1159 FCM_ComLostFlt_EPS 0 "Normal" 1 "Abnormal" ;
VAL_ 1159 FCM_ComLostFlt_YRS 0 "Normal" 1 "Abnormal" ;
VAL_ 1159 FCM_ComLostFlt_BCM 0 "Normal" 1 "Abnormal" ;
VAL_ 1159 FCM_ComLostFlt_ECC 0 "Normal" 1 "Abnormal" ;
VAL_ 1159 FCM_ComLostFlt_TBOX 0 "Normal" 1 "Abnormal" ;
VAL_ 1159 FCM_ComLostFlt_CIM 0 "Normal" 1 "Abnormal" ;
VAL_ 1159 FCM_ComLostFlt_ICC 0 "Normal" 1 "Abnormal" ;
VAL_ 1159 FCM_ComLostFlt_MRR 0 "Normal" 1 "Abnormal" ;
VAL_ 1159 FCM_ComLostFlt_PEPS 0 "Normal" 1 "Abnormal" ;
VAL_ 1159 FCM_ComLostFlt_ADAS 0 "Normal" 1 "Abnormal" ;
VAL_ 1159 FCM_ComE2EFlt 0 "Normal" 1 "Abnormal" ;
VAL_ 1159 FCM_ChkInvldSig_ESP 0 "Normal" 1 "Abnormal" ;
VAL_ 1159 FCM_ChkInvldSig_iBooster 0 "Normal" 1 "Abnormal" ;
VAL_ 1159 FCM_ChkInvldSig_EPS 0 "Normal" 1 "Abnormal" ;
VAL_ 1159 FCM_ChkInvldSig_YRS 0 "Normal" 1 "Abnormal" ;
VAL_ 1159 FCM_ChkInvldSig_CIM 0 "Normal" 1 "Abnormal" ;
VAL_ 1159 FCM_ChkInvldSig_ECC 0 "Normal" 1 "Abnormal" ;
VAL_ 1159 FCM_ChkInvldSig_PEPS 0 "Normal" 1 "Abnormal" ;
VAL_ 1159 FCM_ChkInvldSig_ICC 0 "Normal" 1 "Abnormal" ;
VAL_ 1159 FCM_ChkPrivateCANBusOff 0 "Normal" 1 "Abnormal" ;
VAL_ 1159 FCM_ChkPublicCANBusOff 0 "Normal" 1 "Abnormal" ;
VAL_ 1159 FCM_BattVoltBelowThd 0 "Normal" 1 "Abnormal" ;
VAL_ 1159 FCM_BattVoltOverThd 0 "Normal" 1 "Abnormal" ;
VAL_ 1159 FCM_CamBli 0 "Normal" 1 "Abnormal" ;
VAL_ 1159 FCM_ECUTmpHiTProtn 0 "Normal" 1 "Abnormal" ;
VAL_ 1159 FCM_IntCircOutpVoltBelowThd 0 "Normal" 1 "Abnormal" ;
VAL_ 1159 FCM_IntCircOutpVoltOverThd 0 "Normal" 1 "Abnormal" ;
VAL_ 1159 FCM_IntCircPrmntFlt 0 "Normal" 1 "Abnormal" ;
VAL_ 1159 FCM_MatchParaErr 0 "Normal" 1 "Abnormal" ;
VAL_ 1159 FCM_VehCfgInfoErr 0 "Normal" 1 "Abnormal" ;
VAL_ 1159 FCM_IntCircFlt 0 "Normal" 1 "Abnormal" ;
VAL_ 1159 FCM_DLCFlt_ESP 0 "Normal" 1 "Abnormal" ;
VAL_ 1159 FCM_DLCFlt_iBooster 0 "Normal" 1 "Abnormal" ;
VAL_ 1159 FCM_DLCFlt_EPS 0 "Normal" 1 "Abnormal" ;
VAL_ 1159 FCM_DLCFlt_YRS 0 "Normal" 1 "Abnormal" ;
VAL_ 1159 FCM_DLCFlt_BCM 0 "Normal" 1 "Abnormal" ;
VAL_ 1159 FCM_DLCFlt_ECC 0 "Normal" 1 "Abnormal" ;
VAL_ 1159 FCM_DLCFlt_TBOX 0 "Normal" 1 "Abnormal" ;
VAL_ 1159 FCM_DLCFlt_CIM 0 "Normal" 1 "Abnormal" ;
VAL_ 1159 FCM_DLCFlt_ICC 0 "Normal" 1 "Abnormal" ;
VAL_ 1159 FCM_DLCFlt_MRR 0 "Normal" 1 "Abnormal" ;
VAL_ 1159 FCM_DLCFlt_PEPS 0 "Normal" 1 "Abnormal" ;
VAL_ 1159 FCM_DLCFlt_ADAS 0 "Normal" 1 "Abnormal" ;
VAL_ 1159 FCM_OnlineCalOutOfRng 0 "Normal" 1 "Abnormal" ;
VAL_ 1159 FCM_IniCalOutOfRng 0 "Normal" 1 "Abnormal" ;
VAL_ 1159 FCM_IniCalTimeout 0 "Normal" 1 "Abnormal" ;
VAL_ 1159 FCM_NotCal 0 "Normal" 1 "Abnormal" ;
VAL_ 1159 FCM_OTARdy_Fb 0 "Initial" 1 "Ready" 2 "Not_Ready" 3 "Invalid" ;
VAL_ 1268 TBOX_Sw_upd 0 "Initial" 1 "Flashing" 2 "Coding" 3 "Invalid" ;
VAL_ 1268 TBOX_Flsflg 0 "Initial_Value" 1 "HV_Flash_Mode" 2 "LV_Flash_Mode" 3 "HV_Light_Flash_Mode" 7 "Invalid" ;
VAL_ 1268 TBOX_RemFlsh 0 "Without_Request" 1 "RemFlash_Req_Active" 2 "RemCoding_Req_Active" 3 "Precheck_Req_Active" 7 "Invalid" ;
VAL_ 1268 TBOX_FobdGWPartBUSUDSCom 0 "Initial_value" 1 "Not_allowed" 2 "Recovery" 3 "Void" ;
VAL_ 1268 TBOX_RemChrgInsulFctReq 0 "No_action" 1 "On" 2 "Off" 3 "Reserved" ;
VAL_ 1268 TBOX_EHUSetTrvlMod 0 "Initial_value" 1 "Daily_commuter_mode" 2 "Long-distance_travel_mode" 3 "Reserved" ;
VAL_ 1268 TBOX_ResvACChrgOpenSts 0 "Initial_value" 1 "On" 2 "Off" 3 "Reserved" ;
VAL_ 1268 TBOX_RemKL15PwrOnReq 0 "Init_value" 1 "Request" 2 "No_Request" 3 "Invalid" ;
VAL_ 1268 TBOX_PreCondTriggerReq 0 "no_trigger" 1 "Start_Precond._Battery" 2 "Start_Precond._Battery_+_Cabin" 3 "Start_Precond._Cabin" 4 "Stop_Precond." 5 "Reserved" 6 "Reserved" 7 "Reserved" ;
VAL_ 1268 TBOX_BlowLvlReq 0 "off" 1 "Step1" 2 "Step2" 3 "Step3" 4 "Step4" 5 "Step5" 6 "Step6" 7 "Step7" ;
VAL_ 1268 TBOX_ICC_UpdStrt 0 "Initial_Value" 1 "With_Request" 2 "Reserved" ;
VAL_ 1268 TBOX_VehiMod 0 "Default_Mode" 1 "California_mode" 2 "Pet_mode" 3 "Camping_mode" 4 "Mode4" 5 "Mode5" 6 "Mode6" 7 "Mode7" 8 "Mode8" 9 "Mode9" 10 "Mode10" 11 "Mode11" 12 "Mode12" 13 "Mode13" 14 "Mode14" 15 "Mode15" ;
VAL_ 1268 TBOX_Crash_cfm 0 "No_Crash" 1 "Crash_Happened" 2 "Reserved" 3 "Invalid" ;
VAL_ 1268 TBOX_SchedChrgnReq 0 "Scheduled_Charging_Req_Inactive" 1 "Scheduled_Charging_Req_Active" 2 "Reserved" 3 "Invalid" ;
VAL_ 1287 VCU_OTAVehInhb_QM_Fb 0 "OTA_veh_cond_not_ok" 1 "OTA_veh_cond_ok" 2 "Fault" 3 "Invalid" ;
VAL_ 1287 VCU_OTAVehCdnChk_QM_sts 0 "OTA_veh_cond_not_ok" 1 "OTA_veh_cond_ok" 2 "Fault" 3 "Invalid" ;
VAL_ 1287 VCU_DrvAvl 0 "Invalid" 1 "Valid" ;
VAL_ 1287 VCU_CllsnSigSts 0 "Not_collided" 1 "Collided" ;
VAL_ 1287 VCU_VehSts_GB 0 "Initial_value" 1 "Vehicle_starting" 2 "Flameout" 3 "Other_states" ;
VAL_ 1287 VCU_MCUOverTFlt_GB 0 "Normal" 1 "Abnormal" ;
VAL_ 1287 VCU_DrvrMotOverTFlt_GB 0 "Normal" 1 "Abnormal" ;
VAL_ 1287 VCU_SOCTooLoAlrm 0 "No_fault" 1 "faulty" ;
VAL_ 1287 VCU_SOCJumpAlrm 0 "No_fault" 1 "faulty" ;
VAL_ 1287 VCU_PwrBattPackMismatAlrm 0 "No_fault" 1 "faulty" ;
VAL_ 1287 VCU_SOCTooHiAlrm 0 "No_fault" 1 "faulty" ;
VAL_ 1287 VCU_DCDCEnaCmd 0 "Disable" 1 "Enable" ;
VAL_ 1287 VCU_PwrBattECCEnaCmd 0 "Disable" 1 "Enable" ;
VAL_ 1287 VCU_MstRlyCtrlCmd 0 "Disconnect" 1 "Closed" ;
VAL_ 1287 VCU_GearSig_GB 0 "Neutral" 1 "1st_gear" 2 "2nd_gear" 3 "3rd_gear" 4 "4th_gear" 5 "5th_gear" 6 "6th_gear" 7 "Reserved" 8 "Reserved" 9 "Reserved" 10 "Reserved" 11 "Reserved" 12 "Reserved" 13 "Reverse_gear" 14 "automatic_D_gear" 15 "parking_gear_P" ;
VAL_ 1287 VCU_DrvrMotNr_GB 0 "Initial_value" 1 "1" 2 "2" 3 "3" 4 "4_pieces" 5 "Reserved" 6 "Reserved" 7 "Reserved" 8 "Reserved" 9 "Reserved" 10 "Reserved" 11 "Reserved" 12 "Reserved" 13 "Reserved" 14 "Reserved" 15 "Reserved" ;
VAL_ 1287 VCU_BattVolt 65535 "Invalid" ;
VAL_ 1297 VCU_BMSLVWakeUpSts 0 "Not_waken_up" 1 "waken_up" ;
VAL_ 1297 VCU_ONWakeUpSig 0 "Not_waken_up" 1 "waken_up" ;
VAL_ 1297 VCU_FCWakeUpSig 0 "Not_waken_up" 1 "waken_up" ;
VAL_ 1297 VCU_SCWakeUpSig 0 "Not_waken_up" 1 "waken_up" ;
VAL_ 1297 VCU_RemWakeUpSig 0 "Not_waken_up" 1 "waken_up" ;
VAL_ 1297 VCU_NetWakeUpSig 0 "Not_waken_up" 1 "waken_up" ;
VAL_ 1297 VCU_LVWakeUpSts_PDU 0 "Not_waken_up" 1 "waken_up" ;
VAL_ 1297 VCU_VehEOLFctFlg 0 "Normal_mode" 1 "EOL_mode" ;
VAL_ 1297 VCU_LVWakeUpSts_MCU 0 "Not_waken_up" 1 "waken_up" ;
VAL_ 1297 VCU_PwrAntithefAllwtRdyFlg 0 "READY_allowed" 1 "READY_not_allowed" ;
VAL_ 1297 VCU_LVWakeUpSts_CCU 0 "Not_waken_up" 1 "waken_up" ;
VAL_ 1297 VCU_RemECCEndCmd 0 "Not_ended" 1 "End" ;
VAL_ 1297 VCU_EvChrgElectcLockCtrlCmd 0 "Initial_value" 1 "locking_command_state" 2 "Unlocking_command_state" 3 "Invalid" ;
VAL_ 1297 VCU_RemPwrBattHeatgEndCmd 0 "Not_ended" 1 "End" ;
VAL_ 1297 VCU_RemChrgEndCmd 0 "Not_ended" 1 "End" ;
VAL_ 1297 VCU_V2L_TrAvl 0 "No" 1 "Yes" ;
VAL_ 1297 VCU_RemBattHeatgFailReason 0 "Initial_value" 1 "Current_ambient_battery_disabled_discharge" 2 "Low_SOC" 3 "vehicle_at_ON_gear" 4 "Vehicle_fault" 5 "The_temp_meets_requ,_there_is_no_need_to_remotely_heat_in_the_discharg_state" 6 "Void" 7 "Void" ;
VAL_ 1297 VCU_RemECCEndReason 0 "Initial_value" 1 "When_the_SOC_of_the_vehicle_is_lower_than_5%,_the_remote_A/C_is_prohibited." 2 "The_vehicle_is_powered_on,_and_the_remote_A/C_is_prohibited." 3 "The_A/C_system_of_the_vehicle_is_abnormal,_and_the_remote_A/C_is_prohibited." 4 "Please_turn_on_after_AC_charging_or_preheating_or_insulation" 5 "Void" 6 "Void" 7 "Void" ;
VAL_ 1297 VCU_V2L_ChrgPortAvl 0 "No" 1 "Yes" ;
VAL_ 1297 VCU_RemChrgEndReason 0 "Initial_value" 1 "abnormal_charging_system,_charging_disabled" 2 "Charging_gun_is_not_connected,_charging_is_not_turned_on" 3 "Supply_equipment_is_not_supported,_and_charging_is_forbidden." 4 "Void" 5 "Void" 6 "Void" 7 "Void" ;
VAL_ 1297 VCU_SchedChrgnStsFb 0 "Idle" 1 "Successful" 2 "Failed" 3 "Processing" ;
VAL_ 1297 VCU_V2V_Avl 0 "No" 1 "Yes" ;
VAL_ 1297 VCU_V2H_Avl 0 "No" 1 "Yes" ;
VAL_ 1297 VCU_V2G_Avl 0 "No" 1 "Yes" ;
VAL_ 1297 VCU_VehMod 0 "None" 1 "THM_Preconditioning" 2 "LV_Energy_Management_during_Parking" 3 "HV_Energy_management_during_Parking" 4 "Remote_HVAD_request" 5 "V2L_Dongle" 6 "V2L_Trunc" 7 "V2V" 8 "OTA" 9 "Workshop_Mode" 10 "LV_Energy_Management_during_Wakeup" 11 "Reserved" 12 "Reserved" 13 "Error" 14 "Initialization" 15 "Invalid" ;
VAL_ 1297 VCU_CalSwVers 0 "Reserved" 1 "G6-1" 2 "G6-2" 3 "G6-3" 4 "G6-4" 5 "G6-5" 6 "G6-6" 7 "G6-7" 8 "G6-8" 9 "G6-9" 10 "Reserved" 11 "G4-1" 12 "G4-2" 13 "G4-3" 14 "G4-4" 15 "G4-5" 16 "G4-6" 17 "G4-7" 18 "G4-8" 19 "G4-9" 20 "Reserved" 21 "G3-1" 22 "G3-2" 23 "G3-3" 24 "G3-4" 25 "G3-5" 26 "G3-6" 27 "G3-7" 28 "G3-8" 29 "G3-9" 30 "Reserved" 31 "Reserved" ;
VAL_ 1297 VCU_RemPwrBattPreheatgEndFlg 0 "Not_ended" 1 "End" ;
VAL_ 1297 VCU_VehOperMod 0 "Reserved" 1 "gear_P" 2 "gear_N" 3 "gear_D" 4 "gear_R" 5 "E_position" 6 "zero_torque_transition" 7 "Idle_at_gear_D" 8 "gear_R_idle" 9 "gear_D_coastdown_feedback" 10 "gear_D_braking_feedback" 11 "gear_E_coastdown_feedback" 12 "gear_E_braking_feedback" 13 "D_gear_limp_condition" 14 "R_gear_limp_condition" 15 "immediately_off_high-voltage_condition" 16 "High_voltage_off_delay" 17 "Cruise" 18 "gear_N_limp" 19 "Zero_torque" 20 "gear_S" 21 "Remote_driving_condition" 22 "Reserved" 23 "Reserved" 24 "Reserved" 25 "Reserved" 26 "Reserved" 27 "Reserved" 28 "Reserved" 29 "Reserved" 30 "Reserved" 31 "Reserved" ;
VAL_ 1297 VCU_VehRemRefrshModReq 0 "Initial_value" 1 "Remote_high_voltage_flash" 2 "Remote_low_voltage_flash-writing" 3 "Void" ;
VAL_ 1297 VCU_RemDTCPwrOnReq 0 "No_demand" 1 "In_demand" ;
VAL_ 1329 ICC_TotMilgVld_ODO 0 "Value_OK" 1 "Value_Unreliable" ;
VAL_ 1329 ICC_DispVehSpdUnit 0 "KMH" 1 "MPH" ;
VAL_ 1329 ICC_ADASSigFlt 0 "No_Failure" 1 "Reversible_Failure" 2 "Irrversible_Failure" 3 "Reserved" ;
VAL_ 1329 ICC_DispFlt 0 "No_Error_No_error" 1 "Error_error" ;
VAL_ 1329 ICC_WorkshopMode 0 "Init" 1 "Active" 2 "Inactive" 3 "Invalid" ;
VAL_ 1476 TBOX_OTA_ownCondchk 0 "No_Request" 1 "Request" 3 "Invalid" ;
VAL_ 1476 TBOX_TerminalRemWakeupSig 0 "Not_waken_up" 1 "Waken_up" ;
VAL_ 1476 TBOX_RemSCModReq 0 "No_remote_control" 1 "Turn_on_remote_charging" 2 "Turn_off_remote_charging" 3 "Reserved" ;
VAL_ 1476 TBOX_RemPwrBattOpenHeatgReq 0 "No_remote_control" 1 "Turn_on_remote_power_battery_heating_mode" 2 "Turn_off_remote_power_battery_heating_mode" 3 "Reserved" ;
VAL_ 1476 TBOX_RemPwrBattResvHeatgReq 0 "No_request" 1 "Request" ;
VAL_ 1476 TBOX_RemInsdInfoDispEna 0 "Disable" 1 "Enable" ;
VAL_ 1476 TBOX_RemECCDefrstModReq 0 "No_remote_control" 1 "Turn_on_remote_AC_defrost_mode" 2 "Turn_off_remote_AC_defrost_mode" 3 "Reserved" ;
VAL_ 1476 TBOX_RemECCResvDefrstReq 0 "No_remote_control" 1 "Reserve_remote_AC_deforst_mode" ;
VAL_ 1476 TBOX_RemECCSetT 0 "Inactive" 1 "Low" 2 "Low" 3 "Low" 4 "Low" 5 "Low" 6 "Low" 7 "Low" 8 "Low" 9 "Low" 10 "Low" 11 "Low" 12 "Low" 13 "Low" 14 "Low" 15 "Low" 16 "Low" 17 "Low" 18 "Low" 19 "Low" 20 "Low" 21 "Low" 22 "Low" 23 "Low" 24 "Low" 25 "Low" 26 "Low" 27 "Low" 28 "Low" 29 "Low" 30 "Low" 31 "Low" 32 "Low" 33 "Low" 34 "Low" 35 "Low" 36 "18¡ãC" 37 "18.5¡ãC" 38 "19¡ãC" 39 "19.5¡ãC" 40 "20¡ãC" 41 "20.5¡ãC" 42 "21¡ãC" 43 "21.5¡ãC" 44 "22¡ãC" 45 "22.5¡ãC" 46 "23¡ãC" 47 "23.5¡ãC" 48 "24¡ãC" 49 "24.5¡ãC" 50 "25¡ãC" 51 "25.5¡ãC" 52 "26¡ãC" 53 "26.5¡ãC" 54 "27¡ãC" 55 "27.5¡ãC" 56 "28¡ãC" 57 "28.5¡ãC" 58 "29¡ãC" 59 "29.5¡ãC" 60 "30¡ãC" 61 "30.5¡ãC" 62 "31¡ãC" 63 "31.5¡ãC" 64 "32¡ãC" 65 "High" 66 "High" 67 "High" 68 "High" 69 "High" 70 "High" 71 "High" 72 "High" 73 "High" 74 "High" 75 "High" 76 "High" 77 "High" 78 "High" 79 "High" 80 "High" 81 "High" 82 "High" 83 "High" 84 "High" 85 "High" 86 "High" 87 "High" 88 "High" 89 "High" 90 "High" 91 "High" 92 "High" 93 "High" 94 "High" 95 "High" 96 "High" 97 "High" 98 "High" 99 "High" 100 "High" 101 "High" 102 "High" 103 "High" 104 "High" 105 "High" 106 "High" 107 "High" 108 "High" 109 "High" 110 "High" 111 "High" 112 "High" 113 "High" 114 "High" 115 "High" 116 "High" 117 "High" 118 "High" 119 "High" 120 "High" 121 "High" 122 "High" 123 "High" 124 "High" 125 "High" 126 "High" 127 "High" 128 "High" 129 "High" 130 "High" 131 "High" 132 "High" 133 "High" 134 "High" 135 "High" 136 "High" 137 "High" 138 "High" 139 "High" 140 "High" 141 "High" 142 "High" 143 "High" 144 "High" 145 "High" 146 "High" 147 "High" 148 "High" 149 "High" 150 "High" 151 "High" 152 "High" 153 "High" 154 "High" 155 "High" 156 "High" 157 "High" 158 "High" 159 "High" 160 "High" 161 "High" 162 "High" 163 "High" 164 "High" 165 "High" 166 "High" 167 "High" 168 "High" 169 "High" 170 "High" 171 "High" 172 "High" 173 "High" 174 "High" 175 "High" 176 "High" 177 "High" 178 "High" 179 "High" 180 "High" 181 "High" 182 "High" 183 "High" 184 "High" 185 "High" 186 "High" 187 "High" 188 "High" 189 "High" 190 "High" 191 "High" 192 "High" 193 "High" 194 "High" 195 "High" 196 "High" 197 "High" 198 "High" 199 "High" 200 "High" 201 "High" 202 "High" 203 "High" 204 "High" 205 "High" 206 "High" 207 "High" 208 "High" 209 "High" 210 "High" 211 "High" 212 "High" 213 "High" 214 "High" 215 "High" 216 "High" 217 "High" 218 "High" 219 "High" 220 "High" 221 "High" 222 "High" 223 "High" 224 "High" 225 "High" 226 "High" 227 "High" 228 "High" 229 "High" 230 "High" 231 "High" 232 "High" 233 "High" 234 "High" 235 "High" 236 "High" 237 "High" 238 "High" 239 "High" 240 "High" 241 "High" 242 "High" 243 "High" 244 "High" 245 "High" 246 "High" 247 "High" 248 "High" 249 "High" 250 "High" 251 "High" 252 "High" 253 "High" 254 "High" 255 "Invalid" ;
VAL_ 1476 TBOX_RemResvECCSetT 0 "Inactive" 1 "Low" 2 "Low" 3 "Low" 4 "Low" 5 "Low" 6 "Low" 7 "Low" 8 "Low" 9 "Low" 10 "Low" 11 "Low" 12 "Low" 13 "Low" 14 "Low" 15 "Low" 16 "Low" 17 "Low" 18 "Low" 19 "Low" 20 "Low" 21 "Low" 22 "Low" 23 "Low" 24 "Low" 25 "Low" 26 "Low" 27 "Low" 28 "Low" 29 "Low" 30 "Low" 31 "Low" 32 "Low" 33 "Low" 34 "Low" 35 "Low" 36 "18¡ãC" 37 "18.5¡ãC" 38 "19¡ãC" 39 "19.5¡ãC" 40 "20¡ãC" 41 "20.5¡ãC" 42 "21¡ãC" 43 "21.5¡ãC" 44 "22¡ãC" 45 "22.5¡ãC" 46 "23¡ãC" 47 "23.5¡ãC" 48 "24¡ãC" 49 "24.5¡ãC" 50 "25¡ãC" 51 "25.5¡ãC" 52 "26¡ãC" 53 "26.5¡ãC" 54 "27¡ãC" 55 "27.5¡ãC" 56 "28¡ãC" 57 "28.5¡ãC" 58 "29¡ãC" 59 "29.5¡ãC" 60 "30¡ãC" 61 "30.5¡ãC" 62 "31¡ãC" 63 "31.5¡ãC" 64 "32¡ãC" 65 "High" 66 "High" 67 "High" 68 "High" 69 "High" 70 "High" 71 "High" 72 "High" 73 "High" 74 "High" 75 "High" 76 "High" 77 "High" 78 "High" 79 "High" 80 "High" 81 "High" 82 "High" 83 "High" 84 "High" 85 "High" 86 "High" 87 "High" 88 "High" 89 "High" 90 "High" 91 "High" 92 "High" 93 "High" 94 "High" 95 "High" 96 "High" 97 "High" 98 "High" 99 "High" 100 "High" 101 "High" 102 "High" 103 "High" 104 "High" 105 "High" 106 "High" 107 "High" 108 "High" 109 "High" 110 "High" 111 "High" 112 "High" 113 "High" 114 "High" 115 "High" 116 "High" 117 "High" 118 "High" 119 "High" 120 "High" 121 "High" 122 "High" 123 "High" 124 "High" 125 "High" 126 "High" 127 "High" 128 "High" 129 "High" 130 "High" 131 "High" 132 "High" 133 "High" 134 "High" 135 "High" 136 "High" 137 "High" 138 "High" 139 "High" 140 "High" 141 "High" 142 "High" 143 "High" 144 "High" 145 "High" 146 "High" 147 "High" 148 "High" 149 "High" 150 "High" 151 "High" 152 "High" 153 "High" 154 "High" 155 "High" 156 "High" 157 "High" 158 "High" 159 "High" 160 "High" 161 "High" 162 "High" 163 "High" 164 "High" 165 "High" 166 "High" 167 "High" 168 "High" 169 "High" 170 "High" 171 "High" 172 "High" 173 "High" 174 "High" 175 "High" 176 "High" 177 "High" 178 "High" 179 "High" 180 "High" 181 "High" 182 "High" 183 "High" 184 "High" 185 "High" 186 "High" 187 "High" 188 "High" 189 "High" 190 "High" 191 "High" 192 "High" 193 "High" 194 "High" 195 "High" 196 "High" 197 "High" 198 "High" 199 "High" 200 "High" 201 "High" 202 "High" 203 "High" 204 "High" 205 "High" 206 "High" 207 "High" 208 "High" 209 "High" 210 "High" 211 "High" 212 "High" 213 "High" 214 "High" 215 "High" 216 "High" 217 "High" 218 "High" 219 "High" 220 "High" 221 "High" 222 "High" 223 "High" 224 "High" 225 "High" 226 "High" 227 "High" 228 "High" 229 "High" 230 "High" 231 "High" 232 "High" 233 "High" 234 "High" 235 "High" 236 "High" 237 "High" 238 "High" 239 "High" 240 "High" 241 "High" 242 "High" 243 "High" 244 "High" 245 "High" 246 "High" 247 "High" 248 "High" 249 "High" 250 "High" 251 "High" 252 "High" 253 "High" 254 "High" 255 "Invalid" ;
VAL_ 1476 TBOX_4GSigIND 0 "No_signal" 1 "Weak" 2 "Moderate" 3 "Strong" ;
VAL_ 1476 TBOX_Conn_Typ 0 "Not_Connected" 1 "3G_or_4G_LTE_CAT-1_and_below_(downllink_less_than_10_Mbps)" 2 "4G_LTE_CAT-2_and_above_(downlink_greater_than_10_Mbps)" 3 "WiFi_2,4_GHz" 4 "WiFi_5_GHz" 5 "Reserved_for_5G_FR1_(Less_than_1_Gbps)" 6 "Reserved_for_5G_FR2_(Greater_than_1_Gbps)" 7 "Reserved_for_5G_mmWave" ;
VAL_ 1476 TBOX_TSPNotConn 0 "Normal" 1 "fault" ;
VAL_ 1476 TBOX_EHUNotCONN 0 "Normal" 1 "fault" ;
VAL_ 1476 TBOX_WIFIError 0 "Normal" 1 "fault" ;
VAL_ 1476 TBOX_InnerBattError 0 "Normal" 1 "fault" ;
VAL_ 1476 TBOX_VoltLow 0 "Normal" 1 "fault" ;
VAL_ 1476 TBOX_VoltHigh 0 "Normal" 1 "fault" ;
VAL_ 1476 TBOX_4GLoss 0 "Normal" 1 "fault" ;
VAL_ 1476 TBOX_RemSWH_Req 0 "No_request" 1 "SWH_ON" 2 "Reserved" 3 "Invalid" ;
VAL_ 1476 TBOX_OTAInhbReq 0 "No_Inhibit_request" 1 "Inhibit_Request" 2 "Reserved" 3 "Invalid" ;
VAL_ 1583 TBOX_CrtTi_Day 0 "Day1" 30 "Day31" ;
VAL_ 1583 TBOX_CrtTi_Hr 0 "Hour_0" 23 "Hour_23" ;
VAL_ 1583 TBOX_CrtTi_Mins 0 "Mintue_0" 59 "Mintue_59" ;
VAL_ 1583 TBOX_CrtTi_Yr 0 "Year_2015" 255 "Year2270" ;
VAL_ 1583 TBOX_CrtTi_Mth 0 "January" 11 "December" ;
VAL_ 1583 TBOX_CrtTi_Sec 0 "Second_0" 59 "Second_59" ;
SIG_GROUP_ 1065 PKC_NM_0x429 1 : PKC_SrcNodeID PKC_CtrlBitVector_Bit3_NMCoord PKC_UsrData4_PN_Info1 PKC_UsrData1_Bit7_ECUSPEC_AWAKE PKC_UsrData3 PKC_UsrData5_PN_Info2 PKC_UsrData2 PKC_UsrData1_Bit5_IGNITION_AWAKE PKC_UsrData1_Bit6_DIAGN_AWAKE PKC_CtrlBitVector_Bit5_Res PKC_CtrlBitVector_Bit0_RMR PKC_CtrlBitVector_Bit2_Res PKC_CtrlBitVector_Bit4_ActWake PKC_CtrlBitVector_Bit7_Res PKC_UsrData0 PKC_UsrData1_Bit0_IGN_WAKEUP PKC_UsrData1_Bit2_NETWORK_WAKEUP PKC_UsrData1_Bit4_NETWORK_AWAKE PKC_UsrData1_Bit3_ECUSPEC_WAKEUP PKC_UsrData1_Bit1_RESET_WAKEUP PKC_CtrlBitVector_Bit6_PNI PKC_CtrlBitVector_Bit1_Res;
SIG_GROUP_ 1069 ADAS_NM_0x42D 1 : ADAS_SrcNodeID ADAS_CtrlBitVector_Bit0_RMR ADAS_CtrlBitVector_Bit7_Res ADAS_UsrData0 ADAS_CtrlBitVector_Bit1_Res ADAS_UsrData3 ADAS_UsrData1_Bit2_NET_WKUP ADAS_UsrData5_PN_Info2 ADAS_UsrData4_PN_Info1 ADAS_UsrData1_Bit6_DIAGN_AWAKE ADAS_UsrData1_Bit7_ECUSPEC_AWAKE ADAS_UsrData1_Bit5_IGN_AWAKE ADAS_CtrlBitVector_Bit2_Res ADAS_CtrlBitVector_Bit3_NMCoord ADAS_CtrlBitVector_Bit4_ActWake ADAS_CtrlBitVector_Bit5_Res ADAS_CtrlBitVector_Bit6_PNI ADAS_UsrData1_Bit0_IGN_WAKEUP ADAS_UsrData1_Bit1_RESET_WAKEUP ADAS_UsrData1_Bit3_ECUSPEC_WKUP ADAS_UsrData1_Bit4_NETWORK_AWAKE ADAS_UsrData2;
SIG_GROUP_ 1070 FCM_NM_0x42E 1 : FCM_UsrData5_PN_Info2 FCM_UsrData4_PN_Info1 FCM_UsrData3 FCM_UsrData2 FCM_UsrData1_Bit7_ECUSPEC_AWAKE FCM_UsrData0 FCM_UsrData1_Bit1_RESET_WAKEUP FCM_UsrData1_Bit3_ECUSPEC_WAKEUP FCM_UsrData1_Bit6_DIAGN_AWAKE FCM_UsrData1_Bit5_IGNITION_AWAKE FCM_UsrData1_Bit4_NETWORK_AWAKE FCM_UsrData1_Bit2_NETWORK_WAKEUP FCM_UsrData1_Bit0_IGN_WAKEUP FCM_CtrlBitVector_Bit1_Res FCM_CtrlBitVector_Bit5_Res FCM_CtrlBitVector_Bit7_Res FCM_CtrlBitVector_Bit6_PNI FCM_CtrlBitVector_Bit3_NMCoord FCM_CtrlBitVector_Bit4_ActWake FCM_CtrlBitVector_Bit2_Res FCM_CtrlBitVector_Bit0_RMR FCM_SrcNodeID;
SIG_GROUP_ 1086 GW_NM_0x43E 1 : GW_SrcNodeID GW_UsrData5_PN_Info2 GW_CtrlBitVector_Bit5_Res GW_CtrlBitVector_Bit0_RMR GW_CtrlBitVector_Bit1_Res GW_CtrlBitVector_Bit3_NMCoord GW_UsrData4_PN_Info1 GW_UsrData0 GW_CtrlBitVector_Bit7_Res GW_CtrlBitVector_Bit4_ActWake GW_CtrlBitVector_Bit6_PNI GW_UsrData3 GW_UsrData1_Bit1_RESET_WAKEUP GW_UsrData2 GW_UsrData1_Bit7_ECUSPEC_AWAKE GW_UsrData1_Bit2_NETWORK_WAKEUP GW_UsrData1_Bit3_ECUSPEC_WAKEUP GW_UsrData1_Bit6_DIAGN_AWAKE GW_UsrData1_Bit5_IGNITION_AWAKE GW_UsrData1_Bit4_NETWORK_AWAKE GW_UsrData1_Bit0_IGN_WAKEUP GW_CtrlBitVector_Bit2_Res;
SIG_GROUP_ 1159 FCM_0x487 1 : FCM_NotCal FCM_OTARdy_Fb FCM_IniCalTimeout FCM_IniCalOutOfRng FCM_OnlineCalOutOfRng FCM_DLCFlt_PEPS FCM_DLCFlt_ICC FCM_IntCircOutpVoltOverThd FCM_ComLostFlt_BCM FCM_ComLostFlt_iBooster FCM_ComLostFlt_ESP FCM_DLCFlt_ADAS FCM_DLCFlt_MRR FCM_DLCFlt_TBOX FCM_ECUTmpHiTProtn FCM_DLCFlt_ECC FCM_DLCFlt_BCM FCM_DLCFlt_CIM FCM_ChkPublicCANBusOff FCM_BattVoltOverThd FCM_IntCircPrmntFlt FCM_CamBli FCM_IntCircOutpVoltBelowThd FCM_IntCircFlt FCM_MatchParaErr FCM_VehCfgInfoErr FCM_DLCFlt_YRS FCM_DLCFlt_iBooster FCM_DLCFlt_ESP FCM_DLCFlt_EPS FCM_BattVoltBelowThd FCM_ChkPrivateCANBusOff FCM_ChkInvldSig_EPS FCM_ChkInvldSig_CIM FCM_ChkInvldSig_ECC FCM_ChkInvldSig_ICC FCM_ChkInvldSig_PEPS FCM_ChkInvldSig_YRS FCM_ChkInvldSig_ESP FCM_ChkInvldSig_iBooster FCM_ComE2EFlt FCM_ComLostFlt_EPS FCM_ComLostFlt_YRS FCM_ComLostFlt_ICC FCM_ComLostFlt_ADAS FCM_ComLostFlt_PEPS FCM_ComLostFlt_MRR FCM_ComLostFlt_TBOX FCM_ComLostFlt_ECC FCM_ComLostFlt_CIM;
SIG_GROUP_ 1268 TBOX_0x4F4 1 : TBOX_4F4_4F8_CheckSum TBOX_4F4_4F8_AliveCounter TBOX_Sw_upd TBOX_Flsflg TBOX_RemFlsh TBOX_FobdGWPartBUSUDSCom TBOX_RemChrgInsulFctReq TBOX_EHUSetTrvlMod TBOX_ResvACChrgOpenSts TBOX_RemKL15PwrOnReq TBOX_SetChrgEndSOC TBOX_PreCondTriggerReq TBOX_BlowLvlReq TBOX_ICC_UpdStrt TBOX_VehiMod TBOX_Crash_cfm TBOX_SchedChrgnReq;
SIG_GROUP_ 1287 VCU_0x507 1 : VCU_OTAVehInhb_QM_Fb VCU_DrvAvl VCU_CllsnSigSts VCU_BattVolt VCU_VehSts_GB VCU_DrvrMotNr_GB VCU_CCCnctnVolt VCU_MCUOverTFlt_GB VCU_DrvrMotOverTFlt_GB VCU_DCDCOutpVoltCmd VCU_SOCJumpAlrm VCU_GearSig_GB VCU_SOCTooHiAlrm VCU_PwrBattECCEnaCmd VCU_DCDCEnaCmd VCU_MstRlyCtrlCmd VCU_PwrBattPackMismatAlrm VCU_SOCTooLoAlrm VCU_OTAVehCdnChk_QM_sts;
SIG_GROUP_ 1297 VCU_0x511 1 : VCU_BMSLVWakeUpSts VCU_RemDTCPwrOnReq VCU_VehRemRefrshModReq VCU_ONWakeUpSig VCU_V2V_Avl VCU_FCWakeUpSig VCU_SCWakeUpSig VCU_NetWakeUpSig VCU_RemWakeUpSig VCU_LVWakeUpSts_PDU VCU_V2H_Avl VCU_VehEOLFctFlg VCU_PwrAntithefAllwtRdyFlg VCU_LVWakeUpSts_MCU VCU_LVWakeUpSts_CCU VCU_VehOperMod VCU_RemPwrBattPreheatgEndFlg VCU_VehCrtChrgEndSOC VCU_CalSwVers VCU_VehMod VCU_V2G_Avl VCU_RemECCEndCmd VCU_RemBattHeatgFailReason VCU_EvChrgElectcLockCtrlCmd VCU_RemChrgEndReason VCU_SchedChrgnStsFb VCU_RemChrgEndCmd VCU_RemPwrBattHeatgEndCmd VCU_V2L_TrAvl VCU_RemECCEndReason VCU_V2L_ChrgPortAvl;
SIG_GROUP_ 1329 ICC_0x531 1 : ICC_TotMilgVld_ODO ICC_TotMilg_ODO ICC_DispVehSpd ICC_DispFlt ICC_WorkshopMode ICC_DispVehSpdUnit ICC_ADASSigFlt;
SIG_GROUP_ 1476 TBOX_0x5C4 1 : TBOX_RemSCModReq TBOX_RemPwrBattOpenHeatgReq TBOX_RemPwrBattResvHeatgReq TBOX_VoltLow TBOX_OTAInhbReq TBOX_RemInsdInfoDispEna TBOX_RemSOCMax TBOX_RemECCDefrstModReq TBOX_RemResvECCSetT TBOX_RemSWH_Req TBOX_4GLoss TBOX_VoltHigh TBOX_RemECCSetT TBOX_4GSigIND TBOX_Conn_Typ TBOX_WIFIError TBOX_TSPNotConn TBOX_InnerBattError TBOX_EHUNotCONN TBOX_RemECCResvDefrstReq TBOX_TerminalRemWakeupSig TBOX_OTA_ownCondchk;
SIG_GROUP_ 1583 TBOX_0x62F 1 : TBOX_ZoneT TBOX_CrtTi_Day TBOX_CrtTi_Sec TBOX_CrtTi_Mth TBOX_CrtTi_Yr TBOX_CrtTi_Mins TBOX_CrtTi_Hr;
SIG_GROUP_ 1661 FCM_0x67D 1 : FCM_SwVersM FCM_HwVers FCM_PartVers FCM_SwVersS;
SIG_GROUP_ 1760 BCM_0x6E0 1 : BCM_VIN_Byte7 BCM_VIN_Byte6 BCM_VIN_Byte5 BCM_VIN_Byte4 BCM_VIN_Byte3 BCM_VIN_Byte2 BCM_VIN_Byte1;
SIG_GROUP_ 1765 VCU_0x6E5 1 : VCU_VINCod1;
SIG_GROUP_ 1766 VCU_0x6E6 1 : VCU_VINCod2;
SIG_GROUP_ 1767 VCU_0x6E7 1 : VCU_VINCod3;
SIG_GROUP_ 1920 Diag_FCM_Req 1 : FCM_Byte3_Req FCM_TPCI_Req FCM_Byte5_Req FCM_Byte8_Req FCM_Byte7_Req FCM_Byte6_Req FCM_Byte4_Req FCM_Byte2_Req;
SIG_GROUP_ 1928 Diag_FCM_Resp 1 : FCM_TPCI_Resp FCM_Byte8_Resp FCM_Byte7_Resp FCM_Byte6_Resp FCM_Byte5_Resp FCM_Byte4_Resp FCM_Byte3_Resp FCM_Byte2_Resp;
SIG_GROUP_ 2015 Diag_FUN_Req 1 : Tester_TPCI_Req Tester_Byte8_Req Tester_Byte7_Req Tester_Byte6_Req Tester_Byte5_Req Tester_Byte4_Req Tester_Byte3_Req Tester_Byte2_Req;
